VERSION ""

NS_ :

BS_:

BU_: UWB_RL UWB_FRNK UWB_RR UWB_INT DHR DHL UWB_BLE BDC UWB_FL Devtool ROA WPC UWB_TRNK UWB_FR

BO_ 16 WPC_01: 8 WPC
 SG_ C_WPC_NFCDetection : 7|2@0+ (1,0) [0|2] ""  BDC,Devtool
 SG_ C_WPC_NFCReset : 3|1@0+ (1,0) [0|0] ""  BDC

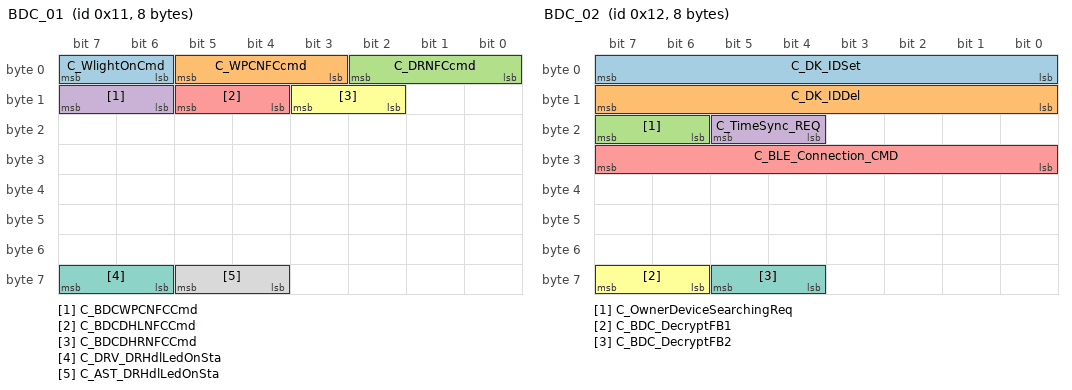
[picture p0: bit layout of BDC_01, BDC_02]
BO_ 17 BDC_01: 8 BDC
 SG_ C_WlightOnCmd : 7|2@0+ (1,0) [0|3] ""  DHL,DHR
 SG_ C_WPCNFCcmd : 5|3@0+ (1,0) [0|7] ""  WPC
 SG_ C_DRNFCcmd : 2|3@0+ (1,0) [0|7] ""  DHL,DHR
 SG_ C_BDCWPCNFCCmd : 15|2@0+ (1,0) [0|0] ""  WPC
 SG_ C_BDCDHLNFCCmd : 13|2@0+ (1,0) [0|0] ""  DHL
 SG_ C_BDCDHRNFCCmd : 11|2@0+ (1,0) [0|0] ""  DHR
 SG_ C_DRV_DRHdlLedOnSta : 63|2@0+ (1,0) [0|0] ""  DHL
 SG_ C_AST_DRHdlLedOnSta : 61|2@0+ (1,0) [0|0] ""  DHR

BO_ 18 BDC_02: 8 BDC
 SG_ C_DK_IDSet : 7|8@0+ (1,0) [0|0] ""  UWB_BLE
 SG_ C_DK_IDDel : 15|8@0+ (1,0) [0|0] ""  UWB_BLE
 SG_ C_OwnerDeviceSearchingReq : 23|2@0+ (1,0) [0|0] ""  UWB_BLE
 SG_ C_TimeSync_REQ : 21|2@0+ (1,0) [0|0] ""  UWB_BLE
 SG_ C_BLE_Connection_CMD : 31|8@0+ (1,0) [0|0] ""  UWB_BLE
 SG_ C_BDC_DecryptFB1 : 63|2@0+ (1,0) [0|0] ""  UWB_BLE
 SG_ C_BDC_DecryptFB2 : 61|2@0+ (1,0) [0|0] ""  UWB_BLE,UWB_FL,UWB_FR,UWB_FRNK,UWB_INT,UWB_RL,UWB_RR,UWB_TRNK

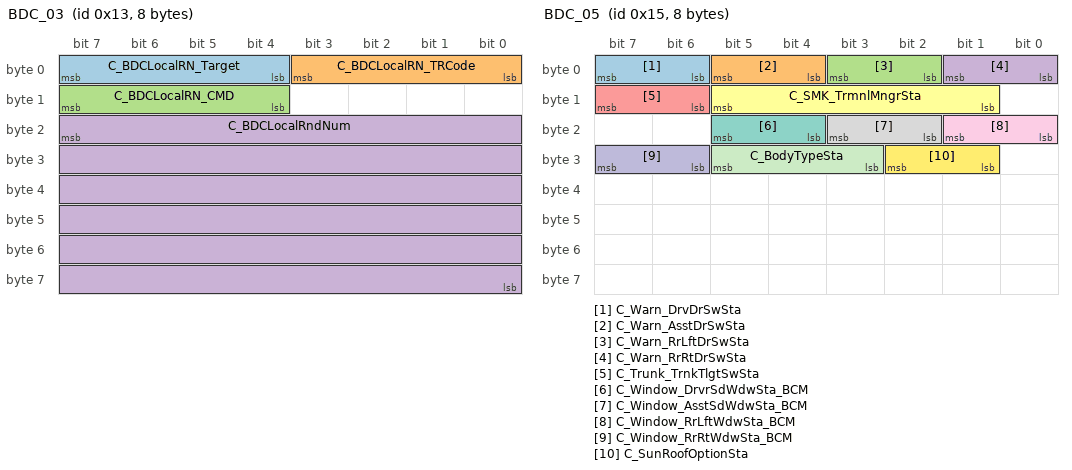
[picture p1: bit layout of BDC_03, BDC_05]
BO_ 19 BDC_03: 8 BDC
 SG_ C_BDCLocalRN_Target : 7|4@0+ (1,0) [0|0] ""  UWB_BLE,UWB_FL,UWB_FR,UWB_FRNK,UWB_INT,UWB_RL,UWB_RR,UWB_TRNK
 SG_ C_BDCLocalRN_TRCode : 3|4@0+ (1,0) [0|0] ""  UWB_BLE,UWB_FL,UWB_FR,UWB_FRNK,UWB_INT,UWB_RL,UWB_RR,UWB_TRNK
 SG_ C_BDCLocalRN_CMD : 15|4@0+ (1,0) [0|0] ""  UWB_BLE,UWB_FL,UWB_FR,UWB_FRNK,UWB_INT,UWB_RL,UWB_RR,UWB_TRNK
 SG_ C_BDCLocalRndNum : 23|48@0+ (1,0) [0|0] ""  UWB_BLE,UWB_FL,UWB_FR,UWB_FRNK,UWB_INT,UWB_RL,UWB_RR,UWB_TRNK

BO_ 20 BDC_04: 8 BDC
 SG_ C_UWB_Ranging_CMD_ID : 7|8@0+ (1,0) [0|0] ""  UWB_BLE,UWB_FL,UWB_FR,UWB_FRNK,UWB_INT,UWB_RL,UWB_RR,UWB_TRNK
 SG_ C_UWB_Ranging_CMD_Value : 15|56@0+ (1,0) [0|0] ""  UWB_BLE,UWB_FL,UWB_FR,UWB_FRNK,UWB_INT,UWB_RL,UWB_RR,UWB_TRNK

BO_ 21 BDC_05: 8 BDC
 SG_ C_Warn_DrvDrSwSta : 7|2@0+ (1,0) [0|0] ""  UWB_BLE
 SG_ C_Warn_AsstDrSwSta : 5|2@0+ (1,0) [0|0] ""  UWB_BLE
 SG_ C_Warn_RrLftDrSwSta : 3|2@0+ (1,0) [0|0] ""  UWB_BLE
 SG_ C_Warn_RrRtDrSwSta : 1|2@0+ (1,0) [0|0] ""  UWB_BLE
 SG_ C_Trunk_TrnkTlgtSwSta : 15|2@0+ (1,0) [0|0] ""  UWB_BLE
 SG_ C_SMK_TrmnlMngrSta : 13|5@0+ (1,0) [0|0] ""  ROA,UWB_BLE
 SG_ C_Window_DrvrSdWdwSta_BCM : 21|2@0+ (1,0) [0|0] ""  UWB_BLE
 SG_ C_Window_AsstSdWdwSta_BCM : 19|2@0+ (1,0) [0|0] ""  UWB_BLE
 SG_ C_Window_RrLftWdwSta_BCM : 17|2@0+ (1,0) [0|0] ""  UWB_BLE
 SG_ C_Window_RrRtWdwSta_BCM : 31|2@0+ (1,0) [0|0] ""  UWB_BLE
 SG_ C_BodyTypeSta : 29|3@0+ (1,0) [0|0] ""  UWB_BLE
 SG_ C_SunRoofOptionSta : 26|2@0+ (1,0) [0|0] ""  ROA,UWB_BLE

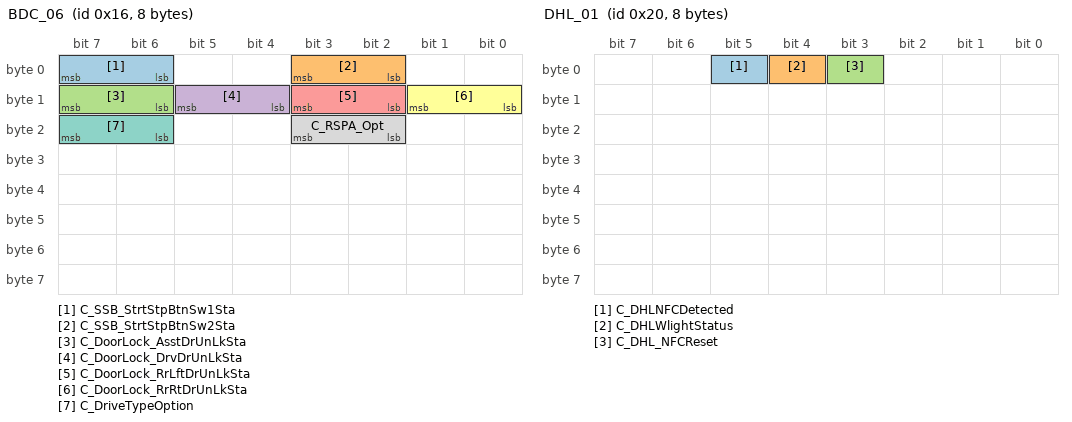
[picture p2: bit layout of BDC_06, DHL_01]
BO_ 22 BDC_06: 8 BDC
 SG_ C_SSB_StrtStpBtnSw1Sta : 7|2@0+ (1,0) [0|0] ""  UWB_BLE
 SG_ C_SSB_StrtStpBtnSw2Sta : 3|2@0+ (1,0) [0|0] ""  UWB_BLE
 SG_ C_DoorLock_AsstDrUnLkSta : 15|2@0+ (1,0) [0|0] ""  UWB_BLE
 SG_ C_DoorLock_DrvDrUnLkSta : 13|2@0+ (1,0) [0|0] ""  UWB_BLE
 SG_ C_DoorLock_RrLftDrUnLkSta : 11|2@0+ (1,0) [0|0] ""  UWB_BLE
 SG_ C_DoorLock_RrRtDrUnLkSta : 9|2@0+ (1,0) [0|0] ""  UWB_BLE
 SG_ C_DriveTypeOption : 23|2@0+ (1,0) [0|0] ""  UWB_BLE
 SG_ C_RSPA_Opt : 19|2@0+ (1,0) [0|0] ""  UWB_BLE

BO_ 31 BDC_20: 8 BDC
 SG_ BDCToBLEEncryptData1 : 7|64@0+ (1,0) [0|0] ""  UWB_BLE

BO_ 32 DHL_01: 8 DHL
 SG_ C_DHLNFCDetected : 5|1@0+ (1,0) [0|1] ""  BDC
 SG_ C_DHLWlightStatus : 4|1@0+ (1,0) [0|1] ""  BDC
 SG_ C_DHL_NFCReset : 3|1@0+ (1,0) [0|0] ""  BDC

BO_ 33 BDC_21: 8 BDC
 SG_ BDCToBLEEncryptData2 : 7|64@0+ (1,0) [0|0] ""  UWB_BLE

BO_ 34 BDC_22: 8 BDC
 SG_ BDCToBLEEncryptData3 : 7|64@0+ (1,0) [0|0] ""  UWB_BLE

BO_ 35 BDC_23: 8 BDC
 SG_ BDCToBLEEncryptData4 : 7|64@0+ (1,0) [0|0] ""  UWB_BLE

BO_ 36 BDC_24: 8 BDC
 SG_ BDCToBLEEncryptData5 : 7|64@0+ (1,0) [0|0] ""  UWB_BLE

BO_ 37 BDC_25: 8 BDC
 SG_ BDCToBLEEncryptData6 : 7|64@0+ (1,0) [0|0] ""  UWB_BLE

BO_ 38 BDC_26: 8 BDC
 SG_ BDCToUWBEncryptData1 : 7|64@0+ (1,0) [0|0] ""  UWB_BLE,UWB_FL,UWB_FR,UWB_FRNK,UWB_INT,UWB_RL,UWB_RR,UWB_TRNK

BO_ 39 BDC_27: 8 BDC
 SG_ BDCToUWBEncryptData2 : 7|64@0+ (1,0) [0|0] ""  UWB_BLE,UWB_FL,UWB_FR,UWB_FRNK,UWB_INT,UWB_RL,UWB_RR,UWB_TRNK

BO_ 40 BDC_28: 8 BDC
 SG_ BDCToUWBEncryptData3 : 7|64@0+ (1,0) [0|0] ""  UWB_BLE,UWB_FL,UWB_FR,UWB_FRNK,UWB_INT,UWB_RL,UWB_RR,UWB_TRNK

BO_ 41 BDC_29: 8 BDC
 SG_ BDCToUWBEncryptData4 : 7|64@0+ (1,0) [0|0] ""  UWB_BLE,UWB_FL,UWB_FR,UWB_FRNK,UWB_INT,UWB_RL,UWB_RR,UWB_TRNK

BO_ 47 BDC_30: 8 BDC
 SG_ BDCToUWBEncryptData5 : 7|64@0+ (1,0) [0|0] ""  UWB_BLE,UWB_FL,UWB_FR,UWB_FRNK,UWB_INT,UWB_RL,UWB_RR,UWB_TRNK

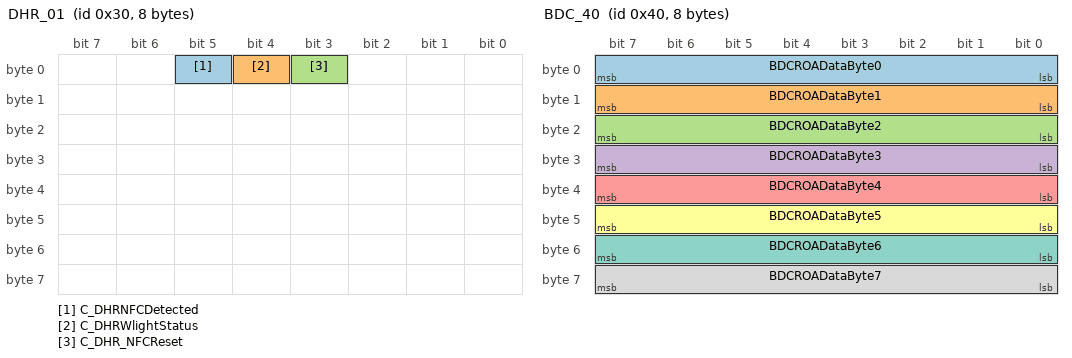
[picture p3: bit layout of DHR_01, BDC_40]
BO_ 48 DHR_01: 8 DHR
 SG_ C_DHRNFCDetected : 5|1@0+ (1,0) [0|1] ""  BDC
 SG_ C_DHRWlightStatus : 4|1@0+ (1,0) [0|1] ""  BDC
 SG_ C_DHR_NFCReset : 3|1@0+ (1,0) [0|0] ""  BDC

BO_ 49 BDC_31: 8 BDC
 SG_ BDCToUWBEncryptData6 : 7|64@0+ (1,0) [0|0] ""  UWB_BLE,UWB_FL,UWB_FR,UWB_FRNK,UWB_INT,UWB_RL,UWB_RR,UWB_TRNK

BO_ 64 BDC_40: 8 BDC
 SG_ BDCROADataByte0 : 7|8@0+ (1,0) [0|0] ""  ROA
 SG_ BDCROADataByte1 : 15|8@0+ (1,0) [0|0] ""  ROA
 SG_ BDCROADataByte2 : 23|8@0+ (1,0) [0|0] ""  ROA
 SG_ BDCROADataByte3 : 31|8@0+ (1,0) [0|0] ""  ROA
 SG_ BDCROADataByte4 : 39|8@0+ (1,0) [0|0] ""  ROA
 SG_ BDCROADataByte5 : 47|8@0+ (1,0) [0|0] ""  ROA
 SG_ BDCROADataByte6 : 55|8@0+ (1,0) [0|0] ""  ROA
 SG_ BDCROADataByte7 : 63|8@0+ (1,0) [0|0] ""  ROA

BO_ 96 BLE_1: 8 UWB_BLE
 SG_ C_BLENewDevicePairingResult : 23|2@0+ (1,0) [0|0] ""  BDC
 SG_ C_BLE_Decrypt_FB : 63|4@0+ (1,0) [0|0] ""  BDC

BO_ 111 BLE_20: 8 UWB_BLE
 SG_ BLEToBDCEncryptData1 : 7|64@0+ (1,0) [0|0] ""  BDC

BO_ 112 BLE_2: 8 UWB_BLE
 SG_ C_Time_Sync1 : 7|64@0+ (1,0) [0|0] ""  BDC,UWB_FL,UWB_FR,UWB_FRNK,UWB_INT,UWB_RL,UWB_RR,UWB_TRNK

BO_ 113 BLE_21: 8 UWB_BLE
 SG_ BLEToBDCEncryptData2 : 7|64@0+ (1,0) [0|0] ""  BDC

BO_ 114 BLE_22: 8 UWB_BLE
 SG_ BLEToBDCEncryptData3 : 7|64@0+ (1,0) [0|0] ""  BDC

BO_ 115 BLE_23: 8 UWB_BLE
 SG_ BLEToBDCEncryptData4 : 7|64@0+ (1,0) [0|0] ""  BDC

BO_ 116 BLE_24: 8 UWB_BLE
 SG_ BLEToBDCEncryptData5 : 7|64@0+ (1,0) [0|0] ""  BDC

BO_ 117 BLE_25: 8 UWB_BLE
 SG_ BLEToBDCEncryptData6 : 7|64@0+ (1,0) [0|0] ""  BDC

BO_ 128 BLE_3: 8 UWB_BLE
 SG_ C_Time_Sync2 : 7|64@0+ (1,0) [0|0] ""  BDC,UWB_FL,UWB_FR,UWB_FRNK,UWB_INT,UWB_RL,UWB_RR,UWB_TRNK

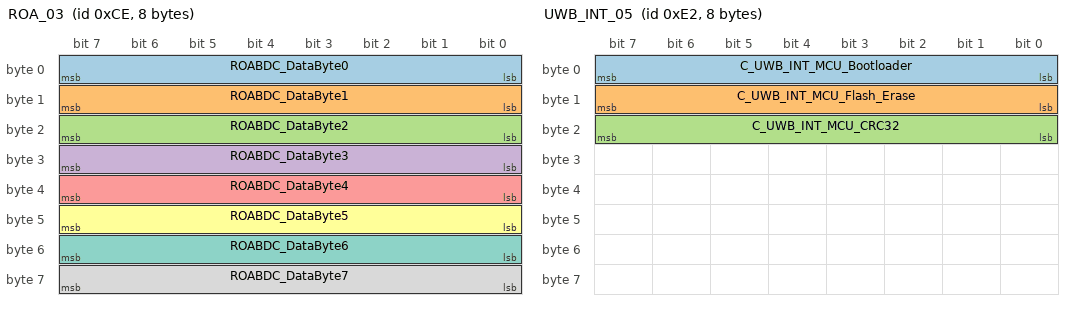
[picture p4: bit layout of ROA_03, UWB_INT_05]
BO_ 206 ROA_03: 8 ROA
 SG_ ROABDC_DataByte0 : 7|8@0+ (1,0) [0|0] ""  BDC
 SG_ ROABDC_DataByte1 : 15|8@0+ (1,0) [0|0] ""  BDC
 SG_ ROABDC_DataByte2 : 23|8@0+ (1,0) [0|0] ""  BDC
 SG_ ROABDC_DataByte3 : 31|8@0+ (1,0) [0|0] ""  BDC
 SG_ ROABDC_DataByte4 : 39|8@0+ (1,0) [0|0] ""  BDC
 SG_ ROABDC_DataByte5 : 47|8@0+ (1,0) [0|0] ""  BDC
 SG_ ROABDC_DataByte6 : 55|8@0+ (1,0) [0|0] ""  BDC
 SG_ ROABDC_DataByte7 : 63|8@0+ (1,0) [0|0] ""  BDC

BO_ 209 UWB_MASTER_01: 8 UWB_BLE
 SG_ C_UWB_MASTER_Decrypt_FB : 63|4@0+ (1,0) [0|0] ""  BDC

BO_ 210 UWB_MASTER_04: 8 UWB_BLE
 SG_ C_UWB_MASTER_To_BDCFOBRSDResul : 7|64@0+ (1,0) [0|0] ""  BDC

BO_ 211 UWB_MASTER_05: 8 UWB_BLE
 SG_ C_UWB_MCU_OTA_Cmd : 7|4@0+ (1,0) [0|0] ""  UWB_FL,UWB_FR,UWB_FRNK,UWB_INT,UWB_RL,UWB_RR,UWB_TRNK

BO_ 212 UWB_MASTER_06: 8 UWB_BLE
 SG_ C_UWB_IC_OTA_Cmd : 15|4@0+ (1,0) [0|0] ""  UWB_FL,UWB_FR,UWB_FRNK,UWB_INT,UWB_RL,UWB_RR,UWB_TRNK

BO_ 213 UWB_MASTER_07: 8 UWB_BLE
 SG_ C_UWB_MCU_Download_Data : 7|64@0+ (1,0) [0|0] ""  UWB_FL,UWB_FR,UWB_FRNK,UWB_INT,UWB_RL,UWB_RR,UWB_TRNK

BO_ 214 UWB_MASTER_08: 8 UWB_BLE
 SG_ C_UWB_IC_Download_Data : 7|64@0+ (1,0) [0|0] ""  UWB_FL,UWB_FR,UWB_FRNK,UWB_INT,UWB_RL,UWB_RR,UWB_TRNK

BO_ 224 UWB_INT_01: 8 UWB_INT
 SG_ C_UWB_INT_Decrypt_FB : 63|4@0+ (1,0) [0|0] ""  BDC,UWB_BLE

BO_ 225 UWB_INT_04: 8 UWB_INT
 SG_ C_UWB_INT_To_BDCFOBRSDResult : 7|64@0+ (1,0) [0|0] ""  BDC

BO_ 226 UWB_INT_05: 8 UWB_INT
 SG_ C_UWB_INT_MCU_Bootloader : 7|8@0+ (1,0) [0|0] ""  UWB_BLE
 SG_ C_UWB_INT_MCU_Flash_Erase : 15|8@0+ (1,0) [0|0] ""  UWB_BLE
 SG_ C_UWB_INT_MCU_CRC32 : 23|8@0+ (1,0) [0|0] ""  UWB_BLE

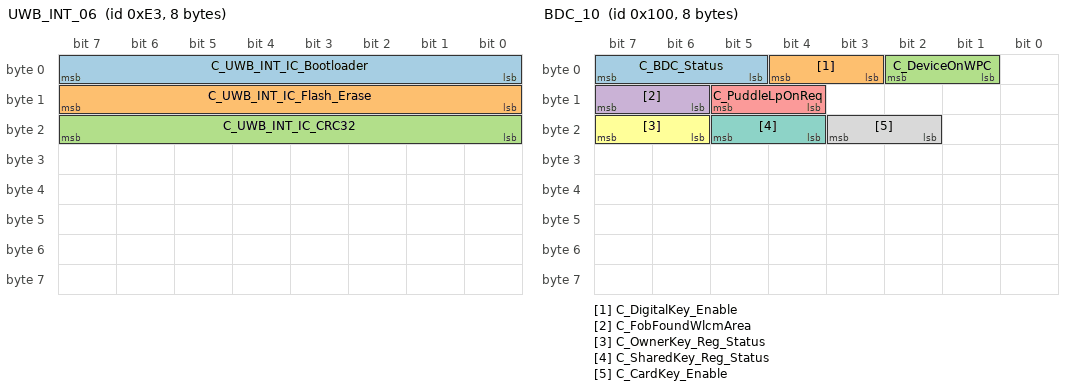
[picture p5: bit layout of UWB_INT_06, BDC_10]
BO_ 227 UWB_INT_06: 8 UWB_INT
 SG_ C_UWB_INT_IC_Bootloader : 7|8@0+ (1,0) [0|0] ""  UWB_BLE
 SG_ C_UWB_INT_IC_Flash_Erase : 15|8@0+ (1,0) [0|0] ""  UWB_BLE
 SG_ C_UWB_INT_IC_CRC32 : 23|8@0+ (1,0) [0|0] ""  UWB_BLE

BO_ 235 UWB_INT_03: 8 UWB_INT
 SG_ C_UWB_INT_To_MasterEncData2 : 7|64@0+ (1,0) [0|0] ""  UWB_BLE

BO_ 256 BDC_10: 8 BDC
 SG_ C_BDC_Status : 7|3@0+ (1,0) [0|7] ""  DHL,DHR,UWB_BLE,UWB_FL,UWB_FR,UWB_FRNK,UWB_INT,UWB_RL,UWB_RR,UWB_TRNK,WPC
 SG_ C_DigitalKey_Enable : 4|2@0+ (1,0) [0|3] ""  DHL,DHR,UWB_BLE,UWB_FL,UWB_FR,UWB_FRNK,UWB_INT,UWB_RL,UWB_RR,UWB_TRNK
 SG_ C_DeviceOnWPC : 2|2@0+ (1,0) [0|0] ""  Devtool,WPC
 SG_ C_FobFoundWlcmArea : 15|2@0+ (1,0) [0|3] ""  DHL,DHR
 SG_ C_PuddleLpOnReq : 13|2@0+ (1,0) [0|0] ""  DHL,DHR
 SG_ C_OwnerKey_Reg_Status : 23|2@0+ (1,0) [0|0] ""  DHL,DHR,UWB_BLE,UWB_FL,UWB_FR,UWB_FRNK,UWB_INT,UWB_RL,UWB_RR,UWB_TRNK
 SG_ C_SharedKey_Reg_Status : 21|2@0+ (1,0) [0|0] ""  DHL,DHR,UWB_BLE,UWB_FL,UWB_FR,UWB_FRNK,UWB_INT,UWB_RL,UWB_RR,UWB_TRNK
 SG_ C_CardKey_Enable : 19|2@0+ (1,0) [0|3] ""  DHL,DHR

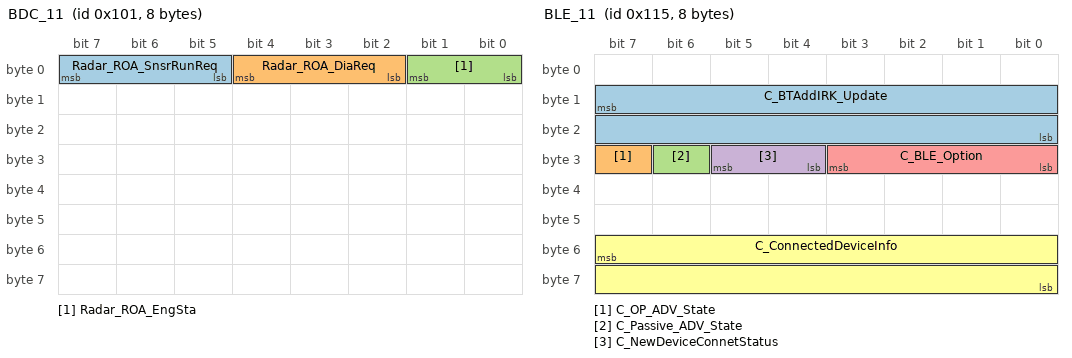
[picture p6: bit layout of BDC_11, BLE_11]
BO_ 257 BDC_11: 8 BDC
 SG_ Radar_ROA_SnsrRunReq : 7|3@0+ (1,0) [0|7] ""  ROA
 SG_ Radar_ROA_DiaReq : 4|3@0+ (1,0) [0|7] ""  ROA
 SG_ Radar_ROA_EngSta : 1|2@0+ (1,0) [0|3] ""  ROA

BO_ 272 WPC_10: 8 WPC
 SG_ C_WPC_Status : 7|3@0+ (1,0) [0|7] ""  BDC,Devtool
 SG_ C_WPCNFC_Option : 15|2@0+ (1,0) [0|3] ""  BDC

BO_ 277 BLE_11: 8 UWB_BLE
 SG_ C_BTAddIRK_Update : 15|16@0+ (1,0) [0|0] ""  BDC
 SG_ C_OP_ADV_State : 31|1@0+ (1,0) [0|0] ""  BDC
 SG_ C_Passive_ADV_State : 30|1@0+ (1,0) [0|0] ""  BDC
 SG_ C_NewDeviceConnetStatus : 29|2@0+ (1,0) [0|0] ""  BDC
 SG_ C_BLE_Option : 27|4@0+ (1,0) [0|0] ""  BDC
 SG_ C_ConnectedDeviceInfo : 55|16@0+ (1,0) [0|0] ""  BDC

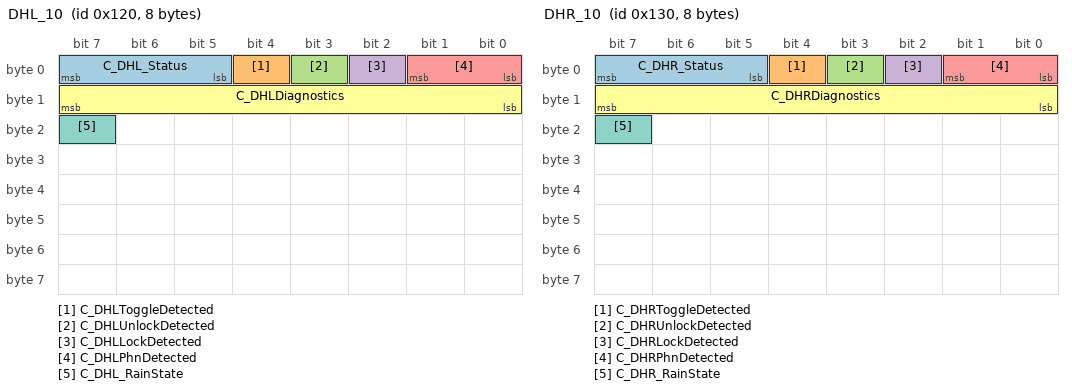
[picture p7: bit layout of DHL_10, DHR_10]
BO_ 288 DHL_10: 8 DHL
 SG_ C_DHL_Status : 7|3@0+ (1,0) [0|7] ""  BDC
 SG_ C_DHLToggleDetected : 4|1@0+ (1,0) [0|0] ""  BDC,UWB_BLE
 SG_ C_DHLUnlockDetected : 3|1@0+ (1,0) [0|1] ""  BDC,UWB_BLE
 SG_ C_DHLLockDetected : 2|1@0+ (1,0) [0|1] ""  BDC,UWB_BLE
 SG_ C_DHLPhnDetected : 1|2@0+ (1,0) [0|0] ""  BDC
 SG_ C_DHLDiagnostics : 15|8@0+ (1,0) [0|0] ""  BDC
 SG_ C_DHL_RainState : 23|1@0+ (1,0) [0|0] ""  BDC

BO_ 304 DHR_10: 8 DHR
 SG_ C_DHR_Status : 7|3@0+ (1,0) [0|7] ""  BDC
 SG_ C_DHRToggleDetected : 4|1@0+ (1,0) [0|1] ""  BDC,UWB_BLE
 SG_ C_DHRUnlockDetected : 3|1@0+ (1,0) [0|1] ""  BDC,UWB_BLE
 SG_ C_DHRLockDetected : 2|1@0+ (1,0) [0|1] ""  BDC,UWB_BLE
 SG_ C_DHRPhnDetected : 1|2@0+ (1,0) [0|0] ""  BDC
 SG_ C_DHRDiagnostics : 15|8@0+ (1,0) [0|0] ""  BDC
 SG_ C_DHR_RainState : 23|1@0+ (1,0) [0|1] ""  BDC

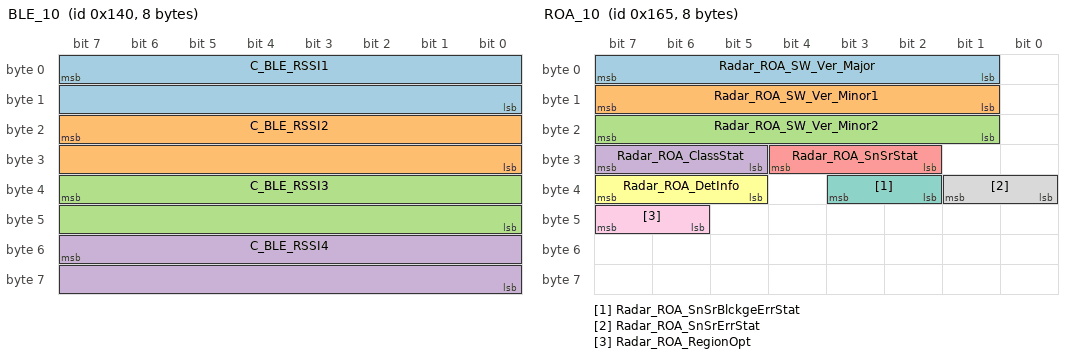
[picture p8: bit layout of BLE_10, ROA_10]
BO_ 320 BLE_10: 8 UWB_BLE
 SG_ C_BLE_RSSI1 : 7|16@0+ (1,0) [0|0] ""  BDC
 SG_ C_BLE_RSSI2 : 23|16@0+ (1,0) [0|0] ""  BDC
 SG_ C_BLE_RSSI3 : 39|16@0+ (1,0) [0|0] ""  BDC
 SG_ C_BLE_RSSI4 : 55|16@0+ (1,0) [0|0] ""  BDC

BO_ 353 UWB_FRNK_01: 8 UWB_FRNK
 SG_ C_UWB_FRNK_Decrypt_FB : 63|4@0+ (1,0) [0|0] ""  BDC,UWB_BLE

BO_ 354 UWB_FRNK_02: 8 UWB_FRNK
 SG_ C_UWB_FRNK_To_MasterEncData1 : 7|64@0+ (1,0) [0|0] ""  UWB_BLE

BO_ 355 UWB_FRNK_03: 8 UWB_FRNK
 SG_ C_UWB_FRNK_To_MasterEncData2 : 7|64@0+ (1,0) [0|0] ""  UWB_BLE

BO_ 356 UWB_FRNK_04: 8 UWB_FRNK
 SG_ C_UWB_FRNK_To_BDCFOBRSDResult : 7|64@0+ (1,0) [0|0] ""  BDC

BO_ 357 ROA_10: 8 ROA
 SG_ Radar_ROA_SW_Ver_Major : 7|7@0+ (1,0) [0|127] ""  BDC
 SG_ Radar_ROA_SW_Ver_Minor1 : 15|7@0+ (1,0) [0|127] ""  BDC
 SG_ Radar_ROA_SW_Ver_Minor2 : 23|7@0+ (1,0) [0|127] ""  BDC
 SG_ Radar_ROA_ClassStat : 31|3@0+ (1,0) [0|7] ""  BDC
 SG_ Radar_ROA_SnSrStat : 28|3@0+ (1,0) [0|7] ""  BDC
 SG_ Radar_ROA_DetInfo : 39|3@0+ (1,0) [0|7] ""  BDC
 SG_ Radar_ROA_SnSrBlckgeErrStat : 35|2@0+ (1,0) [0|3] ""  BDC
 SG_ Radar_ROA_SnSrErrStat : 33|2@0+ (1,0) [0|3] ""  BDC
 SG_ Radar_ROA_RegionOpt : 47|2@0+ (1,0) [0|3] ""  BDC

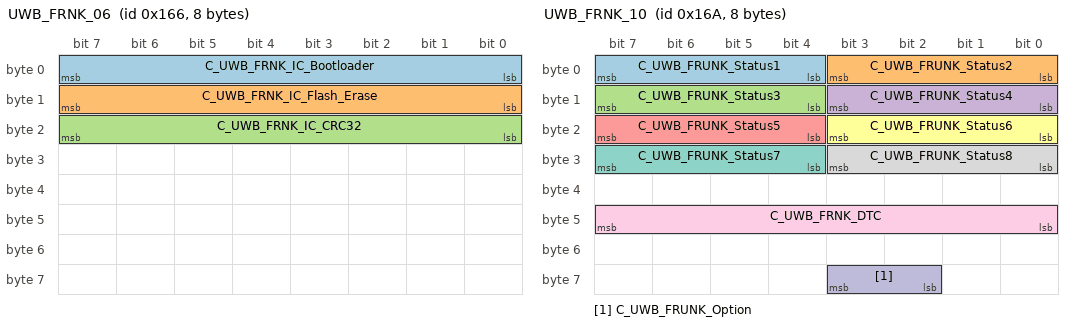
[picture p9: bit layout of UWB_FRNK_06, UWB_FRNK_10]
BO_ 358 UWB_FRNK_06: 8 UWB_FRNK
 SG_ C_UWB_FRNK_IC_Bootloader : 7|8@0+ (1,0) [0|0] ""  UWB_BLE
 SG_ C_UWB_FRNK_IC_Flash_Erase : 15|8@0+ (1,0) [0|0] ""  UWB_BLE
 SG_ C_UWB_FRNK_IC_CRC32 : 23|8@0+ (1,0) [0|0] ""  UWB_BLE

BO_ 362 UWB_FRNK_10: 8 UWB_FRNK
 SG_ C_UWB_FRUNK_Status1 : 7|4@0+ (1,0) [0|7] ""  BDC,UWB_BLE
 SG_ C_UWB_FRUNK_Status2 : 3|4@0+ (1,0) [0|7] ""  BDC,UWB_BLE
 SG_ C_UWB_FRUNK_Status3 : 15|4@0+ (1,0) [0|7] ""  BDC,UWB_BLE
 SG_ C_UWB_FRUNK_Status4 : 11|4@0+ (1,0) [0|7] ""  BDC,UWB_BLE
 SG_ C_UWB_FRUNK_Status5 : 23|4@0+ (1,0) [0|7] ""  BDC,UWB_BLE
 SG_ C_UWB_FRUNK_Status6 : 19|4@0+ (1,0) [0|7] ""  BDC,UWB_BLE
 SG_ C_UWB_FRUNK_Status7 : 31|4@0+ (1,0) [0|7] ""  BDC,UWB_BLE
 SG_ C_UWB_FRUNK_Status8 : 27|4@0+ (1,0) [0|7] ""  BDC,UWB_BLE
 SG_ C_UWB_FRNK_DTC : 47|8@0+ (1,0) [0|0] ""  UWB_BLE
 SG_ C_UWB_FRUNK_Option : 59|2@0+ (1,0) [0|3] ""  BDC,UWB_BLE

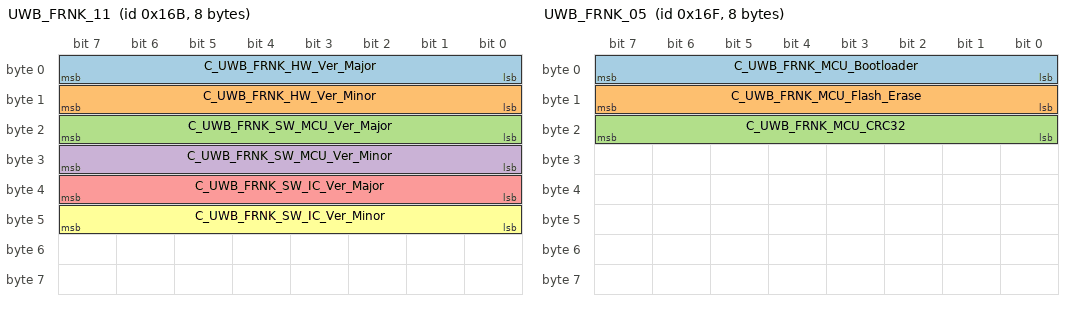
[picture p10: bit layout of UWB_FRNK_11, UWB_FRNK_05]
BO_ 363 UWB_FRNK_11: 8 UWB_FRNK
 SG_ C_UWB_FRNK_HW_Ver_Major : 7|8@0+ (1,0) [0|7] ""  UWB_BLE
 SG_ C_UWB_FRNK_HW_Ver_Minor : 15|8@0+ (1,0) [0|7] ""  UWB_BLE
 SG_ C_UWB_FRNK_SW_MCU_Ver_Major : 23|8@0+ (1,0) [0|7] ""  UWB_BLE
 SG_ C_UWB_FRNK_SW_MCU_Ver_Minor : 31|8@0+ (1,0) [0|7] ""  UWB_BLE
 SG_ C_UWB_FRNK_SW_IC_Ver_Major : 39|8@0+ (1,0) [0|7] ""  UWB_BLE
 SG_ C_UWB_FRNK_SW_IC_Ver_Minor : 47|8@0+ (1,0) [0|7] ""  UWB_BLE

BO_ 367 UWB_FRNK_05: 8 UWB_FRNK
 SG_ C_UWB_FRNK_MCU_Bootloader : 7|8@0+ (1,0) [0|0] ""  UWB_BLE
 SG_ C_UWB_FRNK_MCU_Flash_Erase : 15|8@0+ (1,0) [0|0] ""  UWB_BLE
 SG_ C_UWB_FRNK_MCU_CRC32 : 23|8@0+ (1,0) [0|0] ""  UWB_BLE

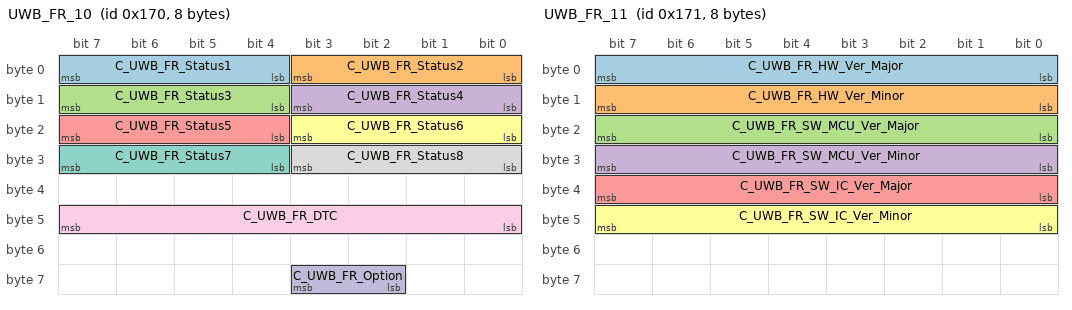
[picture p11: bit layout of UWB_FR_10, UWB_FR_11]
BO_ 368 UWB_FR_10: 8 UWB_FR
 SG_ C_UWB_FR_Status1 : 7|4@0+ (1,0) [0|7] ""  BDC,UWB_BLE
 SG_ C_UWB_FR_Status2 : 3|4@0+ (1,0) [0|7] ""  BDC,UWB_BLE
 SG_ C_UWB_FR_Status3 : 15|4@0+ (1,0) [0|7] ""  BDC,UWB_BLE
 SG_ C_UWB_FR_Status4 : 11|4@0+ (1,0) [0|7] ""  BDC,UWB_BLE
 SG_ C_UWB_FR_Status5 : 23|4@0+ (1,0) [0|7] ""  BDC,UWB_BLE
 SG_ C_UWB_FR_Status6 : 19|4@0+ (1,0) [0|7] ""  BDC,UWB_BLE
 SG_ C_UWB_FR_Status7 : 31|4@0+ (1,0) [0|7] ""  BDC,UWB_BLE
 SG_ C_UWB_FR_Status8 : 27|4@0+ (1,0) [0|7] ""  BDC,UWB_BLE
 SG_ C_UWB_FR_DTC : 47|8@0+ (1,0) [0|0] ""  UWB_BLE
 SG_ C_UWB_FR_Option : 59|2@0+ (1,0) [0|0] ""  BDC,UWB_BLE

BO_ 369 UWB_FR_11: 8 UWB_FR
 SG_ C_UWB_FR_HW_Ver_Major : 7|8@0+ (1,0) [0|7] ""  UWB_BLE
 SG_ C_UWB_FR_HW_Ver_Minor : 15|8@0+ (1,0) [0|7] ""  UWB_BLE
 SG_ C_UWB_FR_SW_MCU_Ver_Major : 23|8@0+ (1,0) [0|7] ""  UWB_BLE
 SG_ C_UWB_FR_SW_MCU_Ver_Minor : 31|8@0+ (1,0) [0|7] ""  UWB_BLE
 SG_ C_UWB_FR_SW_IC_Ver_Major : 39|8@0+ (1,0) [0|7] ""  UWB_BLE
 SG_ C_UWB_FR_SW_IC_Ver_Minor : 47|8@0+ (1,0) [0|7] ""  UWB_BLE

BO_ 370 UWB_FL_02: 8 UWB_FL
 SG_ C_UWB_FL_To_MaseterEncData1 : 7|64@0+ (1,0) [0|0] ""  UWB_BLE

BO_ 371 UWB_FL_03: 8 UWB_FL
 SG_ C_UWB_FL_To_MasterEncData2 : 7|64@0+ (1,0) [0|0] ""  UWB_BLE

BO_ 372 UWB_FL_04: 8 UWB_FL
 SG_ C_UWB_FL_To_BDCFOBRSDResult : 7|64@0+ (1,0) [0|0] ""  BDC

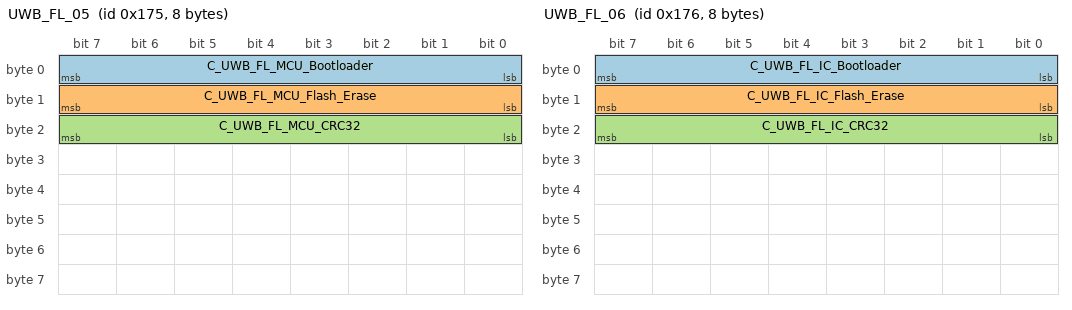
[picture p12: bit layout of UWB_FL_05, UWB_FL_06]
BO_ 373 UWB_FL_05: 8 UWB_FL
 SG_ C_UWB_FL_MCU_Bootloader : 7|8@0+ (1,0) [0|0] ""  UWB_BLE
 SG_ C_UWB_FL_MCU_Flash_Erase : 15|8@0+ (1,0) [0|0] ""  UWB_BLE
 SG_ C_UWB_FL_MCU_CRC32 : 23|8@0+ (1,0) [0|0] ""  UWB_BLE

BO_ 374 UWB_FL_06: 8 UWB_FL
 SG_ C_UWB_FL_IC_Bootloader : 7|8@0+ (1,0) [0|0] ""  UWB_BLE
 SG_ C_UWB_FL_IC_Flash_Erase : 15|8@0+ (1,0) [0|0] ""  UWB_BLE
 SG_ C_UWB_FL_IC_CRC32 : 23|8@0+ (1,0) [0|0] ""  UWB_BLE

BO_ 375 UWB_FL_01: 8 UWB_FL
 SG_ C_UWB_FL_Decrypt_FB : 63|4@0+ (1,0) [0|0] ""  BDC,UWB_BLE

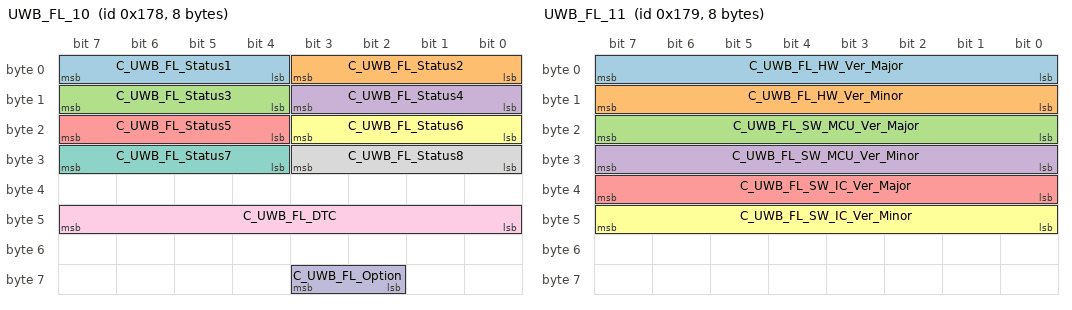
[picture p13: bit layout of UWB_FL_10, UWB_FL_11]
BO_ 376 UWB_FL_10: 8 UWB_FL
 SG_ C_UWB_FL_Status1 : 7|4@0+ (1,0) [0|7] ""  BDC,UWB_BLE
 SG_ C_UWB_FL_Status2 : 3|4@0+ (1,0) [0|7] ""  BDC,UWB_BLE
 SG_ C_UWB_FL_Status3 : 15|4@0+ (1,0) [0|7] ""  BDC,UWB_BLE
 SG_ C_UWB_FL_Status4 : 11|4@0+ (1,0) [0|7] ""  BDC,UWB_BLE
 SG_ C_UWB_FL_Status5 : 23|4@0+ (1,0) [0|7] ""  BDC,UWB_BLE
 SG_ C_UWB_FL_Status6 : 19|4@0+ (1,0) [0|7] ""  BDC,UWB_BLE
 SG_ C_UWB_FL_Status7 : 31|4@0+ (1,0) [0|7] ""  BDC,UWB_BLE
 SG_ C_UWB_FL_Status8 : 27|4@0+ (1,0) [0|7] ""  BDC,UWB_BLE
 SG_ C_UWB_FL_DTC : 47|8@0+ (1,0) [0|0] ""  UWB_BLE
 SG_ C_UWB_FL_Option : 59|2@0+ (1,0) [0|0] ""  BDC,UWB_BLE

BO_ 377 UWB_FL_11: 8 UWB_FL
 SG_ C_UWB_FL_HW_Ver_Major : 7|8@0+ (1,0) [0|7] ""  UWB_BLE
 SG_ C_UWB_FL_HW_Ver_Minor : 15|8@0+ (1,0) [0|7] ""  UWB_BLE
 SG_ C_UWB_FL_SW_MCU_Ver_Major : 23|8@0+ (1,0) [0|7] ""  UWB_BLE
 SG_ C_UWB_FL_SW_MCU_Ver_Minor : 31|8@0+ (1,0) [0|7] ""  UWB_BLE
 SG_ C_UWB_FL_SW_IC_Ver_Major : 39|8@0+ (1,0) [0|7] ""  UWB_BLE
 SG_ C_UWB_FL_SW_IC_Ver_Minor : 47|8@0+ (1,0) [0|7] ""  UWB_BLE

BO_ 378 UWB_MASTER_20: 8 UWB_BLE
 SG_ C_UWB_BLE_MasterEncData1 : 7|64@0+ (1,0) [0|0] ""  Devtool

BO_ 379 UWB_MASTER_21: 8 UWB_BLE
 SG_ C_UWB_BLE_MasterEncData2 : 7|64@0+ (1,0) [0|0] ""  Devtool

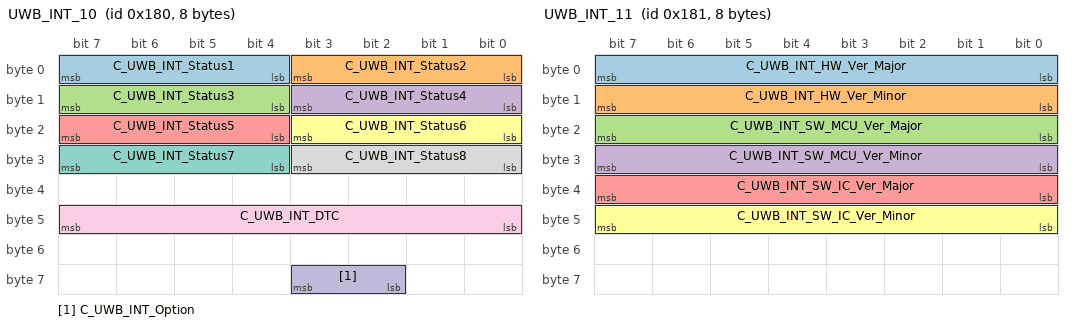
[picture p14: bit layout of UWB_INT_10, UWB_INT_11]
BO_ 384 UWB_INT_10: 8 UWB_INT
 SG_ C_UWB_INT_Status1 : 7|4@0+ (1,0) [0|7] ""  BDC,UWB_BLE
 SG_ C_UWB_INT_Status2 : 3|4@0+ (1,0) [0|7] ""  BDC,UWB_BLE
 SG_ C_UWB_INT_Status3 : 15|4@0+ (1,0) [0|7] ""  BDC,UWB_BLE
 SG_ C_UWB_INT_Status4 : 11|4@0+ (1,0) [0|7] ""  BDC,UWB_BLE
 SG_ C_UWB_INT_Status5 : 23|4@0+ (1,0) [0|7] ""  BDC,UWB_BLE
 SG_ C_UWB_INT_Status6 : 19|4@0+ (1,0) [0|7] ""  BDC,UWB_BLE
 SG_ C_UWB_INT_Status7 : 31|4@0+ (1,0) [0|7] ""  BDC,UWB_BLE
 SG_ C_UWB_INT_Status8 : 27|4@0+ (1,0) [0|7] ""  BDC,UWB_BLE
 SG_ C_UWB_INT_DTC : 47|8@0+ (1,0) [0|0] ""  UWB_BLE
 SG_ C_UWB_INT_Option : 59|2@0+ (1,0) [0|0] ""  BDC,UWB_BLE

BO_ 385 UWB_INT_11: 8 UWB_INT
 SG_ C_UWB_INT_HW_Ver_Major : 7|8@0+ (1,0) [0|7] ""  UWB_BLE
 SG_ C_UWB_INT_HW_Ver_Minor : 15|8@0+ (1,0) [0|7] ""  UWB_BLE
 SG_ C_UWB_INT_SW_MCU_Ver_Major : 23|8@0+ (1,0) [0|7] ""  UWB_BLE
 SG_ C_UWB_INT_SW_MCU_Ver_Minor : 31|8@0+ (1,0) [0|7] ""  UWB_BLE
 SG_ C_UWB_INT_SW_IC_Ver_Major : 39|8@0+ (1,0) [0|7] ""  UWB_BLE
 SG_ C_UWB_INT_SW_IC_Ver_Minor : 47|8@0+ (1,0) [0|7] ""  UWB_BLE

BO_ 386 UWB_FR_02: 8 UWB_FR
 SG_ C_UWB_FR_To_MasterEncData1 : 7|64@0+ (1,0) [0|0] ""  UWB_BLE

BO_ 387 UWB_FR_01: 8 UWB_FR
 SG_ C_UWB_FR_Decrypt_FB : 63|4@0+ (1,0) [0|0] ""  BDC,UWB_BLE

BO_ 388 UWB_FR_04: 8 UWB_FR
 SG_ C_UWB_FR_To_BDCFOBRSDResult : 7|64@0+ (1,0) [0|0] ""  BDC

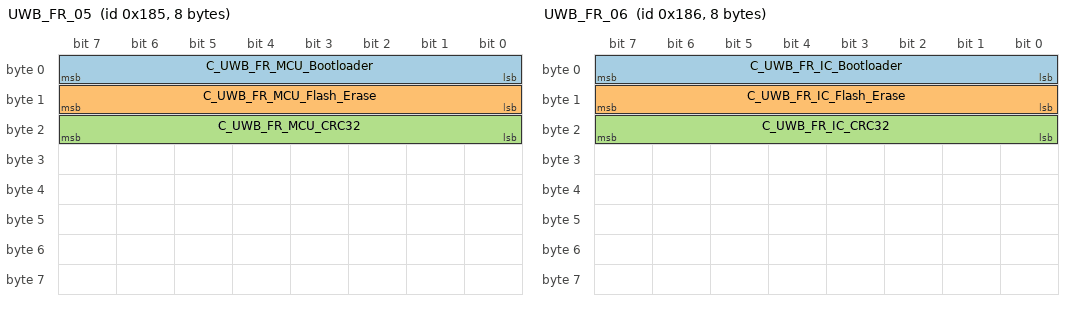
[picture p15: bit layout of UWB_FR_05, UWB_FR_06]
BO_ 389 UWB_FR_05: 8 UWB_FR
 SG_ C_UWB_FR_MCU_Bootloader : 7|8@0+ (1,0) [0|0] ""  UWB_BLE
 SG_ C_UWB_FR_MCU_Flash_Erase : 15|8@0+ (1,0) [0|0] ""  UWB_BLE
 SG_ C_UWB_FR_MCU_CRC32 : 23|8@0+ (1,0) [0|0] ""  UWB_BLE

BO_ 390 UWB_FR_06: 8 UWB_FR
 SG_ C_UWB_FR_IC_Bootloader : 7|8@0+ (1,0) [0|0] ""  UWB_BLE
 SG_ C_UWB_FR_IC_Flash_Erase : 15|8@0+ (1,0) [0|0] ""  UWB_BLE
 SG_ C_UWB_FR_IC_CRC32 : 23|8@0+ (1,0) [0|0] ""  UWB_BLE

BO_ 391 UWB_FR_03: 8 UWB_FR
 SG_ C_UWB_FR_To_MasterEncData2 : 7|64@0+ (1,0) [0|0] ""  UWB_BLE

CM_ BO_ 16 "[EC] On Event and On Change";
CM_ SG_ 16 C_WPC_NFCDetection "Indicate NFC Device is detected or not";
CM_ SG_ 16 C_WPC_NFCReset "NFC Deselect Result";
CM_ BO_ 17 "[EC] On Event and On Change";
CM_ SG_ 17 C_WlightOnCmd "Welcom Light On command from BDC";
CM_ SG_ 17 C_WPCNFCcmd "NFC Searchin Start/Stop command to WPC";
CM_ SG_ 17 C_DRNFCcmd "NFC Searchin Start/Stop command to DHL,DHR";
CM_ SG_ 17 C_BDCWPCNFCCmd "NFC Searchin Start/Stop command to WPC";
CM_ SG_ 17 C_BDCDHLNFCCmd "NFC Searchin Start/Stop command to DHL";
CM_ SG_ 17 C_BDCDHRNFCCmd "NFC Searchin Start/Stop command to DHR";
CM_ SG_ 17 C_DRV_DRHdlLedOnSta "Driver Door Handle Led On Status";
CM_ SG_ 17 C_AST_DRHdlLedOnSta "Assist Door Handle Led On Status";
CM_ BO_ 18 "[EC] On Event and On Change";
CM_ SG_ 18 C_DK_IDSet "BLE Module ID Setting";
CM_ SG_ 18 C_DK_IDDel "BLE Module ID Delete";
CM_ SG_ 18 C_OwnerDeviceSearchingReq "BLE Module Owner Pairing Start Cmd";
CM_ SG_ 18 C_TimeSync_REQ "Timer Sync Reqeust";
CM_ SG_ 18 C_BLE_Connection_CMD "BLE Module Conncetion Cmd";
CM_ SG_ 18 C_BDC_DecryptFB1 "BLE Enc Data Decryption Feed Back";
CM_ SG_ 18 C_BDC_DecryptFB2 "UWB Enc Data Decryption Feed Back";
CM_ BO_ 19 "[EC] On Event and On Change";
CM_ SG_ 19 C_BDCLocalRN_Target "Local Random Number Target Define";
CM_ SG_ 19 C_BDCLocalRN_TRCode "Local Random Number TRCode";
CM_ SG_ 19 C_BDCLocalRN_CMD "Local Random Number CMD";
CM_ SG_ 19 C_BDCLocalRndNum "Random Number for Encyption to BDC Local CAN Modules";
CM_ BO_ 20 "[EC] On Event and On Change";
CM_ SG_ 20 C_UWB_Ranging_CMD_ID "UWB Ranging CMD DKID";
CM_ SG_ 20 C_UWB_Ranging_CMD_Value "UWB Ranging CMD Value";
CM_ BO_ 21 "[PE] Periodic and On Event";
CM_ SG_ 21 C_Warn_DrvDrSwSta "DoorLock_DriverDoorSwitchStatus";
CM_ SG_ 21 C_Warn_AsstDrSwSta "Warn_AssistDoorSwitchStatus";
CM_ SG_ 21 C_Warn_RrLftDrSwSta "Warn_RearLeftDoorSwitchStatus";
CM_ SG_ 21 C_Warn_RrRtDrSwSta "Warn_RearRightDoorSwitchStatus";
CM_ SG_ 21 C_Trunk_TrnkTlgtSwSta "Trunk_TrunkTailgateSwitchStatus";
CM_ SG_ 21 C_SMK_TrmnlMngrSta "Terminal Manager Status";
CM_ SG_ 21 C_Window_DrvrSdWdwSta_BCM "Window_DriverSideWindowStatus";
CM_ SG_ 21 C_Window_AsstSdWdwSta_BCM "Window_AssistantSideWindowStatus";
CM_ SG_ 21 C_Window_RrLftWdwSta_BCM "Window_RearLeftWindowStatus";
CM_ SG_ 21 C_Window_RrRtWdwSta_BCM "Window_RearRightPowerWindowStatus";
CM_ SG_ 21 C_BodyTypeSta "Body & Bumper type Status";
CM_ SG_ 21 C_SunRoofOptionSta "Sunroof Option status";
CM_ BO_ 22 "[PE] Periodic and On Event";
CM_ SG_ 22 C_SSB_StrtStpBtnSw1Sta "SSB_StartStopButtonSwitch1Status ##2G##SMK - SMKmsg19 - C_SSBSW1";
CM_ SG_ 22 C_SSB_StrtStpBtnSw2Sta "SSB_StartStopButtonSwitch2Status ##2G##SMK - SMKmsg19 - C_SSBSW2";
CM_ SG_ 22 C_DoorLock_AsstDrUnLkSta "DoorLock_AssistDoorUnLockStatus ##2G## -  - C_AstUnlockState,DoorLock_AsstDrUnLkSta";
CM_ SG_ 22 C_DoorLock_DrvDrUnLkSta "DoorLock_DriverDoorUnLockStatus ##2G## -  - C_DrvUnlockState,CF_Gway_DrvUnlockState";
CM_ SG_ 22 C_DoorLock_RrLftDrUnLkSta "DoorLock_RearLeftDoorUnLockStatus ##2G## -  - C_RLUnlockState,DoorLock_RrLftDrUnLkSta";
CM_ SG_ 22 C_DoorLock_RrRtDrUnLkSta "DoorLock_RearRightDoorUnLockStatus ##2G## -  - C_RRUnlockState,DoorLock_RrRtDrUnLkSta";
CM_ SG_ 22 C_DriveTypeOption "##2G## -  - C_DriveTypeOption,CF_Gway_DriveTypeOption";
CM_ SG_ 22 C_RSPA_Opt "RSPA_Option";
CM_ BO_ 31 "[EC] On Event and On Change";
CM_ SG_ 31 BDCToBLEEncryptData1 "Encryption Data From BDC to BLE";
CM_ BO_ 32 "[EC] On Event and On Change";
CM_ SG_ 32 C_DHLNFCDetected "LH Door NFC Sensor Input";
CM_ SG_ 32 C_DHLWlightStatus "LH Door Welcome Light Status";
CM_ SG_ 32 C_DHL_NFCReset "LH Door NFC DeSelect Result";
CM_ BO_ 33 "[EC] On Event and On Change";
CM_ SG_ 33 BDCToBLEEncryptData2 "Encryption Data From BDC to BLE";
CM_ BO_ 34 "[EC] On Event and On Change";
CM_ SG_ 34 BDCToBLEEncryptData3 "Encryption Data From BDC to BLE";
CM_ BO_ 35 "[EC] On Event and On Change";
CM_ SG_ 35 BDCToBLEEncryptData4 "Encryption Data From BDC to BLE";
CM_ BO_ 36 "[EC] On Event and On Change";
CM_ SG_ 36 BDCToBLEEncryptData5 "Encryption Data From BDC to BLE";
CM_ BO_ 37 "[EC] On Event and On Change";
CM_ SG_ 37 BDCToBLEEncryptData6 "Encryption Data From BDC to BLE";
CM_ BO_ 38 "[EC] On Event and On Change";
CM_ SG_ 38 BDCToUWBEncryptData1 "Encryption Data From BDC to UWB ALL";
CM_ BO_ 39 "[EC] On Event and On Change";
CM_ SG_ 39 BDCToUWBEncryptData2 "Encryption Data From BDC to UWB ALL";
CM_ BO_ 40 "[EC] On Event and On Change";
CM_ SG_ 40 BDCToUWBEncryptData3 "Encryption Data From BDC to UWB ALL";
CM_ BO_ 41 "[EC] On Event and On Change";
CM_ SG_ 41 BDCToUWBEncryptData4 "Encryption Data From BDC to UWB ALL";
CM_ BO_ 47 "[EC] On Event and On Change";
CM_ SG_ 47 BDCToUWBEncryptData5 "Encryption Data From BDC to UWB ALL";
CM_ BO_ 48 "[EC] On Event and On Change";
CM_ SG_ 48 C_DHRNFCDetected "RH Door NFC Sensor Input";
CM_ SG_ 48 C_DHRWlightStatus "RH Door Welcome Light Status";
CM_ SG_ 48 C_DHR_NFCReset "NFC Deselect Result";
CM_ BO_ 49 "[EC] On Event and On Change";
CM_ SG_ 49 BDCToUWBEncryptData6 "Encryption Data From BDC to UWB ALL";
CM_ BO_ 64 "[EW] On Event and On Write";
CM_ SG_ 64 BDCROADataByte0 "Parameter Data";
CM_ SG_ 64 BDCROADataByte1 "Parameter Data";
CM_ SG_ 64 BDCROADataByte2 "Parameter Data";
CM_ SG_ 64 BDCROADataByte3 "Parameter Data";
CM_ SG_ 64 BDCROADataByte4 "Parameter Data";
CM_ SG_ 64 BDCROADataByte5 "Parameter Data";
CM_ SG_ 64 BDCROADataByte6 "Parameter Data";
CM_ SG_ 64 BDCROADataByte7 "Parameter Data";
CM_ BO_ 96 "[EC] On Event and On Change";
CM_ SG_ 96 C_BLENewDevicePairingResult "BLE New Device Pairing Result";
CM_ SG_ 96 C_BLE_Decrypt_FB "BLE Decryption Feed back";
CM_ BO_ 111 "[EC] On Event and On Change";
CM_ SG_ 111 BLEToBDCEncryptData1 "Encryption Data From BLE to BDC";
CM_ BO_ 112 "[EC] On Event and On Change";
CM_ SG_ 112 C_Time_Sync1 "Timer Sync Data";
CM_ BO_ 113 "[EC] On Event and On Change";
CM_ SG_ 113 BLEToBDCEncryptData2 "Encryption Data From BLE to BDC";
CM_ BO_ 114 "[EC] On Event and On Change";
CM_ SG_ 114 BLEToBDCEncryptData3 "Encryption Data From BLE to BDC";
CM_ BO_ 115 "[EC] On Event and On Change";
CM_ SG_ 115 BLEToBDCEncryptData4 "Encryption Data From BLE to BDC";
CM_ BO_ 116 "[EC] On Event and On Change";
CM_ SG_ 116 BLEToBDCEncryptData5 "Encryption Data From BLE to BDC";
CM_ BO_ 117 "[EC] On Event and On Change";
CM_ SG_ 117 BLEToBDCEncryptData6 "Encryption Data From BLE to BDC";
CM_ BO_ 128 "[EC] On Event and On Change";
CM_ SG_ 128 C_Time_Sync2 "Timer Sync Data";
CM_ BO_ 206 "[EW] On Event and On Write";
CM_ SG_ 206 ROABDC_DataByte0 "Response of Parameter Update";
CM_ SG_ 206 ROABDC_DataByte1 "Response of Parameter Update";
CM_ SG_ 206 ROABDC_DataByte2 "Response of Parameter Update";
CM_ SG_ 206 ROABDC_DataByte3 "Response of Parameter Update";
CM_ SG_ 206 ROABDC_DataByte4 "Response of Parameter Update";
CM_ SG_ 206 ROABDC_DataByte5 "Response of Parameter Update";
CM_ SG_ 206 ROABDC_DataByte6 "Response of Parameter Update";
CM_ SG_ 206 ROABDC_DataByte7 "Response of Parameter Update";
CM_ BO_ 209 "[EC] On Event and On Change";
CM_ SG_ 209 C_UWB_MASTER_Decrypt_FB "UWB Master Decryption Feed Back";
CM_ BO_ 210 "[EC] On Event and On Change";
CM_ SG_ 210 C_UWB_MASTER_To_BDCFOBRSDResul "Distance result of UWB ranging";
CM_ BO_ 211 "[EC] On Event and On Change";
CM_ SG_ 211 C_UWB_MCU_OTA_Cmd "BDC Command for UWB_MCU OTA";
CM_ BO_ 212 "[EC] On Event and On Change";
CM_ SG_ 212 C_UWB_IC_OTA_Cmd "BDC Command for UWB ID OTA";
CM_ BO_ 213 "[EC] On Event and On Change";
CM_ SG_ 213 C_UWB_MCU_Download_Data "UWB MCU Download Data";
CM_ BO_ 214 "[EC] On Event and On Change";
CM_ SG_ 214 C_UWB_IC_Download_Data "UWB IC Download Data";
CM_ BO_ 224 "[EC] On Event and On Change";
CM_ SG_ 224 C_UWB_INT_Decrypt_FB "UWB INT Decryption Feed Back";
CM_ BO_ 225 "[EC] On Event and On Change";
CM_ SG_ 225 C_UWB_INT_To_BDCFOBRSDResult "Distance result of UWB ranging";
CM_ BO_ 226 "[EC] On Event and On Change";
CM_ SG_ 226 C_UWB_INT_MCU_Bootloader "UWB MCU_Bootloader";
CM_ SG_ 226 C_UWB_INT_MCU_Flash_Erase "UWB_MCU_Flash_Erase";
CM_ SG_ 226 C_UWB_INT_MCU_CRC32 "UWB_MCU_CRC32";
CM_ BO_ 227 "[EC] On Event and On Change";
CM_ SG_ 227 C_UWB_INT_IC_Bootloader "UWB_IC_Bootloader";
CM_ SG_ 227 C_UWB_INT_IC_Flash_Erase "UWB_IC_Flash_Erase";
CM_ SG_ 227 C_UWB_INT_IC_CRC32 "UWB_IC_CRC32";
CM_ BO_ 235 "[EW] On Event and On Write";
CM_ SG_ 235 C_UWB_INT_To_MasterEncData2 "Encryption Data From UWB_INT";
CM_ BO_ 256 "[PE] Periodic and On Event";
CM_ SG_ 256 C_BDC_Status "BDC Processing Status";
CM_ SG_ 256 C_DigitalKey_Enable "Digital Key function Enable/Disable by user";
CM_ SG_ 256 C_DeviceOnWPC "Inform device on WPC";
CM_ SG_ 256 C_FobFoundWlcmArea "This signal indicates that there is Fob around the welcome area.
- to inform the door handle (Lock/Unlock touch sensor)";
CM_ SG_ 256 C_PuddleLpOnReq "Puddlelap On request";
CM_ SG_ 256 C_OwnerKey_Reg_Status "Owner Digital Key Register Status";
CM_ SG_ 256 C_SharedKey_Reg_Status "Shared Digital Key Register Status";
CM_ SG_ 256 C_CardKey_Enable "Card Key function Enable/Disable by user";
CM_ BO_ 257 "[PE] Periodic and On Event";
CM_ SG_ 257 Radar_ROA_SnsrRunReq "Sensor detection request";
CM_ SG_ 257 Radar_ROA_DiaReq "Diagnosis/parameter request";
CM_ SG_ 257 Radar_ROA_EngSta "Engine Status";
CM_ BO_ 272 "[PE] Periodic and On Event";
CM_ SG_ 272 C_WPC_Status "WPC Processing Status";
CM_ SG_ 272 C_WPCNFC_Option "WPC NFC Option Applied Signal";
CM_ BO_ 277 "[PE] Periodic and On Event";
CM_ SG_ 277 C_BTAddIRK_Update "BTAddress IRK Update Signal";
CM_ SG_ 277 C_OP_ADV_State "BLE Owner Pairing Advertising State";
CM_ SG_ 277 C_Passive_ADV_State "BLE Passive EN/ST Advertising State";
CM_ SG_ 277 C_NewDeviceConnetStatus "Not Paired Decice Connection Status";
CM_ SG_ 277 C_BLE_Option "BLE Option Applied Signal";
CM_ SG_ 277 C_ConnectedDeviceInfo "BLE Connected Deivces/ID";
CM_ BO_ 288 "[PE] Periodic and On Event";
CM_ SG_ 288 C_DHL_Status "LH Door Processing Status";
CM_ SG_ 288 C_DHLToggleDetected "LH Door Toggle Sensor Input";
CM_ SG_ 288 C_DHLUnlockDetected "LH Door Unlock Sensor Input";
CM_ SG_ 288 C_DHLLockDetected "LH Door Lock Sensor Input";
CM_ SG_ 288 C_DHLPhnDetected "DHL Phone Detected Signal";
CM_ SG_ 288 C_DHLDiagnostics "LH Door NFC_Touch_Diag";
CM_ SG_ 288 C_DHL_RainState "LH Rain Detect Status";
CM_ BO_ 304 "[PE] Periodic and On Event";
CM_ SG_ 304 C_DHR_Status "RH Door Processing Status";
CM_ SG_ 304 C_DHRToggleDetected "RH Door Toggle Sensor Input";
CM_ SG_ 304 C_DHRUnlockDetected "RH Door Unlock Sensor Input";
CM_ SG_ 304 C_DHRLockDetected "RH Door Lock Sensor Input";
CM_ SG_ 304 C_DHRPhnDetected "DHR Phone Detected Signal";
CM_ SG_ 304 C_DHRDiagnostics "RH Door NFC_Touch_Diag";
CM_ SG_ 304 C_DHR_RainState "RH Rain Detect Status";
CM_ BO_ 320 "[PE] Periodic and On Event";
CM_ SG_ 320 C_BLE_RSSI1 "BLE Connection 1 RSSI";
CM_ SG_ 320 C_BLE_RSSI2 "BLE Connection 2 RSSI";
CM_ SG_ 320 C_BLE_RSSI3 "BLE Connection 3 RSSI";
CM_ SG_ 320 C_BLE_RSSI4 "BLE Connection 4 RSSI";
CM_ BO_ 353 "[EC] On Event and On Change";
CM_ SG_ 353 C_UWB_FRNK_Decrypt_FB "UWB FRNK Decryption Feed Back";
CM_ BO_ 354 "[EW] On Event and On Write";
CM_ SG_ 354 C_UWB_FRNK_To_MasterEncData1 "Encryption Data From UWB_FRNK";
CM_ BO_ 355 "[EW] On Event and On Write";
CM_ SG_ 355 C_UWB_FRNK_To_MasterEncData2 "Encryption Data From UWB_FRNK";
CM_ BO_ 356 "[EC] On Event and On Change";
CM_ SG_ 356 C_UWB_FRNK_To_BDCFOBRSDResult "Distance result of UWB ranging";
CM_ BO_ 357 "[PE] Periodic and On Event";
CM_ SG_ 357 Radar_ROA_SW_Ver_Major "Radar ROA SW Version Major";
CM_ SG_ 357 Radar_ROA_SW_Ver_Minor1 "Radar ROA SW Version Minor1";
CM_ SG_ 357 Radar_ROA_SW_Ver_Minor2 "Radar ROA SW Version Minor2";
CM_ SG_ 357 Radar_ROA_ClassStat "ROA Sensor Status for diagnosis";
CM_ SG_ 357 Radar_ROA_SnSrStat "ROA Sensor Status";
CM_ SG_ 357 Radar_ROA_DetInfo "ROA Detection info";
CM_ SG_ 357 Radar_ROA_SnSrBlckgeErrStat "ROA Sensor Blockage Error";
CM_ SG_ 357 Radar_ROA_SnSrErrStat "ROA Internal Error";
CM_ SG_ 357 Radar_ROA_RegionOpt "ROA Euro NCAP Option signal";
CM_ BO_ 358 "[EC] On Event and On Change";
CM_ SG_ 358 C_UWB_FRNK_IC_Bootloader "UWB_IC_Bootloader";
CM_ SG_ 358 C_UWB_FRNK_IC_Flash_Erase "UWB_IC_Flash_Erase";
CM_ SG_ 358 C_UWB_FRNK_IC_CRC32 "UWB_IC_CRC32";
CM_ BO_ 362 "[PE] Periodic and On Event";
CM_ SG_ 362 C_UWB_FRUNK_Status1 "UWB_FRUNK Processing Status 1";
CM_ SG_ 362 C_UWB_FRUNK_Status2 "UWB_FRUNK Processing Status 2";
CM_ SG_ 362 C_UWB_FRUNK_Status3 "UWB_FRUNK Processing Status 3";
CM_ SG_ 362 C_UWB_FRUNK_Status4 "UWB_FRUNK Processing Status 4";
CM_ SG_ 362 C_UWB_FRUNK_Status5 "UWB_FRUNK Processing Status 5";
CM_ SG_ 362 C_UWB_FRUNK_Status6 "UWB_FRUNK Processing Status 6";
CM_ SG_ 362 C_UWB_FRUNK_Status7 "UWB_FRUNK Processing Status 7";
CM_ SG_ 362 C_UWB_FRUNK_Status8 "UWB_FRUNK Processing Status 8";
CM_ SG_ 362 C_UWB_FRNK_DTC "UWB Frunk DTC Data";
CM_ SG_ 362 C_UWB_FRUNK_Option "UWB FRUNK Applied Signal";
CM_ BO_ 363 "[P] Periodic";
CM_ SG_ 363 C_UWB_FRNK_HW_Ver_Major "UWB FRNK HW Version Major";
CM_ SG_ 363 C_UWB_FRNK_HW_Ver_Minor "UWB FRNK HW Version Minor";
CM_ SG_ 363 C_UWB_FRNK_SW_MCU_Ver_Major "UWB FRNK SW MCU Version Major";
CM_ SG_ 363 C_UWB_FRNK_SW_MCU_Ver_Minor "UWB FRNK SW MCU Version Minor";
CM_ SG_ 363 C_UWB_FRNK_SW_IC_Ver_Major "UWB FRNK SW IC Version Major";
CM_ SG_ 363 C_UWB_FRNK_SW_IC_Ver_Minor "UWB FRNK SW IC Version Minor";
CM_ BO_ 367 "[EC] On Event and On Change";
CM_ SG_ 367 C_UWB_FRNK_MCU_Bootloader "UWB MCU_Bootloader";
CM_ SG_ 367 C_UWB_FRNK_MCU_Flash_Erase "UWB_MCU_Flash_Erase";
CM_ SG_ 367 C_UWB_FRNK_MCU_CRC32 "UWB_MCU_CRC32";
CM_ BO_ 368 "[PE] Periodic and On Event";
CM_ SG_ 368 C_UWB_FR_Status1 "UWB_FR Processing Status 1";
CM_ SG_ 368 C_UWB_FR_Status2 "UWB_FR Processing Status 2";
CM_ SG_ 368 C_UWB_FR_Status3 "UWB_FR Processing Status 3";
CM_ SG_ 368 C_UWB_FR_Status4 "UWB_FR Processing Status 4";
CM_ SG_ 368 C_UWB_FR_Status5 "UWB_FR Processing Status 5";
CM_ SG_ 368 C_UWB_FR_Status6 "UWB_FR Processing Status 6";
CM_ SG_ 368 C_UWB_FR_Status7 "UWB_FR Processing Status 7";
CM_ SG_ 368 C_UWB_FR_Status8 "UWB_FR Processing Status 8";
CM_ SG_ 368 C_UWB_FR_DTC "UWB FR DTC Data";
CM_ SG_ 368 C_UWB_FR_Option "UWB FR Applied Signal";
CM_ BO_ 369 "[P] Periodic";
CM_ SG_ 369 C_UWB_FR_HW_Ver_Major "UWB FR HW Version Major";
CM_ SG_ 369 C_UWB_FR_HW_Ver_Minor "UWB FR HW Version Minor";
CM_ SG_ 369 C_UWB_FR_SW_MCU_Ver_Major "UWB FR SW MCU Version Major";
CM_ SG_ 369 C_UWB_FR_SW_MCU_Ver_Minor "UWB FR SW MCU Version Minor";
CM_ SG_ 369 C_UWB_FR_SW_IC_Ver_Major "UWB FR SW IC Version Major";
CM_ SG_ 369 C_UWB_FR_SW_IC_Ver_Minor "UWB FR SW IC Version Minor";
CM_ BO_ 370 "[EW] On Event and On Write";
CM_ SG_ 370 C_UWB_FL_To_MaseterEncData1 "Encryption Data From UWB_FL";
CM_ BO_ 371 "[EW] On Event and On Write";
CM_ SG_ 371 C_UWB_FL_To_MasterEncData2 "Encryption Data From UWB_FL";
CM_ BO_ 372 "[EC] On Event and On Change";
CM_ SG_ 372 C_UWB_FL_To_BDCFOBRSDResult "Distance result of UWB ranging";
CM_ BO_ 373 "[EC] On Event and On Change";
CM_ SG_ 373 C_UWB_FL_MCU_Bootloader "UWB FL_MCU_Bootloader";
CM_ SG_ 373 C_UWB_FL_MCU_Flash_Erase "UWB_FL_MCU_Flash_Erase";
CM_ SG_ 373 C_UWB_FL_MCU_CRC32 "UWB_FL_MCU_CRC32";
CM_ BO_ 374 "[EC] On Event and On Change";
CM_ SG_ 374 C_UWB_FL_IC_Bootloader "UWB_FL_MCU_Bootloader";
CM_ SG_ 374 C_UWB_FL_IC_Flash_Erase "UWB_FL_MCU_Flash_Erase";
CM_ SG_ 374 C_UWB_FL_IC_CRC32 "UWB_FL_MCU_CRC32";
CM_ BO_ 375 "[EC] On Event and On Change";
CM_ SG_ 375 C_UWB_FL_Decrypt_FB "UWB FL Decryption Feed Back";
CM_ BO_ 376 "[PE] Periodic and On Event";
CM_ SG_ 376 C_UWB_FL_Status1 "UWB_FL Processing Status 1";
CM_ SG_ 376 C_UWB_FL_Status2 "UWB_FL Processing Status 2";
CM_ SG_ 376 C_UWB_FL_Status3 "UWB_FL Processing Status 3";
CM_ SG_ 376 C_UWB_FL_Status4 "UWB_FL Processing Status 4";
CM_ SG_ 376 C_UWB_FL_Status5 "UWB_FL Processing Status 5";
CM_ SG_ 376 C_UWB_FL_Status6 "UWB_FL Processing Status 6";
CM_ SG_ 376 C_UWB_FL_Status7 "UWB_FL Processing Status 7";
CM_ SG_ 376 C_UWB_FL_Status8 "UWB_FL Processing Status 8";
CM_ SG_ 376 C_UWB_FL_DTC "UWB FL DTC Data";
CM_ SG_ 376 C_UWB_FL_Option "UWB FL Applied Signal";
CM_ BO_ 377 "[P] Periodic";
CM_ SG_ 377 C_UWB_FL_HW_Ver_Major "UWB FL HW Version Major";
CM_ SG_ 377 C_UWB_FL_HW_Ver_Minor "UWB FL HW Version Minor";
CM_ SG_ 377 C_UWB_FL_SW_MCU_Ver_Major "UWB FL SW MCU Version Major";
CM_ SG_ 377 C_UWB_FL_SW_MCU_Ver_Minor "UWB FL SW MCU Version Minor";
CM_ SG_ 377 C_UWB_FL_SW_IC_Ver_Major "UWB FL SW IC Version Major";
CM_ SG_ 377 C_UWB_FL_SW_IC_Ver_Minor "UWB FL SW IC Version Minor";
CM_ BO_ 378 "[EW] On Event and On Write";
CM_ SG_ 378 C_UWB_BLE_MasterEncData1 "Encryption Data From UWB_BLE Master";
CM_ BO_ 379 "[EW] On Event and On Write";
CM_ SG_ 379 C_UWB_BLE_MasterEncData2 "Encryption Data From UWB_BLE Master";
CM_ BO_ 384 "[PE] Periodic and On Event";
CM_ SG_ 384 C_UWB_INT_Status1 "UWB_INT Processing Status 1";
CM_ SG_ 384 C_UWB_INT_Status2 "UWB_INT Processing Status 2";
CM_ SG_ 384 C_UWB_INT_Status3 "UWB_INT Processing Status 3";
CM_ SG_ 384 C_UWB_INT_Status4 "UWB_INT Processing Status 4";
CM_ SG_ 384 C_UWB_INT_Status5 "UWB_INT Processing Status 5";
CM_ SG_ 384 C_UWB_INT_Status6 "UWB_INT Processing Status 6";
CM_ SG_ 384 C_UWB_INT_Status7 "UWB_INT Processing Status 7";
CM_ SG_ 384 C_UWB_INT_Status8 "UWB_INT Processing Status 8";
CM_ SG_ 384 C_UWB_INT_DTC "UWB INT DTC Data";
CM_ SG_ 384 C_UWB_INT_Option "UWB INT Applied Signal";
CM_ BO_ 385 "[P] Periodic";
CM_ SG_ 385 C_UWB_INT_HW_Ver_Major "UWB INT HW Version Major";
CM_ SG_ 385 C_UWB_INT_HW_Ver_Minor "UWB INT HW Version Minor";
CM_ SG_ 385 C_UWB_INT_SW_MCU_Ver_Major "UWB INT SW MCU Version Major";
CM_ SG_ 385 C_UWB_INT_SW_MCU_Ver_Minor "UWB INT SW MCU Version Minor";
CM_ SG_ 385 C_UWB_INT_SW_IC_Ver_Major "UWB INT SW IC Version Major";
CM_ SG_ 385 C_UWB_INT_SW_IC_Ver_Minor "UWB INT SW IC Version Minor";
CM_ BO_ 386 "[EW] On Event and On Write";
CM_ SG_ 386 C_UWB_FR_To_MasterEncData1 "Encryption Data From UWB_FR";
CM_ BO_ 387 "[EC] On Event and On Change";
CM_ SG_ 387 C_UWB_FR_Decrypt_FB "UWB FR Decryption Feed Back";
CM_ BO_ 388 "[EC] On Event and On Change";
CM_ SG_ 388 C_UWB_FR_To_BDCFOBRSDResult "Distance result of UWB ranging";
CM_ BO_ 389 "[EC] On Event and On Change";
CM_ SG_ 389 C_UWB_FR_MCU_Bootloader "UWB MCU_Bootloader";
CM_ SG_ 389 C_UWB_FR_MCU_Flash_Erase "UWB_MCU_Flash_Erase";
CM_ SG_ 389 C_UWB_FR_MCU_CRC32 "UWB_MCU_CRC32";
CM_ BO_ 390 "[EC] On Event and On Change";
CM_ SG_ 390 C_UWB_FR_IC_Bootloader "UWB_IC_Bootloader";
CM_ SG_ 390 C_UWB_FR_IC_Flash_Erase "UWB_IC_Flash_Erase";
CM_ SG_ 390 C_UWB_FR_IC_CRC32 "UWB_IC_CRC32";
CM_ BO_ 391 "[EW] On Event and On Write";
CM_ SG_ 391 C_UWB_FR_To_MasterEncData2 "Encryption Data From UWB_FR";
BA_DEF_ SG_  "NWM-WakeupAllowed" ENUM  "<n.a.>";
BA_DEF_ BO_  "NWM-Botschaft" ENUM  "No","Yes";
BA_DEF_ BU_  "NWM-Knoten" ENUM  "No","Yes";
BA_DEF_ SG_  "GenSigEnvVarType" ENUM  "int","float","undef";
BA_DEF_ SG_  "GwSigLatencyTime" INT 0 65535;
BA_DEF_ SG_  "GwSigMissingSourceType" ENUM  "Undef","OldValue","DefaultValue","InitialValue";
BA_DEF_ SG_  "SignalCategory" HEX 10 15;
BA_DEF_ SG_  "GenSigSendType" ENUM  "Cyclic","OnWrite","OnWriteWithRepetition","OnChange","OnChangeWithRepetition","IfActive","IfActiveWithRepetition","NoSigSendType";
BA_DEF_ BO_  "GenMsgDelayTime" INT 20 20;
BA_DEF_ BO_  "NmMessage" ENUM  "No","Yes";
BA_DEF_ BO_  "GenMsgILSupport" ENUM  "No","Yes";
BA_DEF_ BO_  "GenMsgNrOfRepetition" INT 0 3;
BA_DEF_ BO_  "GenMsgCycleTimeFast" INT 0 500;
BA_DEF_ BO_  "GenMsgStartDelayTime" INT 0 100;
BA_DEF_ BO_  "GenMsgSendType" ENUM  "Cyclic","not_used","not_used","not_used","not_used","not_used","not_used","not_used","NoMsgSendType";
BA_DEF_ BO_  "GenMsgCycleTime" INT 0 2000;
BA_DEF_ BU_  "GenNodSleepTime" INT 1375 1650;
BA_DEF_ BU_  "NodeLayerModules" STRING ;
BA_DEF_ BU_  "NmNode" ENUM  "No","Yes";
BA_DEF_ BU_  "NmCAN" INT 1 2;
BA_DEF_ BU_  "ILUsed" ENUM  "No","Yes";
BA_DEF_ BU_  "NmStationAddress" HEX 0 255;
BA_DEF_  "GenNWMApBusSleep" STRING ;
BA_DEF_  "GenNWMApCanNormal" STRING ;
BA_DEF_  "GenNWMApCanOff" STRING ;
BA_DEF_  "GenNWMApCanOn" STRING ;
BA_DEF_  "GenNWMApCanSleep" STRING ;
BA_DEF_  "GenNWMApCanWakeUp" STRING ;
BA_DEF_  "GenNWMGotoMode_Awake" STRING ;
BA_DEF_  "GenNWMGotoMode_BusSleep" STRING ;
BA_DEF_  "GenNWMSleepTime" INT 1375 1650;
BA_DEF_  "GenNWMTalkNM" STRING ;
BA_DEF_  "GenEnvVarEndingDsp" STRING ;
BA_DEF_  "GenEnvVarEndingSnd" STRING ;
BA_DEF_  "GenEnvVarPrefix" STRING ;
BA_DEF_  "VersionNumberInternal" INT 0 9999;
BA_DEF_  "VersionNumber" INT 0 999999;
BA_DEF_  "VersionWeek" INT 1 53;
BA_DEF_  "VersionYear" INT 0 9999;
BA_DEF_  "VersionMonth" INT 1 12;
BA_DEF_  "VersionDay" INT 1 31;
BA_DEF_  "BusType" STRING ;
BA_DEF_  "DBName" STRING ;
BA_DEF_  "NmType" STRING ;
BA_DEF_  "NmBaseAddress" HEX 0 2047;
BA_DEF_  "NmMessageCount" INT 0 128;
BA_DEF_  "Manufacturer" STRING ;
BA_DEF_  "Baudrate" INT 100000 500000;
BA_DEF_  "SamplePointMin" INT 55 85;
BA_DEF_  "SamplePointMax" INT 50 85;
BA_DEF_  "SyncJumpWidthMin" INT 1 4;
BA_DEF_  "SyncJumpWidthMax" INT 1 8;
BA_DEF_REL_ BU_SG_REL_  "GenSigTimeoutTime" INT 175 3500;
BA_DEF_DEF_  "NWM-WakeupAllowed" "<n.a.>";
BA_DEF_DEF_  "NWM-Botschaft" "No";
BA_DEF_DEF_  "NWM-Knoten" "Yes";
BA_DEF_DEF_  "GenSigEnvVarType" "undef";
BA_DEF_DEF_  "GwSigLatencyTime" 40;
BA_DEF_DEF_  "GwSigMissingSourceType" "Undef";
BA_DEF_DEF_  "SignalCategory" 12;
BA_DEF_DEF_  "GenSigSendType" "NoSigSendType";
BA_DEF_DEF_  "GenMsgDelayTime" 20;
BA_DEF_DEF_  "NmMessage" "No";
BA_DEF_DEF_  "GenMsgILSupport" "Yes";
BA_DEF_DEF_  "GenMsgNrOfRepetition" 3;
BA_DEF_DEF_  "GenMsgCycleTimeFast" 60;
BA_DEF_DEF_  "GenMsgStartDelayTime" 0;
BA_DEF_DEF_  "GenMsgSendType" "NoMsgSendType";
BA_DEF_DEF_  "GenMsgCycleTime" 200;
BA_DEF_DEF_  "GenNodSleepTime" 1500;
BA_DEF_DEF_  "NodeLayerModules" "oseknm01.dll";
BA_DEF_DEF_  "NmNode" "Yes";
BA_DEF_DEF_  "NmCAN" 1;
BA_DEF_DEF_  "ILUsed" "Yes";
BA_DEF_DEF_  "NmStationAddress" 0;
BA_DEF_DEF_  "GenNWMApBusSleep" "ApplNmCanBusSleep()";
BA_DEF_DEF_  "GenNWMApCanNormal" "ApplNmCanNormal()";
BA_DEF_DEF_  "GenNWMApCanOff" "ApplCanOffline()";
BA_DEF_DEF_  "GenNWMApCanOn" "ApplCanOnline()";
BA_DEF_DEF_  "GenNWMApCanSleep" "ApplNmCanSleep()";
BA_DEF_DEF_  "GenNWMApCanWakeUp" "ApplCanWakeUp()";
BA_DEF_DEF_  "GenNWMGotoMode_Awake" "GotoMode_Awake()";
BA_DEF_DEF_  "GenNWMGotoMode_BusSleep" "GotoMode_BusSleep()";
BA_DEF_DEF_  "GenNWMSleepTime" 1500;
BA_DEF_DEF_  "GenNWMTalkNM" "TalkNM()";
BA_DEF_DEF_  "GenEnvVarEndingDsp" "Dsp_";
BA_DEF_DEF_  "GenEnvVarEndingSnd" "_";
BA_DEF_DEF_  "GenEnvVarPrefix" "Env";
BA_DEF_DEF_  "VersionNumberInternal" 0;
BA_DEF_DEF_  "VersionNumber" 0;
BA_DEF_DEF_  "VersionWeek" 1;
BA_DEF_DEF_  "VersionYear" 0;
BA_DEF_DEF_  "VersionMonth" 1;
BA_DEF_DEF_  "VersionDay" 1;
BA_DEF_DEF_  "BusType" "CAN";
BA_DEF_DEF_  "DBName" "";
BA_DEF_DEF_  "NmType" "Vector";
BA_DEF_DEF_  "NmBaseAddress" 1024;
BA_DEF_DEF_  "NmMessageCount" 128;
BA_DEF_DEF_  "Manufacturer" "HMC";
BA_DEF_DEF_  "Baudrate" 500000;
BA_DEF_DEF_  "SamplePointMin" 75;
BA_DEF_DEF_  "SamplePointMax" 82;
BA_DEF_DEF_  "SyncJumpWidthMin" 2;
BA_DEF_DEF_  "SyncJumpWidthMax" 3;
BA_DEF_DEF_REL_ "GenSigTimeoutTime" 700;
BA_ "VersionNumber" 108;
BA_ "VersionYear" 1;
BA_ "DBName" "CAN";
BA_ "NmStationAddress" BU_ UWB_RL 105;
BA_ "NmStationAddress" BU_ UWB_FRNK 110;
BA_ "NmStationAddress" BU_ UWB_RR 104;
BA_ "NmStationAddress" BU_ UWB_INT 117;
BA_ "NmStationAddress" BU_ DHR 97;
BA_ "NmStationAddress" BU_ DHL 96;
BA_ "NmStationAddress" BU_ UWB_BLE 116;
BA_ "NmStationAddress" BU_ UWB_FL 103;
BA_ "NmStationAddress" BU_ Devtool 99;
BA_ "NmStationAddress" BU_ ROA 73;
BA_ "NmStationAddress" BU_ WPC 30;
BA_ "NmStationAddress" BU_ UWB_TRNK 109;
BA_ "NmStationAddress" BU_ UWB_FR 102;
BA_ "GenMsgCycleTimeFast" BO_ 16 40;
BA_ "GenMsgCycleTime" BO_ 16 0;
BA_ "GenMsgCycleTimeFast" BO_ 17 40;
BA_ "GenMsgCycleTime" BO_ 17 0;
BA_ "GenMsgCycleTimeFast" BO_ 18 40;
BA_ "GenMsgCycleTime" BO_ 18 0;
BA_ "GenMsgCycleTimeFast" BO_ 19 40;
BA_ "GenMsgCycleTime" BO_ 19 0;
BA_ "GenMsgCycleTimeFast" BO_ 20 40;
BA_ "GenMsgCycleTime" BO_ 20 0;
BA_ "GenMsgCycleTimeFast" BO_ 21 40;
BA_ "GenMsgSendType" BO_ 21 0;
BA_ "GenMsgStartDelayTime" BO_ 22 20;
BA_ "GenMsgCycleTimeFast" BO_ 22 40;
BA_ "GenMsgSendType" BO_ 22 0;
BA_ "GenMsgCycleTimeFast" BO_ 31 40;
BA_ "GenMsgCycleTime" BO_ 31 0;
BA_ "GenMsgCycleTimeFast" BO_ 32 40;
BA_ "GenMsgCycleTime" BO_ 32 0;
BA_ "GenMsgCycleTimeFast" BO_ 33 40;
BA_ "GenMsgCycleTime" BO_ 33 0;
BA_ "GenMsgCycleTimeFast" BO_ 34 40;
BA_ "GenMsgCycleTime" BO_ 34 0;
BA_ "GenMsgCycleTimeFast" BO_ 35 40;
BA_ "GenMsgCycleTime" BO_ 35 0;
BA_ "GenMsgCycleTimeFast" BO_ 36 40;
BA_ "GenMsgCycleTime" BO_ 36 0;
BA_ "GenMsgCycleTimeFast" BO_ 37 40;
BA_ "GenMsgCycleTime" BO_ 37 0;
BA_ "GenMsgCycleTimeFast" BO_ 38 40;
BA_ "GenMsgCycleTime" BO_ 38 0;
BA_ "GenMsgCycleTimeFast" BO_ 39 40;
BA_ "GenMsgCycleTime" BO_ 39 0;
BA_ "GenMsgCycleTimeFast" BO_ 40 40;
BA_ "GenMsgCycleTime" BO_ 40 0;
BA_ "GenMsgCycleTimeFast" BO_ 41 40;
BA_ "GenMsgCycleTime" BO_ 41 0;
BA_ "GenMsgCycleTimeFast" BO_ 47 40;
BA_ "GenMsgCycleTime" BO_ 47 0;
BA_ "GenMsgCycleTimeFast" BO_ 48 40;
BA_ "GenMsgCycleTime" BO_ 48 0;
BA_ "GenMsgCycleTimeFast" BO_ 49 40;
BA_ "GenMsgCycleTime" BO_ 49 0;
BA_ "GenMsgCycleTimeFast" BO_ 64 40;
BA_ "GenMsgCycleTime" BO_ 64 0;
BA_ "GenMsgCycleTimeFast" BO_ 96 40;
BA_ "GenMsgCycleTime" BO_ 96 0;
BA_ "GenMsgCycleTimeFast" BO_ 111 40;
BA_ "GenMsgCycleTime" BO_ 111 0;
BA_ "GenMsgCycleTimeFast" BO_ 112 40;
BA_ "GenMsgCycleTime" BO_ 112 0;
BA_ "GenMsgCycleTimeFast" BO_ 113 40;
BA_ "GenMsgCycleTime" BO_ 113 0;
BA_ "GenMsgCycleTimeFast" BO_ 114 40;
BA_ "GenMsgCycleTime" BO_ 114 0;
BA_ "GenMsgCycleTimeFast" BO_ 115 40;
BA_ "GenMsgCycleTime" BO_ 115 0;
BA_ "GenMsgCycleTimeFast" BO_ 116 40;
BA_ "GenMsgCycleTime" BO_ 116 0;
BA_ "GenMsgCycleTimeFast" BO_ 117 40;
BA_ "GenMsgCycleTime" BO_ 117 0;
BA_ "GenMsgCycleTimeFast" BO_ 128 40;
BA_ "GenMsgCycleTime" BO_ 128 0;
BA_ "GenMsgCycleTimeFast" BO_ 206 40;
BA_ "GenMsgCycleTime" BO_ 206 0;
BA_ "GenMsgCycleTimeFast" BO_ 209 40;
BA_ "GenMsgCycleTime" BO_ 209 0;
BA_ "GenMsgCycleTimeFast" BO_ 210 40;
BA_ "GenMsgCycleTime" BO_ 210 0;
BA_ "GenMsgCycleTimeFast" BO_ 211 40;
BA_ "GenMsgCycleTime" BO_ 211 0;
BA_ "GenMsgCycleTimeFast" BO_ 212 40;
BA_ "GenMsgCycleTime" BO_ 212 0;
BA_ "GenMsgCycleTimeFast" BO_ 213 40;
BA_ "GenMsgCycleTime" BO_ 213 0;
BA_ "GenMsgCycleTimeFast" BO_ 214 40;
BA_ "GenMsgCycleTime" BO_ 214 0;
BA_ "GenMsgCycleTimeFast" BO_ 224 40;
BA_ "GenMsgCycleTime" BO_ 224 0;
BA_ "GenMsgCycleTimeFast" BO_ 225 40;
BA_ "GenMsgCycleTime" BO_ 225 0;
BA_ "GenMsgCycleTimeFast" BO_ 226 40;
BA_ "GenMsgCycleTime" BO_ 226 0;
BA_ "GenMsgCycleTimeFast" BO_ 227 40;
BA_ "GenMsgCycleTime" BO_ 227 0;
BA_ "GenMsgCycleTimeFast" BO_ 235 40;
BA_ "GenMsgCycleTime" BO_ 235 0;
BA_ "GenMsgStartDelayTime" BO_ 256 40;
BA_ "GenMsgCycleTimeFast" BO_ 256 40;
BA_ "GenMsgSendType" BO_ 256 0;
BA_ "GenMsgStartDelayTime" BO_ 257 60;
BA_ "GenMsgCycleTimeFast" BO_ 257 40;
BA_ "GenMsgSendType" BO_ 257 0;
BA_ "GenMsgCycleTimeFast" BO_ 272 40;
BA_ "GenMsgSendType" BO_ 272 0;
BA_ "GenMsgCycleTimeFast" BO_ 277 40;
BA_ "GenMsgSendType" BO_ 277 0;
BA_ "GenMsgCycleTimeFast" BO_ 288 40;
BA_ "GenMsgSendType" BO_ 288 0;
BA_ "GenMsgCycleTimeFast" BO_ 304 40;
BA_ "GenMsgSendType" BO_ 304 0;
BA_ "GenMsgStartDelayTime" BO_ 320 20;
BA_ "GenMsgCycleTimeFast" BO_ 320 40;
BA_ "GenMsgSendType" BO_ 320 0;
BA_ "GenMsgCycleTimeFast" BO_ 353 40;
BA_ "GenMsgCycleTime" BO_ 353 0;
BA_ "GenMsgCycleTimeFast" BO_ 354 40;
BA_ "GenMsgCycleTime" BO_ 354 0;
BA_ "GenMsgCycleTimeFast" BO_ 355 40;
BA_ "GenMsgCycleTime" BO_ 355 0;
BA_ "GenMsgCycleTimeFast" BO_ 356 40;
BA_ "GenMsgCycleTime" BO_ 356 0;
BA_ "GenMsgCycleTimeFast" BO_ 357 40;
BA_ "GenMsgSendType" BO_ 357 0;
BA_ "GenMsgCycleTimeFast" BO_ 358 40;
BA_ "GenMsgCycleTime" BO_ 358 0;
BA_ "GenMsgCycleTimeFast" BO_ 362 40;
BA_ "GenMsgSendType" BO_ 362 0;
BA_ "GenMsgStartDelayTime" BO_ 363 20;
BA_ "GenMsgNrOfRepetition" BO_ 363 0;
BA_ "GenMsgCycleTimeFast" BO_ 363 0;
BA_ "GenMsgSendType" BO_ 363 0;
BA_ "GenMsgCycleTimeFast" BO_ 367 40;
BA_ "GenMsgCycleTime" BO_ 367 0;
BA_ "GenMsgCycleTimeFast" BO_ 368 40;
BA_ "GenMsgSendType" BO_ 368 0;
BA_ "GenMsgStartDelayTime" BO_ 369 20;
BA_ "GenMsgNrOfRepetition" BO_ 369 0;
BA_ "GenMsgCycleTimeFast" BO_ 369 0;
BA_ "GenMsgSendType" BO_ 369 0;
BA_ "GenMsgCycleTimeFast" BO_ 370 40;
BA_ "GenMsgCycleTime" BO_ 370 0;
BA_ "GenMsgCycleTimeFast" BO_ 371 40;
BA_ "GenMsgCycleTime" BO_ 371 0;
BA_ "GenMsgCycleTimeFast" BO_ 372 40;
BA_ "GenMsgCycleTime" BO_ 372 0;
BA_ "GenMsgCycleTimeFast" BO_ 373 40;
BA_ "GenMsgCycleTime" BO_ 373 0;
BA_ "GenMsgCycleTimeFast" BO_ 374 40;
BA_ "GenMsgCycleTime" BO_ 374 0;
BA_ "GenMsgCycleTimeFast" BO_ 375 40;
BA_ "GenMsgCycleTime" BO_ 375 0;
BA_ "GenMsgCycleTimeFast" BO_ 376 40;
BA_ "GenMsgSendType" BO_ 376 0;
BA_ "GenMsgStartDelayTime" BO_ 377 20;
BA_ "GenMsgNrOfRepetition" BO_ 377 0;
BA_ "GenMsgCycleTimeFast" BO_ 377 0;
BA_ "GenMsgSendType" BO_ 377 0;
BA_ "GenMsgCycleTimeFast" BO_ 378 40;
BA_ "GenMsgCycleTime" BO_ 378 0;
BA_ "GenMsgCycleTimeFast" BO_ 379 40;
BA_ "GenMsgCycleTime" BO_ 379 0;
BA_ "GenMsgCycleTimeFast" BO_ 384 40;
BA_ "GenMsgSendType" BO_ 384 0;
BA_ "GenMsgStartDelayTime" BO_ 385 20;
BA_ "GenMsgNrOfRepetition" BO_ 385 0;
BA_ "GenMsgCycleTimeFast" BO_ 385 0;
BA_ "GenMsgSendType" BO_ 385 0;
BA_ "GenMsgCycleTimeFast" BO_ 386 40;
BA_ "GenMsgCycleTime" BO_ 386 0;
BA_ "GenMsgCycleTimeFast" BO_ 387 40;
BA_ "GenMsgCycleTime" BO_ 387 0;
BA_ "GenMsgCycleTimeFast" BO_ 388 40;
BA_ "GenMsgCycleTime" BO_ 388 0;
BA_ "GenMsgCycleTimeFast" BO_ 389 40;
BA_ "GenMsgCycleTime" BO_ 389 0;
BA_ "GenMsgCycleTimeFast" BO_ 390 40;
BA_ "GenMsgCycleTime" BO_ 390 0;
BA_ "GenMsgCycleTimeFast" BO_ 391 40;
BA_ "GenMsgCycleTime" BO_ 391 0;
BA_ "GenSigSendType" SG_ 16 C_WPC_NFCDetection 4;
BA_ "GenSigSendType" SG_ 16 C_WPC_NFCReset 4;
BA_ "GenSigSendType" SG_ 17 C_WlightOnCmd 4;
BA_ "GenSigSendType" SG_ 17 C_WPCNFCcmd 4;
BA_ "GenSigSendType" SG_ 17 C_DRNFCcmd 4;
BA_ "GenSigSendType" SG_ 17 C_BDCWPCNFCCmd 4;
BA_ "GenSigSendType" SG_ 17 C_BDCDHLNFCCmd 4;
BA_ "GenSigSendType" SG_ 17 C_BDCDHRNFCCmd 4;
BA_ "GenSigSendType" SG_ 17 C_DRV_DRHdlLedOnSta 4;
BA_ "GenSigSendType" SG_ 17 C_AST_DRHdlLedOnSta 4;
BA_ "GenSigSendType" SG_ 18 C_DK_IDSet 4;
BA_ "GenSigSendType" SG_ 18 C_DK_IDDel 4;
BA_ "GenSigSendType" SG_ 18 C_OwnerDeviceSearchingReq 4;
BA_ "GenSigSendType" SG_ 18 C_TimeSync_REQ 4;
BA_ "GenSigSendType" SG_ 18 C_BLE_Connection_CMD 4;
BA_ "GenSigSendType" SG_ 18 C_BDC_DecryptFB1 4;
BA_ "GenSigSendType" SG_ 18 C_BDC_DecryptFB2 4;
BA_ "GenSigSendType" SG_ 19 C_BDCLocalRN_Target 4;
BA_ "GenSigSendType" SG_ 19 C_BDCLocalRN_TRCode 4;
BA_ "GenSigSendType" SG_ 19 C_BDCLocalRN_CMD 4;
BA_ "GenSigSendType" SG_ 19 C_BDCLocalRndNum 4;
BA_ "GenSigSendType" SG_ 20 C_UWB_Ranging_CMD_ID 4;
BA_ "GenSigSendType" SG_ 20 C_UWB_Ranging_CMD_Value 4;
BA_ "GenSigSendType" SG_ 21 C_Warn_DrvDrSwSta 4;
BA_ "GenSigSendType" SG_ 21 C_Warn_AsstDrSwSta 4;
BA_ "GenSigSendType" SG_ 21 C_Warn_RrLftDrSwSta 4;
BA_ "GenSigSendType" SG_ 21 C_Warn_RrRtDrSwSta 4;
BA_ "GenSigSendType" SG_ 21 C_Trunk_TrnkTlgtSwSta 4;
BA_ "GenSigSendType" SG_ 21 C_SMK_TrmnlMngrSta 4;
BA_ "GenSigSendType" SG_ 21 C_Window_DrvrSdWdwSta_BCM 4;
BA_ "GenSigSendType" SG_ 21 C_Window_AsstSdWdwSta_BCM 4;
BA_ "GenSigSendType" SG_ 21 C_Window_RrLftWdwSta_BCM 4;
BA_ "GenSigSendType" SG_ 21 C_Window_RrRtWdwSta_BCM 4;
BA_ "GenSigSendType" SG_ 21 C_BodyTypeSta 4;
BA_ "GenSigSendType" SG_ 21 C_SunRoofOptionSta 4;
BA_ "GenSigSendType" SG_ 22 C_SSB_StrtStpBtnSw1Sta 4;
BA_ "GenSigSendType" SG_ 22 C_SSB_StrtStpBtnSw2Sta 4;
BA_ "GenSigSendType" SG_ 22 C_DoorLock_AsstDrUnLkSta 4;
BA_ "GenSigSendType" SG_ 22 C_DoorLock_DrvDrUnLkSta 4;
BA_ "GenSigSendType" SG_ 22 C_DoorLock_RrLftDrUnLkSta 4;
BA_ "GenSigSendType" SG_ 22 C_DoorLock_RrRtDrUnLkSta 4;
BA_ "GenSigSendType" SG_ 22 C_DriveTypeOption 4;
BA_ "GenSigSendType" SG_ 22 C_RSPA_Opt 4;
BA_ "GenSigSendType" SG_ 31 BDCToBLEEncryptData1 4;
BA_ "SignalCategory" SG_ 32 C_DHLNFCDetected 10;
BA_ "GenSigSendType" SG_ 32 C_DHLNFCDetected 4;
BA_ "SignalCategory" SG_ 32 C_DHLWlightStatus 10;
BA_ "GenSigSendType" SG_ 32 C_DHLWlightStatus 4;
BA_ "GenSigSendType" SG_ 32 C_DHL_NFCReset 4;
BA_ "GenSigSendType" SG_ 33 BDCToBLEEncryptData2 4;
BA_ "GenSigSendType" SG_ 34 BDCToBLEEncryptData3 4;
BA_ "GenSigSendType" SG_ 35 BDCToBLEEncryptData4 4;
BA_ "GenSigSendType" SG_ 36 BDCToBLEEncryptData5 4;
BA_ "GenSigSendType" SG_ 37 BDCToBLEEncryptData6 4;
BA_ "GenSigSendType" SG_ 38 BDCToUWBEncryptData1 4;
BA_ "GenSigSendType" SG_ 39 BDCToUWBEncryptData2 4;
BA_ "GenSigSendType" SG_ 40 BDCToUWBEncryptData3 4;
BA_ "GenSigSendType" SG_ 41 BDCToUWBEncryptData4 4;
BA_ "GenSigSendType" SG_ 47 BDCToUWBEncryptData5 4;
BA_ "SignalCategory" SG_ 48 C_DHRNFCDetected 10;
BA_ "GenSigSendType" SG_ 48 C_DHRNFCDetected 4;
BA_ "SignalCategory" SG_ 48 C_DHRWlightStatus 10;
BA_ "GenSigSendType" SG_ 48 C_DHRWlightStatus 4;
BA_ "GenSigSendType" SG_ 48 C_DHR_NFCReset 4;
BA_ "GenSigSendType" SG_ 49 BDCToUWBEncryptData6 4;
BA_ "GenSigSendType" SG_ 64 BDCROADataByte7 2;
BA_ "GenSigSendType" SG_ 96 C_BLENewDevicePairingResult 4;
BA_ "GenSigSendType" SG_ 96 C_BLE_Decrypt_FB 4;
BA_ "GenSigSendType" SG_ 111 BLEToBDCEncryptData1 4;
BA_ "SignalCategory" SG_ 112 C_Time_Sync1 10;
BA_ "GenSigSendType" SG_ 112 C_Time_Sync1 4;
BA_ "GenSigSendType" SG_ 113 BLEToBDCEncryptData2 4;
BA_ "GenSigSendType" SG_ 114 BLEToBDCEncryptData3 4;
BA_ "GenSigSendType" SG_ 115 BLEToBDCEncryptData4 4;
BA_ "GenSigSendType" SG_ 116 BLEToBDCEncryptData5 4;
BA_ "GenSigSendType" SG_ 117 BLEToBDCEncryptData6 4;
BA_ "SignalCategory" SG_ 128 C_Time_Sync2 10;
BA_ "GenSigSendType" SG_ 128 C_Time_Sync2 4;
BA_ "GenSigSendType" SG_ 206 ROABDC_DataByte7 2;
BA_ "GenSigSendType" SG_ 209 C_UWB_MASTER_Decrypt_FB 4;
BA_ "GenSigSendType" SG_ 210 C_UWB_MASTER_To_BDCFOBRSDResul 4;
BA_ "GenSigSendType" SG_ 211 C_UWB_MCU_OTA_Cmd 4;
BA_ "GenSigSendType" SG_ 212 C_UWB_IC_OTA_Cmd 4;
BA_ "GenSigSendType" SG_ 213 C_UWB_MCU_Download_Data 4;
BA_ "GenSigSendType" SG_ 214 C_UWB_IC_Download_Data 4;
BA_ "GenSigSendType" SG_ 224 C_UWB_INT_Decrypt_FB 4;
BA_ "GenSigSendType" SG_ 225 C_UWB_INT_To_BDCFOBRSDResult 4;
BA_ "GenSigSendType" SG_ 226 C_UWB_INT_MCU_Bootloader 4;
BA_ "GenSigSendType" SG_ 226 C_UWB_INT_MCU_Flash_Erase 4;
BA_ "GenSigSendType" SG_ 226 C_UWB_INT_MCU_CRC32 4;
BA_ "GenSigSendType" SG_ 227 C_UWB_INT_IC_Bootloader 4;
BA_ "GenSigSendType" SG_ 227 C_UWB_INT_IC_Flash_Erase 4;
BA_ "GenSigSendType" SG_ 227 C_UWB_INT_IC_CRC32 4;
BA_ "GenSigSendType" SG_ 256 C_BDC_Status 4;
BA_ "GenSigSendType" SG_ 256 C_DigitalKey_Enable 4;
BA_ "GenSigSendType" SG_ 256 C_DeviceOnWPC 4;
BA_ "GenSigSendType" SG_ 256 C_FobFoundWlcmArea 4;
BA_ "GenSigSendType" SG_ 256 C_PuddleLpOnReq 4;
BA_ "GenSigSendType" SG_ 256 C_OwnerKey_Reg_Status 4;
BA_ "GenSigSendType" SG_ 256 C_SharedKey_Reg_Status 4;
BA_ "GenSigSendType" SG_ 256 C_CardKey_Enable 4;
BA_ "GenSigSendType" SG_ 257 Radar_ROA_SnsrRunReq 4;
BA_ "GenSigSendType" SG_ 257 Radar_ROA_DiaReq 4;
BA_ "GenSigSendType" SG_ 257 Radar_ROA_EngSta 4;
BA_ "GenSigSendType" SG_ 272 C_WPC_Status 4;
BA_ "GenSigSendType" SG_ 272 C_WPCNFC_Option 4;
BA_ "GenSigSendType" SG_ 277 C_BTAddIRK_Update 4;
BA_ "GenSigSendType" SG_ 277 C_OP_ADV_State 4;
BA_ "GenSigSendType" SG_ 277 C_Passive_ADV_State 4;
BA_ "GenSigSendType" SG_ 277 C_NewDeviceConnetStatus 4;
BA_ "GenSigSendType" SG_ 277 C_BLE_Option 4;
BA_ "GenSigSendType" SG_ 277 C_ConnectedDeviceInfo 4;
BA_ "GenSigSendType" SG_ 288 C_DHL_Status 4;
BA_ "SignalCategory" SG_ 288 C_DHLToggleDetected 10;
BA_ "GenSigSendType" SG_ 288 C_DHLToggleDetected 4;
BA_ "SignalCategory" SG_ 288 C_DHLUnlockDetected 10;
BA_ "GenSigSendType" SG_ 288 C_DHLUnlockDetected 4;
BA_ "SignalCategory" SG_ 288 C_DHLLockDetected 10;
BA_ "GenSigSendType" SG_ 288 C_DHLLockDetected 4;
BA_ "GenSigSendType" SG_ 288 C_DHLPhnDetected 4;
BA_ "GenSigSendType" SG_ 288 C_DHLDiagnostics 4;
BA_ "SignalCategory" SG_ 288 C_DHL_RainState 10;
BA_ "GenSigSendType" SG_ 288 C_DHL_RainState 4;
BA_ "GenSigSendType" SG_ 304 C_DHR_Status 4;
BA_ "SignalCategory" SG_ 304 C_DHRToggleDetected 10;
BA_ "GenSigSendType" SG_ 304 C_DHRToggleDetected 4;
BA_ "SignalCategory" SG_ 304 C_DHRUnlockDetected 10;
BA_ "GenSigSendType" SG_ 304 C_DHRUnlockDetected 4;
BA_ "SignalCategory" SG_ 304 C_DHRLockDetected 10;
BA_ "GenSigSendType" SG_ 304 C_DHRLockDetected 4;
BA_ "GenSigSendType" SG_ 304 C_DHRPhnDetected 4;
BA_ "GenSigSendType" SG_ 304 C_DHRDiagnostics 4;
BA_ "SignalCategory" SG_ 304 C_DHR_RainState 10;
BA_ "GenSigSendType" SG_ 304 C_DHR_RainState 4;
BA_ "GenSigSendType" SG_ 320 C_BLE_RSSI1 4;
BA_ "GenSigSendType" SG_ 320 C_BLE_RSSI2 4;
BA_ "GenSigSendType" SG_ 320 C_BLE_RSSI3 4;
BA_ "GenSigSendType" SG_ 320 C_BLE_RSSI4 4;
BA_ "GenSigSendType" SG_ 353 C_UWB_FRNK_Decrypt_FB 4;
BA_ "GenSigSendType" SG_ 356 C_UWB_FRNK_To_BDCFOBRSDResult 4;
BA_ "GenSigSendType" SG_ 357 Radar_ROA_SW_Ver_Major 4;
BA_ "GenSigSendType" SG_ 357 Radar_ROA_SW_Ver_Minor1 4;
BA_ "GenSigSendType" SG_ 357 Radar_ROA_SW_Ver_Minor2 4;
BA_ "GenSigSendType" SG_ 357 Radar_ROA_ClassStat 4;
BA_ "GenSigSendType" SG_ 357 Radar_ROA_SnSrStat 4;
BA_ "GenSigSendType" SG_ 357 Radar_ROA_DetInfo 4;
BA_ "GenSigSendType" SG_ 357 Radar_ROA_SnSrBlckgeErrStat 4;
BA_ "GenSigSendType" SG_ 357 Radar_ROA_SnSrErrStat 4;
BA_ "GenSigSendType" SG_ 357 Radar_ROA_RegionOpt 4;
BA_ "GenSigSendType" SG_ 358 C_UWB_FRNK_IC_Bootloader 4;
BA_ "GenSigSendType" SG_ 358 C_UWB_FRNK_IC_Flash_Erase 4;
BA_ "GenSigSendType" SG_ 358 C_UWB_FRNK_IC_CRC32 4;
BA_ "GenSigSendType" SG_ 362 C_UWB_FRUNK_Status1 4;
BA_ "GenSigSendType" SG_ 362 C_UWB_FRUNK_Status2 4;
BA_ "GenSigSendType" SG_ 362 C_UWB_FRUNK_Status3 4;
BA_ "GenSigSendType" SG_ 362 C_UWB_FRUNK_Status4 4;
BA_ "GenSigSendType" SG_ 362 C_UWB_FRUNK_Status5 4;
BA_ "GenSigSendType" SG_ 362 C_UWB_FRUNK_Status6 4;
BA_ "GenSigSendType" SG_ 362 C_UWB_FRUNK_Status7 4;
BA_ "GenSigSendType" SG_ 362 C_UWB_FRUNK_Status8 4;
BA_ "GenSigSendType" SG_ 362 C_UWB_FRNK_DTC 4;
BA_ "GenSigSendType" SG_ 362 C_UWB_FRUNK_Option 4;
BA_ "GenSigSendType" SG_ 367 C_UWB_FRNK_MCU_Bootloader 4;
BA_ "GenSigSendType" SG_ 367 C_UWB_FRNK_MCU_Flash_Erase 4;
BA_ "GenSigSendType" SG_ 367 C_UWB_FRNK_MCU_CRC32 4;
BA_ "GenSigSendType" SG_ 368 C_UWB_FR_Status1 4;
BA_ "GenSigSendType" SG_ 368 C_UWB_FR_Status2 4;
BA_ "GenSigSendType" SG_ 368 C_UWB_FR_Status3 4;
BA_ "GenSigSendType" SG_ 368 C_UWB_FR_Status4 4;
BA_ "GenSigSendType" SG_ 368 C_UWB_FR_Status5 4;
BA_ "GenSigSendType" SG_ 368 C_UWB_FR_Status6 4;
BA_ "GenSigSendType" SG_ 368 C_UWB_FR_Status7 4;
BA_ "GenSigSendType" SG_ 368 C_UWB_FR_Status8 4;
BA_ "GenSigSendType" SG_ 368 C_UWB_FR_DTC 4;
BA_ "GenSigSendType" SG_ 368 C_UWB_FR_Option 4;
BA_ "GenSigSendType" SG_ 372 C_UWB_FL_To_BDCFOBRSDResult 4;
BA_ "GenSigSendType" SG_ 373 C_UWB_FL_MCU_Bootloader 4;
BA_ "GenSigSendType" SG_ 373 C_UWB_FL_MCU_Flash_Erase 4;
BA_ "GenSigSendType" SG_ 373 C_UWB_FL_MCU_CRC32 4;
BA_ "GenSigSendType" SG_ 374 C_UWB_FL_IC_Bootloader 4;
BA_ "GenSigSendType" SG_ 374 C_UWB_FL_IC_Flash_Erase 4;
BA_ "GenSigSendType" SG_ 374 C_UWB_FL_IC_CRC32 4;
BA_ "GenSigSendType" SG_ 375 C_UWB_FL_Decrypt_FB 4;
BA_ "GenSigSendType" SG_ 376 C_UWB_FL_Status1 4;
BA_ "GenSigSendType" SG_ 376 C_UWB_FL_Status2 4;
BA_ "GenSigSendType" SG_ 376 C_UWB_FL_Status3 4;
BA_ "GenSigSendType" SG_ 376 C_UWB_FL_Status4 4;
BA_ "GenSigSendType" SG_ 376 C_UWB_FL_Status5 4;
BA_ "GenSigSendType" SG_ 376 C_UWB_FL_Status6 4;
BA_ "GenSigSendType" SG_ 376 C_UWB_FL_Status7 4;
BA_ "GenSigSendType" SG_ 376 C_UWB_FL_Status8 4;
BA_ "GenSigSendType" SG_ 376 C_UWB_FL_DTC 4;
BA_ "GenSigSendType" SG_ 376 C_UWB_FL_Option 4;
BA_ "GenSigSendType" SG_ 384 C_UWB_INT_Status1 4;
BA_ "GenSigSendType" SG_ 384 C_UWB_INT_Status2 4;
BA_ "GenSigSendType" SG_ 384 C_UWB_INT_Status3 4;
BA_ "GenSigSendType" SG_ 384 C_UWB_INT_Status4 4;
BA_ "GenSigSendType" SG_ 384 C_UWB_INT_Status5 4;
BA_ "GenSigSendType" SG_ 384 C_UWB_INT_Status6 4;
BA_ "GenSigSendType" SG_ 384 C_UWB_INT_Status7 4;
BA_ "GenSigSendType" SG_ 384 C_UWB_INT_Status8 4;
BA_ "GenSigSendType" SG_ 384 C_UWB_INT_DTC 4;
BA_ "GenSigSendType" SG_ 384 C_UWB_INT_Option 4;
BA_ "GenSigSendType" SG_ 387 C_UWB_FR_Decrypt_FB 4;
BA_ "GenSigSendType" SG_ 388 C_UWB_FR_To_BDCFOBRSDResult 4;
BA_ "GenSigSendType" SG_ 389 C_UWB_FR_MCU_Bootloader 4;
BA_ "GenSigSendType" SG_ 389 C_UWB_FR_MCU_Flash_Erase 4;
BA_ "GenSigSendType" SG_ 389 C_UWB_FR_MCU_CRC32 4;
BA_ "GenSigSendType" SG_ 390 C_UWB_FR_IC_Bootloader 4;
BA_ "GenSigSendType" SG_ 390 C_UWB_FR_IC_Flash_Erase 4;
BA_ "GenSigSendType" SG_ 390 C_UWB_FR_IC_CRC32 4;
BA_REL_ "GenSigTimeoutTime" BU_SG_REL_ BDC SG_ 16 C_WPC_NFCDetection 0;
BA_REL_ "GenSigTimeoutTime" BU_SG_REL_ Devtool SG_ 16 C_WPC_NFCDetection 0;
BA_REL_ "GenSigTimeoutTime" BU_SG_REL_ BDC SG_ 16 C_WPC_NFCReset 0;
BA_REL_ "GenSigTimeoutTime" BU_SG_REL_ DHL SG_ 17 C_WlightOnCmd 0;
BA_REL_ "GenSigTimeoutTime" BU_SG_REL_ DHR SG_ 17 C_WlightOnCmd 0;
BA_REL_ "GenSigTimeoutTime" BU_SG_REL_ WPC SG_ 17 C_WPCNFCcmd 0;
BA_REL_ "GenSigTimeoutTime" BU_SG_REL_ DHL SG_ 17 C_DRNFCcmd 0;
BA_REL_ "GenSigTimeoutTime" BU_SG_REL_ DHR SG_ 17 C_DRNFCcmd 0;
BA_REL_ "GenSigTimeoutTime" BU_SG_REL_ WPC SG_ 17 C_BDCWPCNFCCmd 0;
BA_REL_ "GenSigTimeoutTime" BU_SG_REL_ DHL SG_ 17 C_BDCDHLNFCCmd 0;
BA_REL_ "GenSigTimeoutTime" BU_SG_REL_ DHR SG_ 17 C_BDCDHRNFCCmd 0;
BA_REL_ "GenSigTimeoutTime" BU_SG_REL_ DHL SG_ 17 C_DRV_DRHdlLedOnSta 0;
BA_REL_ "GenSigTimeoutTime" BU_SG_REL_ DHR SG_ 17 C_AST_DRHdlLedOnSta 0;
BA_REL_ "GenSigTimeoutTime" BU_SG_REL_ UWB_BLE SG_ 18 C_DK_IDSet 0;
BA_REL_ "GenSigTimeoutTime" BU_SG_REL_ UWB_BLE SG_ 18 C_DK_IDDel 0;
BA_REL_ "GenSigTimeoutTime" BU_SG_REL_ UWB_BLE SG_ 18 C_OwnerDeviceSearchingReq 0;
BA_REL_ "GenSigTimeoutTime" BU_SG_REL_ UWB_BLE SG_ 18 C_TimeSync_REQ 0;
BA_REL_ "GenSigTimeoutTime" BU_SG_REL_ UWB_BLE SG_ 18 C_BLE_Connection_CMD 0;
BA_REL_ "GenSigTimeoutTime" BU_SG_REL_ UWB_BLE SG_ 18 C_BDC_DecryptFB1 0;
BA_REL_ "GenSigTimeoutTime" BU_SG_REL_ UWB_BLE SG_ 18 C_BDC_DecryptFB2 0;
BA_REL_ "GenSigTimeoutTime" BU_SG_REL_ UWB_FL SG_ 18 C_BDC_DecryptFB2 0;
BA_REL_ "GenSigTimeoutTime" BU_SG_REL_ UWB_FR SG_ 18 C_BDC_DecryptFB2 0;
BA_REL_ "GenSigTimeoutTime" BU_SG_REL_ UWB_FRNK SG_ 18 C_BDC_DecryptFB2 0;
BA_REL_ "GenSigTimeoutTime" BU_SG_REL_ UWB_INT SG_ 18 C_BDC_DecryptFB2 0;
BA_REL_ "GenSigTimeoutTime" BU_SG_REL_ UWB_RL SG_ 18 C_BDC_DecryptFB2 0;
BA_REL_ "GenSigTimeoutTime" BU_SG_REL_ UWB_RR SG_ 18 C_BDC_DecryptFB2 0;
BA_REL_ "GenSigTimeoutTime" BU_SG_REL_ UWB_TRNK SG_ 18 C_BDC_DecryptFB2 0;
BA_REL_ "GenSigTimeoutTime" BU_SG_REL_ UWB_BLE SG_ 19 C_BDCLocalRN_Target 0;
BA_REL_ "GenSigTimeoutTime" BU_SG_REL_ UWB_FL SG_ 19 C_BDCLocalRN_Target 0;
BA_REL_ "GenSigTimeoutTime" BU_SG_REL_ UWB_FR SG_ 19 C_BDCLocalRN_Target 0;
BA_REL_ "GenSigTimeoutTime" BU_SG_REL_ UWB_FRNK SG_ 19 C_BDCLocalRN_Target 0;
BA_REL_ "GenSigTimeoutTime" BU_SG_REL_ UWB_INT SG_ 19 C_BDCLocalRN_Target 0;
BA_REL_ "GenSigTimeoutTime" BU_SG_REL_ UWB_RL SG_ 19 C_BDCLocalRN_Target 0;
BA_REL_ "GenSigTimeoutTime" BU_SG_REL_ UWB_RR SG_ 19 C_BDCLocalRN_Target 0;
BA_REL_ "GenSigTimeoutTime" BU_SG_REL_ UWB_TRNK SG_ 19 C_BDCLocalRN_Target 0;
BA_REL_ "GenSigTimeoutTime" BU_SG_REL_ UWB_BLE SG_ 19 C_BDCLocalRN_TRCode 0;
BA_REL_ "GenSigTimeoutTime" BU_SG_REL_ UWB_FL SG_ 19 C_BDCLocalRN_TRCode 0;
BA_REL_ "GenSigTimeoutTime" BU_SG_REL_ UWB_FR SG_ 19 C_BDCLocalRN_TRCode 0;
BA_REL_ "GenSigTimeoutTime" BU_SG_REL_ UWB_FRNK SG_ 19 C_BDCLocalRN_TRCode 0;
BA_REL_ "GenSigTimeoutTime" BU_SG_REL_ UWB_INT SG_ 19 C_BDCLocalRN_TRCode 0;
BA_REL_ "GenSigTimeoutTime" BU_SG_REL_ UWB_RL SG_ 19 C_BDCLocalRN_TRCode 0;
BA_REL_ "GenSigTimeoutTime" BU_SG_REL_ UWB_RR SG_ 19 C_BDCLocalRN_TRCode 0;
BA_REL_ "GenSigTimeoutTime" BU_SG_REL_ UWB_TRNK SG_ 19 C_BDCLocalRN_TRCode 0;
BA_REL_ "GenSigTimeoutTime" BU_SG_REL_ UWB_BLE SG_ 19 C_BDCLocalRN_CMD 0;
BA_REL_ "GenSigTimeoutTime" BU_SG_REL_ UWB_FL SG_ 19 C_BDCLocalRN_CMD 0;
BA_REL_ "GenSigTimeoutTime" BU_SG_REL_ UWB_FR SG_ 19 C_BDCLocalRN_CMD 0;
BA_REL_ "GenSigTimeoutTime" BU_SG_REL_ UWB_FRNK SG_ 19 C_BDCLocalRN_CMD 0;
BA_REL_ "GenSigTimeoutTime" BU_SG_REL_ UWB_INT SG_ 19 C_BDCLocalRN_CMD 0;
BA_REL_ "GenSigTimeoutTime" BU_SG_REL_ UWB_RL SG_ 19 C_BDCLocalRN_CMD 0;
BA_REL_ "GenSigTimeoutTime" BU_SG_REL_ UWB_RR SG_ 19 C_BDCLocalRN_CMD 0;
BA_REL_ "GenSigTimeoutTime" BU_SG_REL_ UWB_TRNK SG_ 19 C_BDCLocalRN_CMD 0;
BA_REL_ "GenSigTimeoutTime" BU_SG_REL_ UWB_BLE SG_ 19 C_BDCLocalRndNum 0;
BA_REL_ "GenSigTimeoutTime" BU_SG_REL_ UWB_FL SG_ 19 C_BDCLocalRndNum 0;
BA_REL_ "GenSigTimeoutTime" BU_SG_REL_ UWB_FR SG_ 19 C_BDCLocalRndNum 0;
BA_REL_ "GenSigTimeoutTime" BU_SG_REL_ UWB_FRNK SG_ 19 C_BDCLocalRndNum 0;
BA_REL_ "GenSigTimeoutTime" BU_SG_REL_ UWB_INT SG_ 19 C_BDCLocalRndNum 0;
BA_REL_ "GenSigTimeoutTime" BU_SG_REL_ UWB_RL SG_ 19 C_BDCLocalRndNum 0;
BA_REL_ "GenSigTimeoutTime" BU_SG_REL_ UWB_RR SG_ 19 C_BDCLocalRndNum 0;
BA_REL_ "GenSigTimeoutTime" BU_SG_REL_ UWB_TRNK SG_ 19 C_BDCLocalRndNum 0;
BA_REL_ "GenSigTimeoutTime" BU_SG_REL_ UWB_BLE SG_ 20 C_UWB_Ranging_CMD_ID 0;
BA_REL_ "GenSigTimeoutTime" BU_SG_REL_ UWB_FL SG_ 20 C_UWB_Ranging_CMD_ID 0;
BA_REL_ "GenSigTimeoutTime" BU_SG_REL_ UWB_FR SG_ 20 C_UWB_Ranging_CMD_ID 0;
BA_REL_ "GenSigTimeoutTime" BU_SG_REL_ UWB_FRNK SG_ 20 C_UWB_Ranging_CMD_ID 0;
BA_REL_ "GenSigTimeoutTime" BU_SG_REL_ UWB_INT SG_ 20 C_UWB_Ranging_CMD_ID 0;
BA_REL_ "GenSigTimeoutTime" BU_SG_REL_ UWB_RL SG_ 20 C_UWB_Ranging_CMD_ID 0;
BA_REL_ "GenSigTimeoutTime" BU_SG_REL_ UWB_RR SG_ 20 C_UWB_Ranging_CMD_ID 0;
BA_REL_ "GenSigTimeoutTime" BU_SG_REL_ UWB_TRNK SG_ 20 C_UWB_Ranging_CMD_ID 0;
BA_REL_ "GenSigTimeoutTime" BU_SG_REL_ UWB_BLE SG_ 20 C_UWB_Ranging_CMD_Value 0;
BA_REL_ "GenSigTimeoutTime" BU_SG_REL_ UWB_FL SG_ 20 C_UWB_Ranging_CMD_Value 0;
BA_REL_ "GenSigTimeoutTime" BU_SG_REL_ UWB_FR SG_ 20 C_UWB_Ranging_CMD_Value 0;
BA_REL_ "GenSigTimeoutTime" BU_SG_REL_ UWB_FRNK SG_ 20 C_UWB_Ranging_CMD_Value 0;
BA_REL_ "GenSigTimeoutTime" BU_SG_REL_ UWB_INT SG_ 20 C_UWB_Ranging_CMD_Value 0;
BA_REL_ "GenSigTimeoutTime" BU_SG_REL_ UWB_RL SG_ 20 C_UWB_Ranging_CMD_Value 0;
BA_REL_ "GenSigTimeoutTime" BU_SG_REL_ UWB_RR SG_ 20 C_UWB_Ranging_CMD_Value 0;
BA_REL_ "GenSigTimeoutTime" BU_SG_REL_ UWB_TRNK SG_ 20 C_UWB_Ranging_CMD_Value 0;
BA_REL_ "GenSigTimeoutTime" BU_SG_REL_ UWB_BLE SG_ 21 C_Warn_DrvDrSwSta 0;
BA_REL_ "GenSigTimeoutTime" BU_SG_REL_ UWB_BLE SG_ 21 C_Warn_AsstDrSwSta 0;
BA_REL_ "GenSigTimeoutTime" BU_SG_REL_ UWB_BLE SG_ 21 C_Warn_RrLftDrSwSta 0;
BA_REL_ "GenSigTimeoutTime" BU_SG_REL_ UWB_BLE SG_ 21 C_Warn_RrRtDrSwSta 0;
BA_REL_ "GenSigTimeoutTime" BU_SG_REL_ UWB_BLE SG_ 21 C_Trunk_TrnkTlgtSwSta 0;
BA_REL_ "GenSigTimeoutTime" BU_SG_REL_ ROA SG_ 21 C_SMK_TrmnlMngrSta 0;
BA_REL_ "GenSigTimeoutTime" BU_SG_REL_ UWB_BLE SG_ 21 C_SMK_TrmnlMngrSta 0;
BA_REL_ "GenSigTimeoutTime" BU_SG_REL_ UWB_BLE SG_ 21 C_Window_DrvrSdWdwSta_BCM 0;
BA_REL_ "GenSigTimeoutTime" BU_SG_REL_ UWB_BLE SG_ 21 C_Window_AsstSdWdwSta_BCM 0;
BA_REL_ "GenSigTimeoutTime" BU_SG_REL_ UWB_BLE SG_ 21 C_Window_RrLftWdwSta_BCM 0;
BA_REL_ "GenSigTimeoutTime" BU_SG_REL_ UWB_BLE SG_ 21 C_Window_RrRtWdwSta_BCM 0;
BA_REL_ "GenSigTimeoutTime" BU_SG_REL_ UWB_BLE SG_ 21 C_BodyTypeSta 0;
BA_REL_ "GenSigTimeoutTime" BU_SG_REL_ ROA SG_ 21 C_SunRoofOptionSta 0;
BA_REL_ "GenSigTimeoutTime" BU_SG_REL_ UWB_BLE SG_ 21 C_SunRoofOptionSta 0;
BA_REL_ "GenSigTimeoutTime" BU_SG_REL_ UWB_BLE SG_ 22 C_SSB_StrtStpBtnSw1Sta 0;
BA_REL_ "GenSigTimeoutTime" BU_SG_REL_ UWB_BLE SG_ 22 C_SSB_StrtStpBtnSw2Sta 0;
BA_REL_ "GenSigTimeoutTime" BU_SG_REL_ UWB_BLE SG_ 22 C_DoorLock_AsstDrUnLkSta 0;
BA_REL_ "GenSigTimeoutTime" BU_SG_REL_ UWB_BLE SG_ 22 C_DoorLock_DrvDrUnLkSta 0;
BA_REL_ "GenSigTimeoutTime" BU_SG_REL_ UWB_BLE SG_ 22 C_DoorLock_RrLftDrUnLkSta 0;
BA_REL_ "GenSigTimeoutTime" BU_SG_REL_ UWB_BLE SG_ 22 C_DoorLock_RrRtDrUnLkSta 0;
BA_REL_ "GenSigTimeoutTime" BU_SG_REL_ UWB_BLE SG_ 22 C_DriveTypeOption 0;
BA_REL_ "GenSigTimeoutTime" BU_SG_REL_ UWB_BLE SG_ 22 C_RSPA_Opt 0;
BA_REL_ "GenSigTimeoutTime" BU_SG_REL_ UWB_BLE SG_ 31 BDCToBLEEncryptData1 0;
BA_REL_ "GenSigTimeoutTime" BU_SG_REL_ BDC SG_ 32 C_DHLNFCDetected 0;
BA_REL_ "GenSigTimeoutTime" BU_SG_REL_ BDC SG_ 32 C_DHLWlightStatus 0;
BA_REL_ "GenSigTimeoutTime" BU_SG_REL_ BDC SG_ 32 C_DHL_NFCReset 0;
BA_REL_ "GenSigTimeoutTime" BU_SG_REL_ UWB_BLE SG_ 33 BDCToBLEEncryptData2 0;
BA_REL_ "GenSigTimeoutTime" BU_SG_REL_ UWB_BLE SG_ 34 BDCToBLEEncryptData3 0;
BA_REL_ "GenSigTimeoutTime" BU_SG_REL_ UWB_BLE SG_ 35 BDCToBLEEncryptData4 0;
BA_REL_ "GenSigTimeoutTime" BU_SG_REL_ UWB_BLE SG_ 36 BDCToBLEEncryptData5 0;
BA_REL_ "GenSigTimeoutTime" BU_SG_REL_ UWB_BLE SG_ 37 BDCToBLEEncryptData6 0;
BA_REL_ "GenSigTimeoutTime" BU_SG_REL_ UWB_BLE SG_ 38 BDCToUWBEncryptData1 0;
BA_REL_ "GenSigTimeoutTime" BU_SG_REL_ UWB_FL SG_ 38 BDCToUWBEncryptData1 0;
BA_REL_ "GenSigTimeoutTime" BU_SG_REL_ UWB_FR SG_ 38 BDCToUWBEncryptData1 0;
BA_REL_ "GenSigTimeoutTime" BU_SG_REL_ UWB_FRNK SG_ 38 BDCToUWBEncryptData1 0;
BA_REL_ "GenSigTimeoutTime" BU_SG_REL_ UWB_INT SG_ 38 BDCToUWBEncryptData1 0;
BA_REL_ "GenSigTimeoutTime" BU_SG_REL_ UWB_RL SG_ 38 BDCToUWBEncryptData1 0;
BA_REL_ "GenSigTimeoutTime" BU_SG_REL_ UWB_RR SG_ 38 BDCToUWBEncryptData1 0;
BA_REL_ "GenSigTimeoutTime" BU_SG_REL_ UWB_TRNK SG_ 38 BDCToUWBEncryptData1 0;
BA_REL_ "GenSigTimeoutTime" BU_SG_REL_ UWB_BLE SG_ 39 BDCToUWBEncryptData2 0;
BA_REL_ "GenSigTimeoutTime" BU_SG_REL_ UWB_FL SG_ 39 BDCToUWBEncryptData2 0;
BA_REL_ "GenSigTimeoutTime" BU_SG_REL_ UWB_FR SG_ 39 BDCToUWBEncryptData2 0;
BA_REL_ "GenSigTimeoutTime" BU_SG_REL_ UWB_FRNK SG_ 39 BDCToUWBEncryptData2 0;
BA_REL_ "GenSigTimeoutTime" BU_SG_REL_ UWB_INT SG_ 39 BDCToUWBEncryptData2 0;
BA_REL_ "GenSigTimeoutTime" BU_SG_REL_ UWB_RL SG_ 39 BDCToUWBEncryptData2 0;
BA_REL_ "GenSigTimeoutTime" BU_SG_REL_ UWB_RR SG_ 39 BDCToUWBEncryptData2 0;
BA_REL_ "GenSigTimeoutTime" BU_SG_REL_ UWB_TRNK SG_ 39 BDCToUWBEncryptData2 0;
BA_REL_ "GenSigTimeoutTime" BU_SG_REL_ UWB_BLE SG_ 40 BDCToUWBEncryptData3 0;
BA_REL_ "GenSigTimeoutTime" BU_SG_REL_ UWB_FL SG_ 40 BDCToUWBEncryptData3 0;
BA_REL_ "GenSigTimeoutTime" BU_SG_REL_ UWB_FR SG_ 40 BDCToUWBEncryptData3 0;
BA_REL_ "GenSigTimeoutTime" BU_SG_REL_ UWB_FRNK SG_ 40 BDCToUWBEncryptData3 0;
BA_REL_ "GenSigTimeoutTime" BU_SG_REL_ UWB_INT SG_ 40 BDCToUWBEncryptData3 0;
BA_REL_ "GenSigTimeoutTime" BU_SG_REL_ UWB_RL SG_ 40 BDCToUWBEncryptData3 0;
BA_REL_ "GenSigTimeoutTime" BU_SG_REL_ UWB_RR SG_ 40 BDCToUWBEncryptData3 0;
BA_REL_ "GenSigTimeoutTime" BU_SG_REL_ UWB_TRNK SG_ 40 BDCToUWBEncryptData3 0;
BA_REL_ "GenSigTimeoutTime" BU_SG_REL_ UWB_BLE SG_ 41 BDCToUWBEncryptData4 0;
BA_REL_ "GenSigTimeoutTime" BU_SG_REL_ UWB_FL SG_ 41 BDCToUWBEncryptData4 0;
BA_REL_ "GenSigTimeoutTime" BU_SG_REL_ UWB_FR SG_ 41 BDCToUWBEncryptData4 0;
BA_REL_ "GenSigTimeoutTime" BU_SG_REL_ UWB_FRNK SG_ 41 BDCToUWBEncryptData4 0;
BA_REL_ "GenSigTimeoutTime" BU_SG_REL_ UWB_INT SG_ 41 BDCToUWBEncryptData4 0;
BA_REL_ "GenSigTimeoutTime" BU_SG_REL_ UWB_RL SG_ 41 BDCToUWBEncryptData4 0;
BA_REL_ "GenSigTimeoutTime" BU_SG_REL_ UWB_RR SG_ 41 BDCToUWBEncryptData4 0;
BA_REL_ "GenSigTimeoutTime" BU_SG_REL_ UWB_TRNK SG_ 41 BDCToUWBEncryptData4 0;
BA_REL_ "GenSigTimeoutTime" BU_SG_REL_ UWB_BLE SG_ 47 BDCToUWBEncryptData5 0;
BA_REL_ "GenSigTimeoutTime" BU_SG_REL_ UWB_FL SG_ 47 BDCToUWBEncryptData5 0;
BA_REL_ "GenSigTimeoutTime" BU_SG_REL_ UWB_FR SG_ 47 BDCToUWBEncryptData5 0;
BA_REL_ "GenSigTimeoutTime" BU_SG_REL_ UWB_FRNK SG_ 47 BDCToUWBEncryptData5 0;
BA_REL_ "GenSigTimeoutTime" BU_SG_REL_ UWB_INT SG_ 47 BDCToUWBEncryptData5 0;
BA_REL_ "GenSigTimeoutTime" BU_SG_REL_ UWB_RL SG_ 47 BDCToUWBEncryptData5 0;
BA_REL_ "GenSigTimeoutTime" BU_SG_REL_ UWB_RR SG_ 47 BDCToUWBEncryptData5 0;
BA_REL_ "GenSigTimeoutTime" BU_SG_REL_ UWB_TRNK SG_ 47 BDCToUWBEncryptData5 0;
BA_REL_ "GenSigTimeoutTime" BU_SG_REL_ BDC SG_ 48 C_DHRNFCDetected 0;
BA_REL_ "GenSigTimeoutTime" BU_SG_REL_ BDC SG_ 48 C_DHRWlightStatus 0;
BA_REL_ "GenSigTimeoutTime" BU_SG_REL_ BDC SG_ 48 C_DHR_NFCReset 0;
BA_REL_ "GenSigTimeoutTime" BU_SG_REL_ UWB_BLE SG_ 49 BDCToUWBEncryptData6 0;
BA_REL_ "GenSigTimeoutTime" BU_SG_REL_ UWB_FL SG_ 49 BDCToUWBEncryptData6 0;
BA_REL_ "GenSigTimeoutTime" BU_SG_REL_ UWB_FR SG_ 49 BDCToUWBEncryptData6 0;
BA_REL_ "GenSigTimeoutTime" BU_SG_REL_ UWB_FRNK SG_ 49 BDCToUWBEncryptData6 0;
BA_REL_ "GenSigTimeoutTime" BU_SG_REL_ UWB_INT SG_ 49 BDCToUWBEncryptData6 0;
BA_REL_ "GenSigTimeoutTime" BU_SG_REL_ UWB_RL SG_ 49 BDCToUWBEncryptData6 0;
BA_REL_ "GenSigTimeoutTime" BU_SG_REL_ UWB_RR SG_ 49 BDCToUWBEncryptData6 0;
BA_REL_ "GenSigTimeoutTime" BU_SG_REL_ UWB_TRNK SG_ 49 BDCToUWBEncryptData6 0;
BA_REL_ "GenSigTimeoutTime" BU_SG_REL_ ROA SG_ 64 BDCROADataByte0 0;
BA_REL_ "GenSigTimeoutTime" BU_SG_REL_ ROA SG_ 64 BDCROADataByte1 0;
BA_REL_ "GenSigTimeoutTime" BU_SG_REL_ ROA SG_ 64 BDCROADataByte2 0;
BA_REL_ "GenSigTimeoutTime" BU_SG_REL_ ROA SG_ 64 BDCROADataByte3 0;
BA_REL_ "GenSigTimeoutTime" BU_SG_REL_ ROA SG_ 64 BDCROADataByte4 0;
BA_REL_ "GenSigTimeoutTime" BU_SG_REL_ ROA SG_ 64 BDCROADataByte5 0;
BA_REL_ "GenSigTimeoutTime" BU_SG_REL_ ROA SG_ 64 BDCROADataByte6 0;
BA_REL_ "GenSigTimeoutTime" BU_SG_REL_ ROA SG_ 64 BDCROADataByte7 0;
BA_REL_ "GenSigTimeoutTime" BU_SG_REL_ BDC SG_ 96 C_BLENewDevicePairingResult 0;
BA_REL_ "GenSigTimeoutTime" BU_SG_REL_ BDC SG_ 96 C_BLE_Decrypt_FB 0;
BA_REL_ "GenSigTimeoutTime" BU_SG_REL_ BDC SG_ 111 BLEToBDCEncryptData1 0;
BA_REL_ "GenSigTimeoutTime" BU_SG_REL_ BDC SG_ 112 C_Time_Sync1 0;
BA_REL_ "GenSigTimeoutTime" BU_SG_REL_ UWB_FL SG_ 112 C_Time_Sync1 0;
BA_REL_ "GenSigTimeoutTime" BU_SG_REL_ UWB_FR SG_ 112 C_Time_Sync1 0;
BA_REL_ "GenSigTimeoutTime" BU_SG_REL_ UWB_FRNK SG_ 112 C_Time_Sync1 0;
BA_REL_ "GenSigTimeoutTime" BU_SG_REL_ UWB_INT SG_ 112 C_Time_Sync1 0;
BA_REL_ "GenSigTimeoutTime" BU_SG_REL_ UWB_RL SG_ 112 C_Time_Sync1 0;
BA_REL_ "GenSigTimeoutTime" BU_SG_REL_ UWB_RR SG_ 112 C_Time_Sync1 0;
BA_REL_ "GenSigTimeoutTime" BU_SG_REL_ UWB_TRNK SG_ 112 C_Time_Sync1 0;
BA_REL_ "GenSigTimeoutTime" BU_SG_REL_ BDC SG_ 113 BLEToBDCEncryptData2 0;
BA_REL_ "GenSigTimeoutTime" BU_SG_REL_ BDC SG_ 114 BLEToBDCEncryptData3 0;
BA_REL_ "GenSigTimeoutTime" BU_SG_REL_ BDC SG_ 115 BLEToBDCEncryptData4 0;
BA_REL_ "GenSigTimeoutTime" BU_SG_REL_ BDC SG_ 116 BLEToBDCEncryptData5 0;
BA_REL_ "GenSigTimeoutTime" BU_SG_REL_ BDC SG_ 117 BLEToBDCEncryptData6 0;
BA_REL_ "GenSigTimeoutTime" BU_SG_REL_ BDC SG_ 128 C_Time_Sync2 0;
BA_REL_ "GenSigTimeoutTime" BU_SG_REL_ UWB_FL SG_ 128 C_Time_Sync2 0;
BA_REL_ "GenSigTimeoutTime" BU_SG_REL_ UWB_FR SG_ 128 C_Time_Sync2 0;
BA_REL_ "GenSigTimeoutTime" BU_SG_REL_ UWB_FRNK SG_ 128 C_Time_Sync2 0;
BA_REL_ "GenSigTimeoutTime" BU_SG_REL_ UWB_INT SG_ 128 C_Time_Sync2 0;
BA_REL_ "GenSigTimeoutTime" BU_SG_REL_ UWB_RL SG_ 128 C_Time_Sync2 0;
BA_REL_ "GenSigTimeoutTime" BU_SG_REL_ UWB_RR SG_ 128 C_Time_Sync2 0;
BA_REL_ "GenSigTimeoutTime" BU_SG_REL_ UWB_TRNK SG_ 128 C_Time_Sync2 0;
BA_REL_ "GenSigTimeoutTime" BU_SG_REL_ BDC SG_ 206 ROABDC_DataByte0 0;
BA_REL_ "GenSigTimeoutTime" BU_SG_REL_ BDC SG_ 206 ROABDC_DataByte1 0;
BA_REL_ "GenSigTimeoutTime" BU_SG_REL_ BDC SG_ 206 ROABDC_DataByte2 0;
BA_REL_ "GenSigTimeoutTime" BU_SG_REL_ BDC SG_ 206 ROABDC_DataByte3 0;
BA_REL_ "GenSigTimeoutTime" BU_SG_REL_ BDC SG_ 206 ROABDC_DataByte4 0;
BA_REL_ "GenSigTimeoutTime" BU_SG_REL_ BDC SG_ 206 ROABDC_DataByte5 0;
BA_REL_ "GenSigTimeoutTime" BU_SG_REL_ BDC SG_ 206 ROABDC_DataByte6 0;
BA_REL_ "GenSigTimeoutTime" BU_SG_REL_ BDC SG_ 206 ROABDC_DataByte7 0;
BA_REL_ "GenSigTimeoutTime" BU_SG_REL_ BDC SG_ 209 C_UWB_MASTER_Decrypt_FB 0;
BA_REL_ "GenSigTimeoutTime" BU_SG_REL_ BDC SG_ 210 C_UWB_MASTER_To_BDCFOBRSDResul 0;
BA_REL_ "GenSigTimeoutTime" BU_SG_REL_ UWB_FL SG_ 211 C_UWB_MCU_OTA_Cmd 0;
BA_REL_ "GenSigTimeoutTime" BU_SG_REL_ UWB_FR SG_ 211 C_UWB_MCU_OTA_Cmd 0;
BA_REL_ "GenSigTimeoutTime" BU_SG_REL_ UWB_FRNK SG_ 211 C_UWB_MCU_OTA_Cmd 0;
BA_REL_ "GenSigTimeoutTime" BU_SG_REL_ UWB_INT SG_ 211 C_UWB_MCU_OTA_Cmd 0;
BA_REL_ "GenSigTimeoutTime" BU_SG_REL_ UWB_RL SG_ 211 C_UWB_MCU_OTA_Cmd 0;
BA_REL_ "GenSigTimeoutTime" BU_SG_REL_ UWB_RR SG_ 211 C_UWB_MCU_OTA_Cmd 0;
BA_REL_ "GenSigTimeoutTime" BU_SG_REL_ UWB_TRNK SG_ 211 C_UWB_MCU_OTA_Cmd 0;
BA_REL_ "GenSigTimeoutTime" BU_SG_REL_ UWB_FL SG_ 212 C_UWB_IC_OTA_Cmd 0;
BA_REL_ "GenSigTimeoutTime" BU_SG_REL_ UWB_FR SG_ 212 C_UWB_IC_OTA_Cmd 0;
BA_REL_ "GenSigTimeoutTime" BU_SG_REL_ UWB_FRNK SG_ 212 C_UWB_IC_OTA_Cmd 0;
BA_REL_ "GenSigTimeoutTime" BU_SG_REL_ UWB_INT SG_ 212 C_UWB_IC_OTA_Cmd 0;
BA_REL_ "GenSigTimeoutTime" BU_SG_REL_ UWB_RL SG_ 212 C_UWB_IC_OTA_Cmd 0;
BA_REL_ "GenSigTimeoutTime" BU_SG_REL_ UWB_RR SG_ 212 C_UWB_IC_OTA_Cmd 0;
BA_REL_ "GenSigTimeoutTime" BU_SG_REL_ UWB_TRNK SG_ 212 C_UWB_IC_OTA_Cmd 0;
BA_REL_ "GenSigTimeoutTime" BU_SG_REL_ UWB_FL SG_ 213 C_UWB_MCU_Download_Data 0;
BA_REL_ "GenSigTimeoutTime" BU_SG_REL_ UWB_FR SG_ 213 C_UWB_MCU_Download_Data 0;
BA_REL_ "GenSigTimeoutTime" BU_SG_REL_ UWB_FRNK SG_ 213 C_UWB_MCU_Download_Data 0;
BA_REL_ "GenSigTimeoutTime" BU_SG_REL_ UWB_INT SG_ 213 C_UWB_MCU_Download_Data 0;
BA_REL_ "GenSigTimeoutTime" BU_SG_REL_ UWB_RL SG_ 213 C_UWB_MCU_Download_Data 0;
BA_REL_ "GenSigTimeoutTime" BU_SG_REL_ UWB_RR SG_ 213 C_UWB_MCU_Download_Data 0;
BA_REL_ "GenSigTimeoutTime" BU_SG_REL_ UWB_TRNK SG_ 213 C_UWB_MCU_Download_Data 0;
BA_REL_ "GenSigTimeoutTime" BU_SG_REL_ UWB_FL SG_ 214 C_UWB_IC_Download_Data 0;
BA_REL_ "GenSigTimeoutTime" BU_SG_REL_ UWB_FR SG_ 214 C_UWB_IC_Download_Data 0;
BA_REL_ "GenSigTimeoutTime" BU_SG_REL_ UWB_FRNK SG_ 214 C_UWB_IC_Download_Data 0;
BA_REL_ "GenSigTimeoutTime" BU_SG_REL_ UWB_INT SG_ 214 C_UWB_IC_Download_Data 0;
BA_REL_ "GenSigTimeoutTime" BU_SG_REL_ UWB_RL SG_ 214 C_UWB_IC_Download_Data 0;
BA_REL_ "GenSigTimeoutTime" BU_SG_REL_ UWB_RR SG_ 214 C_UWB_IC_Download_Data 0;
BA_REL_ "GenSigTimeoutTime" BU_SG_REL_ UWB_TRNK SG_ 214 C_UWB_IC_Download_Data 0;
BA_REL_ "GenSigTimeoutTime" BU_SG_REL_ BDC SG_ 224 C_UWB_INT_Decrypt_FB 0;
BA_REL_ "GenSigTimeoutTime" BU_SG_REL_ UWB_BLE SG_ 224 C_UWB_INT_Decrypt_FB 0;
BA_REL_ "GenSigTimeoutTime" BU_SG_REL_ BDC SG_ 225 C_UWB_INT_To_BDCFOBRSDResult 0;
BA_REL_ "GenSigTimeoutTime" BU_SG_REL_ UWB_BLE SG_ 226 C_UWB_INT_MCU_Bootloader 0;
BA_REL_ "GenSigTimeoutTime" BU_SG_REL_ UWB_BLE SG_ 226 C_UWB_INT_MCU_Flash_Erase 0;
BA_REL_ "GenSigTimeoutTime" BU_SG_REL_ UWB_BLE SG_ 226 C_UWB_INT_MCU_CRC32 0;
BA_REL_ "GenSigTimeoutTime" BU_SG_REL_ UWB_BLE SG_ 227 C_UWB_INT_IC_Bootloader 0;
BA_REL_ "GenSigTimeoutTime" BU_SG_REL_ UWB_BLE SG_ 227 C_UWB_INT_IC_Flash_Erase 0;
BA_REL_ "GenSigTimeoutTime" BU_SG_REL_ UWB_BLE SG_ 227 C_UWB_INT_IC_CRC32 0;
BA_REL_ "GenSigTimeoutTime" BU_SG_REL_ UWB_BLE SG_ 235 C_UWB_INT_To_MasterEncData2 0;
BA_REL_ "GenSigTimeoutTime" BU_SG_REL_ DHL SG_ 256 C_BDC_Status 0;
BA_REL_ "GenSigTimeoutTime" BU_SG_REL_ DHR SG_ 256 C_BDC_Status 0;
BA_REL_ "GenSigTimeoutTime" BU_SG_REL_ UWB_BLE SG_ 256 C_BDC_Status 0;
BA_REL_ "GenSigTimeoutTime" BU_SG_REL_ UWB_FL SG_ 256 C_BDC_Status 0;
BA_REL_ "GenSigTimeoutTime" BU_SG_REL_ UWB_FR SG_ 256 C_BDC_Status 0;
BA_REL_ "GenSigTimeoutTime" BU_SG_REL_ UWB_FRNK SG_ 256 C_BDC_Status 0;
BA_REL_ "GenSigTimeoutTime" BU_SG_REL_ UWB_INT SG_ 256 C_BDC_Status 0;
BA_REL_ "GenSigTimeoutTime" BU_SG_REL_ UWB_RL SG_ 256 C_BDC_Status 0;
BA_REL_ "GenSigTimeoutTime" BU_SG_REL_ UWB_RR SG_ 256 C_BDC_Status 0;
BA_REL_ "GenSigTimeoutTime" BU_SG_REL_ UWB_TRNK SG_ 256 C_BDC_Status 0;
BA_REL_ "GenSigTimeoutTime" BU_SG_REL_ WPC SG_ 256 C_BDC_Status 0;
BA_REL_ "GenSigTimeoutTime" BU_SG_REL_ DHL SG_ 256 C_DigitalKey_Enable 0;
BA_REL_ "GenSigTimeoutTime" BU_SG_REL_ DHR SG_ 256 C_DigitalKey_Enable 0;
BA_REL_ "GenSigTimeoutTime" BU_SG_REL_ UWB_BLE SG_ 256 C_DigitalKey_Enable 0;
BA_REL_ "GenSigTimeoutTime" BU_SG_REL_ UWB_FL SG_ 256 C_DigitalKey_Enable 0;
BA_REL_ "GenSigTimeoutTime" BU_SG_REL_ UWB_FR SG_ 256 C_DigitalKey_Enable 0;
BA_REL_ "GenSigTimeoutTime" BU_SG_REL_ UWB_FRNK SG_ 256 C_DigitalKey_Enable 0;
BA_REL_ "GenSigTimeoutTime" BU_SG_REL_ UWB_INT SG_ 256 C_DigitalKey_Enable 0;
BA_REL_ "GenSigTimeoutTime" BU_SG_REL_ UWB_RL SG_ 256 C_DigitalKey_Enable 0;
BA_REL_ "GenSigTimeoutTime" BU_SG_REL_ UWB_RR SG_ 256 C_DigitalKey_Enable 0;
BA_REL_ "GenSigTimeoutTime" BU_SG_REL_ UWB_TRNK SG_ 256 C_DigitalKey_Enable 0;
BA_REL_ "GenSigTimeoutTime" BU_SG_REL_ Devtool SG_ 256 C_DeviceOnWPC 0;
BA_REL_ "GenSigTimeoutTime" BU_SG_REL_ WPC SG_ 256 C_DeviceOnWPC 0;
BA_REL_ "GenSigTimeoutTime" BU_SG_REL_ DHL SG_ 256 C_FobFoundWlcmArea 0;
BA_REL_ "GenSigTimeoutTime" BU_SG_REL_ DHR SG_ 256 C_FobFoundWlcmArea 0;
BA_REL_ "GenSigTimeoutTime" BU_SG_REL_ DHL SG_ 256 C_PuddleLpOnReq 0;
BA_REL_ "GenSigTimeoutTime" BU_SG_REL_ DHR SG_ 256 C_PuddleLpOnReq 0;
BA_REL_ "GenSigTimeoutTime" BU_SG_REL_ DHL SG_ 256 C_OwnerKey_Reg_Status 0;
BA_REL_ "GenSigTimeoutTime" BU_SG_REL_ DHR SG_ 256 C_OwnerKey_Reg_Status 0;
BA_REL_ "GenSigTimeoutTime" BU_SG_REL_ UWB_BLE SG_ 256 C_OwnerKey_Reg_Status 0;
BA_REL_ "GenSigTimeoutTime" BU_SG_REL_ UWB_FL SG_ 256 C_OwnerKey_Reg_Status 0;
BA_REL_ "GenSigTimeoutTime" BU_SG_REL_ UWB_FR SG_ 256 C_OwnerKey_Reg_Status 0;
BA_REL_ "GenSigTimeoutTime" BU_SG_REL_ UWB_FRNK SG_ 256 C_OwnerKey_Reg_Status 0;
BA_REL_ "GenSigTimeoutTime" BU_SG_REL_ UWB_INT SG_ 256 C_OwnerKey_Reg_Status 0;
BA_REL_ "GenSigTimeoutTime" BU_SG_REL_ UWB_RL SG_ 256 C_OwnerKey_Reg_Status 0;
BA_REL_ "GenSigTimeoutTime" BU_SG_REL_ UWB_RR SG_ 256 C_OwnerKey_Reg_Status 0;
BA_REL_ "GenSigTimeoutTime" BU_SG_REL_ UWB_TRNK SG_ 256 C_OwnerKey_Reg_Status 0;
BA_REL_ "GenSigTimeoutTime" BU_SG_REL_ DHL SG_ 256 C_SharedKey_Reg_Status 0;
BA_REL_ "GenSigTimeoutTime" BU_SG_REL_ DHR SG_ 256 C_SharedKey_Reg_Status 0;
BA_REL_ "GenSigTimeoutTime" BU_SG_REL_ UWB_BLE SG_ 256 C_SharedKey_Reg_Status 0;
BA_REL_ "GenSigTimeoutTime" BU_SG_REL_ UWB_FL SG_ 256 C_SharedKey_Reg_Status 0;
BA_REL_ "GenSigTimeoutTime" BU_SG_REL_ UWB_FR SG_ 256 C_SharedKey_Reg_Status 0;
BA_REL_ "GenSigTimeoutTime" BU_SG_REL_ UWB_FRNK SG_ 256 C_SharedKey_Reg_Status 0;
BA_REL_ "GenSigTimeoutTime" BU_SG_REL_ UWB_INT SG_ 256 C_SharedKey_Reg_Status 0;
BA_REL_ "GenSigTimeoutTime" BU_SG_REL_ UWB_RL SG_ 256 C_SharedKey_Reg_Status 0;
BA_REL_ "GenSigTimeoutTime" BU_SG_REL_ UWB_RR SG_ 256 C_SharedKey_Reg_Status 0;
BA_REL_ "GenSigTimeoutTime" BU_SG_REL_ UWB_TRNK SG_ 256 C_SharedKey_Reg_Status 0;
BA_REL_ "GenSigTimeoutTime" BU_SG_REL_ DHL SG_ 256 C_CardKey_Enable 0;
BA_REL_ "GenSigTimeoutTime" BU_SG_REL_ DHR SG_ 256 C_CardKey_Enable 0;
BA_REL_ "GenSigTimeoutTime" BU_SG_REL_ ROA SG_ 257 Radar_ROA_SnsrRunReq 0;
BA_REL_ "GenSigTimeoutTime" BU_SG_REL_ ROA SG_ 257 Radar_ROA_DiaReq 0;
BA_REL_ "GenSigTimeoutTime" BU_SG_REL_ ROA SG_ 257 Radar_ROA_EngSta 0;
BA_REL_ "GenSigTimeoutTime" BU_SG_REL_ BDC SG_ 272 C_WPC_Status 0;
BA_REL_ "GenSigTimeoutTime" BU_SG_REL_ Devtool SG_ 272 C_WPC_Status 0;
BA_REL_ "GenSigTimeoutTime" BU_SG_REL_ BDC SG_ 272 C_WPCNFC_Option 0;
BA_REL_ "GenSigTimeoutTime" BU_SG_REL_ BDC SG_ 277 C_BTAddIRK_Update 0;
BA_REL_ "GenSigTimeoutTime" BU_SG_REL_ BDC SG_ 277 C_OP_ADV_State 0;
BA_REL_ "GenSigTimeoutTime" BU_SG_REL_ BDC SG_ 277 C_Passive_ADV_State 0;
BA_REL_ "GenSigTimeoutTime" BU_SG_REL_ BDC SG_ 277 C_NewDeviceConnetStatus 0;
BA_REL_ "GenSigTimeoutTime" BU_SG_REL_ BDC SG_ 277 C_BLE_Option 0;
BA_REL_ "GenSigTimeoutTime" BU_SG_REL_ BDC SG_ 277 C_ConnectedDeviceInfo 0;
BA_REL_ "GenSigTimeoutTime" BU_SG_REL_ BDC SG_ 288 C_DHL_Status 0;
BA_REL_ "GenSigTimeoutTime" BU_SG_REL_ BDC SG_ 288 C_DHLToggleDetected 0;
BA_REL_ "GenSigTimeoutTime" BU_SG_REL_ UWB_BLE SG_ 288 C_DHLToggleDetected 0;
BA_REL_ "GenSigTimeoutTime" BU_SG_REL_ BDC SG_ 288 C_DHLUnlockDetected 0;
BA_REL_ "GenSigTimeoutTime" BU_SG_REL_ UWB_BLE SG_ 288 C_DHLUnlockDetected 0;
BA_REL_ "GenSigTimeoutTime" BU_SG_REL_ BDC SG_ 288 C_DHLLockDetected 0;
BA_REL_ "GenSigTimeoutTime" BU_SG_REL_ UWB_BLE SG_ 288 C_DHLLockDetected 0;
BA_REL_ "GenSigTimeoutTime" BU_SG_REL_ BDC SG_ 288 C_DHLPhnDetected 0;
BA_REL_ "GenSigTimeoutTime" BU_SG_REL_ BDC SG_ 288 C_DHLDiagnostics 0;
BA_REL_ "GenSigTimeoutTime" BU_SG_REL_ BDC SG_ 288 C_DHL_RainState 0;
BA_REL_ "GenSigTimeoutTime" BU_SG_REL_ BDC SG_ 304 C_DHR_Status 0;
BA_REL_ "GenSigTimeoutTime" BU_SG_REL_ BDC SG_ 304 C_DHRToggleDetected 0;
BA_REL_ "GenSigTimeoutTime" BU_SG_REL_ UWB_BLE SG_ 304 C_DHRToggleDetected 0;
BA_REL_ "GenSigTimeoutTime" BU_SG_REL_ BDC SG_ 304 C_DHRUnlockDetected 0;
BA_REL_ "GenSigTimeoutTime" BU_SG_REL_ UWB_BLE SG_ 304 C_DHRUnlockDetected 0;
BA_REL_ "GenSigTimeoutTime" BU_SG_REL_ BDC SG_ 304 C_DHRLockDetected 0;
BA_REL_ "GenSigTimeoutTime" BU_SG_REL_ UWB_BLE SG_ 304 C_DHRLockDetected 0;
BA_REL_ "GenSigTimeoutTime" BU_SG_REL_ BDC SG_ 304 C_DHRPhnDetected 0;
BA_REL_ "GenSigTimeoutTime" BU_SG_REL_ BDC SG_ 304 C_DHRDiagnostics 0;
BA_REL_ "GenSigTimeoutTime" BU_SG_REL_ BDC SG_ 304 C_DHR_RainState 0;
BA_REL_ "GenSigTimeoutTime" BU_SG_REL_ BDC SG_ 320 C_BLE_RSSI1 0;
BA_REL_ "GenSigTimeoutTime" BU_SG_REL_ BDC SG_ 320 C_BLE_RSSI2 0;
BA_REL_ "GenSigTimeoutTime" BU_SG_REL_ BDC SG_ 320 C_BLE_RSSI3 0;
BA_REL_ "GenSigTimeoutTime" BU_SG_REL_ BDC SG_ 320 C_BLE_RSSI4 0;
BA_REL_ "GenSigTimeoutTime" BU_SG_REL_ BDC SG_ 353 C_UWB_FRNK_Decrypt_FB 0;
BA_REL_ "GenSigTimeoutTime" BU_SG_REL_ UWB_BLE SG_ 353 C_UWB_FRNK_Decrypt_FB 0;
BA_REL_ "GenSigTimeoutTime" BU_SG_REL_ UWB_BLE SG_ 354 C_UWB_FRNK_To_MasterEncData1 0;
BA_REL_ "GenSigTimeoutTime" BU_SG_REL_ UWB_BLE SG_ 355 C_UWB_FRNK_To_MasterEncData2 0;
BA_REL_ "GenSigTimeoutTime" BU_SG_REL_ BDC SG_ 356 C_UWB_FRNK_To_BDCFOBRSDResult 0;
BA_REL_ "GenSigTimeoutTime" BU_SG_REL_ BDC SG_ 357 Radar_ROA_SW_Ver_Major 5000;
BA_REL_ "GenSigTimeoutTime" BU_SG_REL_ BDC SG_ 357 Radar_ROA_SW_Ver_Minor1 5000;
BA_REL_ "GenSigTimeoutTime" BU_SG_REL_ BDC SG_ 357 Radar_ROA_SW_Ver_Minor2 5000;
BA_REL_ "GenSigTimeoutTime" BU_SG_REL_ BDC SG_ 357 Radar_ROA_ClassStat 5000;
BA_REL_ "GenSigTimeoutTime" BU_SG_REL_ BDC SG_ 357 Radar_ROA_SnSrStat 5000;
BA_REL_ "GenSigTimeoutTime" BU_SG_REL_ BDC SG_ 357 Radar_ROA_DetInfo 5000;
BA_REL_ "GenSigTimeoutTime" BU_SG_REL_ BDC SG_ 357 Radar_ROA_SnSrBlckgeErrStat 5000;
BA_REL_ "GenSigTimeoutTime" BU_SG_REL_ BDC SG_ 357 Radar_ROA_SnSrErrStat 5000;
BA_REL_ "GenSigTimeoutTime" BU_SG_REL_ BDC SG_ 357 Radar_ROA_RegionOpt 5000;
BA_REL_ "GenSigTimeoutTime" BU_SG_REL_ UWB_BLE SG_ 358 C_UWB_FRNK_IC_Bootloader 0;
BA_REL_ "GenSigTimeoutTime" BU_SG_REL_ UWB_BLE SG_ 358 C_UWB_FRNK_IC_Flash_Erase 0;
BA_REL_ "GenSigTimeoutTime" BU_SG_REL_ UWB_BLE SG_ 358 C_UWB_FRNK_IC_CRC32 0;
BA_REL_ "GenSigTimeoutTime" BU_SG_REL_ BDC SG_ 362 C_UWB_FRUNK_Status1 0;
BA_REL_ "GenSigTimeoutTime" BU_SG_REL_ UWB_BLE SG_ 362 C_UWB_FRUNK_Status1 0;
BA_REL_ "GenSigTimeoutTime" BU_SG_REL_ BDC SG_ 362 C_UWB_FRUNK_Status2 0;
BA_REL_ "GenSigTimeoutTime" BU_SG_REL_ UWB_BLE SG_ 362 C_UWB_FRUNK_Status2 0;
BA_REL_ "GenSigTimeoutTime" BU_SG_REL_ BDC SG_ 362 C_UWB_FRUNK_Status3 0;
BA_REL_ "GenSigTimeoutTime" BU_SG_REL_ UWB_BLE SG_ 362 C_UWB_FRUNK_Status3 0;
BA_REL_ "GenSigTimeoutTime" BU_SG_REL_ BDC SG_ 362 C_UWB_FRUNK_Status4 0;
BA_REL_ "GenSigTimeoutTime" BU_SG_REL_ UWB_BLE SG_ 362 C_UWB_FRUNK_Status4 0;
BA_REL_ "GenSigTimeoutTime" BU_SG_REL_ BDC SG_ 362 C_UWB_FRUNK_Status5 0;
BA_REL_ "GenSigTimeoutTime" BU_SG_REL_ UWB_BLE SG_ 362 C_UWB_FRUNK_Status5 0;
BA_REL_ "GenSigTimeoutTime" BU_SG_REL_ BDC SG_ 362 C_UWB_FRUNK_Status6 0;
BA_REL_ "GenSigTimeoutTime" BU_SG_REL_ UWB_BLE SG_ 362 C_UWB_FRUNK_Status6 0;
BA_REL_ "GenSigTimeoutTime" BU_SG_REL_ BDC SG_ 362 C_UWB_FRUNK_Status7 0;
BA_REL_ "GenSigTimeoutTime" BU_SG_REL_ UWB_BLE SG_ 362 C_UWB_FRUNK_Status7 0;
BA_REL_ "GenSigTimeoutTime" BU_SG_REL_ BDC SG_ 362 C_UWB_FRUNK_Status8 0;
BA_REL_ "GenSigTimeoutTime" BU_SG_REL_ UWB_BLE SG_ 362 C_UWB_FRUNK_Status8 0;
BA_REL_ "GenSigTimeoutTime" BU_SG_REL_ UWB_BLE SG_ 362 C_UWB_FRNK_DTC 0;
BA_REL_ "GenSigTimeoutTime" BU_SG_REL_ BDC SG_ 362 C_UWB_FRUNK_Option 0;
BA_REL_ "GenSigTimeoutTime" BU_SG_REL_ UWB_BLE SG_ 362 C_UWB_FRUNK_Option 0;
BA_REL_ "GenSigTimeoutTime" BU_SG_REL_ UWB_BLE SG_ 363 C_UWB_FRNK_HW_Ver_Major 0;
BA_REL_ "GenSigTimeoutTime" BU_SG_REL_ UWB_BLE SG_ 363 C_UWB_FRNK_HW_Ver_Minor 0;
BA_REL_ "GenSigTimeoutTime" BU_SG_REL_ UWB_BLE SG_ 363 C_UWB_FRNK_SW_MCU_Ver_Major 0;
BA_REL_ "GenSigTimeoutTime" BU_SG_REL_ UWB_BLE SG_ 363 C_UWB_FRNK_SW_MCU_Ver_Minor 0;
BA_REL_ "GenSigTimeoutTime" BU_SG_REL_ UWB_BLE SG_ 363 C_UWB_FRNK_SW_IC_Ver_Major 0;
BA_REL_ "GenSigTimeoutTime" BU_SG_REL_ UWB_BLE SG_ 363 C_UWB_FRNK_SW_IC_Ver_Minor 0;
BA_REL_ "GenSigTimeoutTime" BU_SG_REL_ UWB_BLE SG_ 367 C_UWB_FRNK_MCU_Bootloader 0;
BA_REL_ "GenSigTimeoutTime" BU_SG_REL_ UWB_BLE SG_ 367 C_UWB_FRNK_MCU_Flash_Erase 0;
BA_REL_ "GenSigTimeoutTime" BU_SG_REL_ UWB_BLE SG_ 367 C_UWB_FRNK_MCU_CRC32 0;
BA_REL_ "GenSigTimeoutTime" BU_SG_REL_ BDC SG_ 368 C_UWB_FR_Status1 0;
BA_REL_ "GenSigTimeoutTime" BU_SG_REL_ UWB_BLE SG_ 368 C_UWB_FR_Status1 0;
BA_REL_ "GenSigTimeoutTime" BU_SG_REL_ BDC SG_ 368 C_UWB_FR_Status2 0;
BA_REL_ "GenSigTimeoutTime" BU_SG_REL_ UWB_BLE SG_ 368 C_UWB_FR_Status2 0;
BA_REL_ "GenSigTimeoutTime" BU_SG_REL_ BDC SG_ 368 C_UWB_FR_Status3 0;
BA_REL_ "GenSigTimeoutTime" BU_SG_REL_ UWB_BLE SG_ 368 C_UWB_FR_Status3 0;
BA_REL_ "GenSigTimeoutTime" BU_SG_REL_ BDC SG_ 368 C_UWB_FR_Status4 0;
BA_REL_ "GenSigTimeoutTime" BU_SG_REL_ UWB_BLE SG_ 368 C_UWB_FR_Status4 0;
BA_REL_ "GenSigTimeoutTime" BU_SG_REL_ BDC SG_ 368 C_UWB_FR_Status5 0;
BA_REL_ "GenSigTimeoutTime" BU_SG_REL_ UWB_BLE SG_ 368 C_UWB_FR_Status5 0;
BA_REL_ "GenSigTimeoutTime" BU_SG_REL_ BDC SG_ 368 C_UWB_FR_Status6 0;
BA_REL_ "GenSigTimeoutTime" BU_SG_REL_ UWB_BLE SG_ 368 C_UWB_FR_Status6 0;
BA_REL_ "GenSigTimeoutTime" BU_SG_REL_ BDC SG_ 368 C_UWB_FR_Status7 0;
BA_REL_ "GenSigTimeoutTime" BU_SG_REL_ UWB_BLE SG_ 368 C_UWB_FR_Status7 0;
BA_REL_ "GenSigTimeoutTime" BU_SG_REL_ BDC SG_ 368 C_UWB_FR_Status8 0;
BA_REL_ "GenSigTimeoutTime" BU_SG_REL_ UWB_BLE SG_ 368 C_UWB_FR_Status8 0;
BA_REL_ "GenSigTimeoutTime" BU_SG_REL_ UWB_BLE SG_ 368 C_UWB_FR_DTC 0;
BA_REL_ "GenSigTimeoutTime" BU_SG_REL_ BDC SG_ 368 C_UWB_FR_Option 0;
BA_REL_ "GenSigTimeoutTime" BU_SG_REL_ UWB_BLE SG_ 368 C_UWB_FR_Option 0;
BA_REL_ "GenSigTimeoutTime" BU_SG_REL_ UWB_BLE SG_ 369 C_UWB_FR_HW_Ver_Major 0;
BA_REL_ "GenSigTimeoutTime" BU_SG_REL_ UWB_BLE SG_ 369 C_UWB_FR_HW_Ver_Minor 0;
BA_REL_ "GenSigTimeoutTime" BU_SG_REL_ UWB_BLE SG_ 369 C_UWB_FR_SW_MCU_Ver_Major 0;
BA_REL_ "GenSigTimeoutTime" BU_SG_REL_ UWB_BLE SG_ 369 C_UWB_FR_SW_MCU_Ver_Minor 0;
BA_REL_ "GenSigTimeoutTime" BU_SG_REL_ UWB_BLE SG_ 369 C_UWB_FR_SW_IC_Ver_Major 0;
BA_REL_ "GenSigTimeoutTime" BU_SG_REL_ UWB_BLE SG_ 369 C_UWB_FR_SW_IC_Ver_Minor 0;
BA_REL_ "GenSigTimeoutTime" BU_SG_REL_ UWB_BLE SG_ 370 C_UWB_FL_To_MaseterEncData1 0;
BA_REL_ "GenSigTimeoutTime" BU_SG_REL_ UWB_BLE SG_ 371 C_UWB_FL_To_MasterEncData2 0;
BA_REL_ "GenSigTimeoutTime" BU_SG_REL_ BDC SG_ 372 C_UWB_FL_To_BDCFOBRSDResult 0;
BA_REL_ "GenSigTimeoutTime" BU_SG_REL_ UWB_BLE SG_ 373 C_UWB_FL_MCU_Bootloader 0;
BA_REL_ "GenSigTimeoutTime" BU_SG_REL_ UWB_BLE SG_ 373 C_UWB_FL_MCU_Flash_Erase 0;
BA_REL_ "GenSigTimeoutTime" BU_SG_REL_ UWB_BLE SG_ 373 C_UWB_FL_MCU_CRC32 0;
BA_REL_ "GenSigTimeoutTime" BU_SG_REL_ UWB_BLE SG_ 374 C_UWB_FL_IC_Bootloader 0;
BA_REL_ "GenSigTimeoutTime" BU_SG_REL_ UWB_BLE SG_ 374 C_UWB_FL_IC_Flash_Erase 0;
BA_REL_ "GenSigTimeoutTime" BU_SG_REL_ UWB_BLE SG_ 374 C_UWB_FL_IC_CRC32 0;
BA_REL_ "GenSigTimeoutTime" BU_SG_REL_ BDC SG_ 375 C_UWB_FL_Decrypt_FB 0;
BA_REL_ "GenSigTimeoutTime" BU_SG_REL_ UWB_BLE SG_ 375 C_UWB_FL_Decrypt_FB 0;
BA_REL_ "GenSigTimeoutTime" BU_SG_REL_ BDC SG_ 376 C_UWB_FL_Status1 0;
BA_REL_ "GenSigTimeoutTime" BU_SG_REL_ UWB_BLE SG_ 376 C_UWB_FL_Status1 0;
BA_REL_ "GenSigTimeoutTime" BU_SG_REL_ BDC SG_ 376 C_UWB_FL_Status2 0;
BA_REL_ "GenSigTimeoutTime" BU_SG_REL_ UWB_BLE SG_ 376 C_UWB_FL_Status2 0;
BA_REL_ "GenSigTimeoutTime" BU_SG_REL_ BDC SG_ 376 C_UWB_FL_Status3 0;
BA_REL_ "GenSigTimeoutTime" BU_SG_REL_ UWB_BLE SG_ 376 C_UWB_FL_Status3 0;
BA_REL_ "GenSigTimeoutTime" BU_SG_REL_ BDC SG_ 376 C_UWB_FL_Status4 0;
BA_REL_ "GenSigTimeoutTime" BU_SG_REL_ UWB_BLE SG_ 376 C_UWB_FL_Status4 0;
BA_REL_ "GenSigTimeoutTime" BU_SG_REL_ BDC SG_ 376 C_UWB_FL_Status5 0;
BA_REL_ "GenSigTimeoutTime" BU_SG_REL_ UWB_BLE SG_ 376 C_UWB_FL_Status5 0;
BA_REL_ "GenSigTimeoutTime" BU_SG_REL_ BDC SG_ 376 C_UWB_FL_Status6 0;
BA_REL_ "GenSigTimeoutTime" BU_SG_REL_ UWB_BLE SG_ 376 C_UWB_FL_Status6 0;
BA_REL_ "GenSigTimeoutTime" BU_SG_REL_ BDC SG_ 376 C_UWB_FL_Status7 0;
BA_REL_ "GenSigTimeoutTime" BU_SG_REL_ UWB_BLE SG_ 376 C_UWB_FL_Status7 0;
BA_REL_ "GenSigTimeoutTime" BU_SG_REL_ BDC SG_ 376 C_UWB_FL_Status8 0;
BA_REL_ "GenSigTimeoutTime" BU_SG_REL_ UWB_BLE SG_ 376 C_UWB_FL_Status8 0;
BA_REL_ "GenSigTimeoutTime" BU_SG_REL_ UWB_BLE SG_ 376 C_UWB_FL_DTC 0;
BA_REL_ "GenSigTimeoutTime" BU_SG_REL_ BDC SG_ 376 C_UWB_FL_Option 0;
BA_REL_ "GenSigTimeoutTime" BU_SG_REL_ UWB_BLE SG_ 376 C_UWB_FL_Option 0;
BA_REL_ "GenSigTimeoutTime" BU_SG_REL_ UWB_BLE SG_ 377 C_UWB_FL_HW_Ver_Major 0;
BA_REL_ "GenSigTimeoutTime" BU_SG_REL_ UWB_BLE SG_ 377 C_UWB_FL_HW_Ver_Minor 0;
BA_REL_ "GenSigTimeoutTime" BU_SG_REL_ UWB_BLE SG_ 377 C_UWB_FL_SW_MCU_Ver_Major 0;
BA_REL_ "GenSigTimeoutTime" BU_SG_REL_ UWB_BLE SG_ 377 C_UWB_FL_SW_MCU_Ver_Minor 0;
BA_REL_ "GenSigTimeoutTime" BU_SG_REL_ UWB_BLE SG_ 377 C_UWB_FL_SW_IC_Ver_Major 0;
BA_REL_ "GenSigTimeoutTime" BU_SG_REL_ UWB_BLE SG_ 377 C_UWB_FL_SW_IC_Ver_Minor 0;
BA_REL_ "GenSigTimeoutTime" BU_SG_REL_ Devtool SG_ 378 C_UWB_BLE_MasterEncData1 0;
BA_REL_ "GenSigTimeoutTime" BU_SG_REL_ Devtool SG_ 379 C_UWB_BLE_MasterEncData2 0;
BA_REL_ "GenSigTimeoutTime" BU_SG_REL_ BDC SG_ 384 C_UWB_INT_Status1 0;
BA_REL_ "GenSigTimeoutTime" BU_SG_REL_ UWB_BLE SG_ 384 C_UWB_INT_Status1 0;
BA_REL_ "GenSigTimeoutTime" BU_SG_REL_ BDC SG_ 384 C_UWB_INT_Status2 0;
BA_REL_ "GenSigTimeoutTime" BU_SG_REL_ UWB_BLE SG_ 384 C_UWB_INT_Status2 0;
BA_REL_ "GenSigTimeoutTime" BU_SG_REL_ BDC SG_ 384 C_UWB_INT_Status3 0;
BA_REL_ "GenSigTimeoutTime" BU_SG_REL_ UWB_BLE SG_ 384 C_UWB_INT_Status3 0;
BA_REL_ "GenSigTimeoutTime" BU_SG_REL_ BDC SG_ 384 C_UWB_INT_Status4 0;
BA_REL_ "GenSigTimeoutTime" BU_SG_REL_ UWB_BLE SG_ 384 C_UWB_INT_Status4 0;
BA_REL_ "GenSigTimeoutTime" BU_SG_REL_ BDC SG_ 384 C_UWB_INT_Status5 0;
BA_REL_ "GenSigTimeoutTime" BU_SG_REL_ UWB_BLE SG_ 384 C_UWB_INT_Status5 0;
BA_REL_ "GenSigTimeoutTime" BU_SG_REL_ BDC SG_ 384 C_UWB_INT_Status6 0;
BA_REL_ "GenSigTimeoutTime" BU_SG_REL_ UWB_BLE SG_ 384 C_UWB_INT_Status6 0;
BA_REL_ "GenSigTimeoutTime" BU_SG_REL_ BDC SG_ 384 C_UWB_INT_Status7 0;
BA_REL_ "GenSigTimeoutTime" BU_SG_REL_ UWB_BLE SG_ 384 C_UWB_INT_Status7 0;
BA_REL_ "GenSigTimeoutTime" BU_SG_REL_ BDC SG_ 384 C_UWB_INT_Status8 0;
BA_REL_ "GenSigTimeoutTime" BU_SG_REL_ UWB_BLE SG_ 384 C_UWB_INT_Status8 0;
BA_REL_ "GenSigTimeoutTime" BU_SG_REL_ UWB_BLE SG_ 384 C_UWB_INT_DTC 0;
BA_REL_ "GenSigTimeoutTime" BU_SG_REL_ BDC SG_ 384 C_UWB_INT_Option 0;
BA_REL_ "GenSigTimeoutTime" BU_SG_REL_ UWB_BLE SG_ 384 C_UWB_INT_Option 0;
BA_REL_ "GenSigTimeoutTime" BU_SG_REL_ UWB_BLE SG_ 385 C_UWB_INT_HW_Ver_Major 0;
BA_REL_ "GenSigTimeoutTime" BU_SG_REL_ UWB_BLE SG_ 385 C_UWB_INT_HW_Ver_Minor 0;
BA_REL_ "GenSigTimeoutTime" BU_SG_REL_ UWB_BLE SG_ 385 C_UWB_INT_SW_MCU_Ver_Major 0;
BA_REL_ "GenSigTimeoutTime" BU_SG_REL_ UWB_BLE SG_ 385 C_UWB_INT_SW_MCU_Ver_Minor 0;
BA_REL_ "GenSigTimeoutTime" BU_SG_REL_ UWB_BLE SG_ 385 C_UWB_INT_SW_IC_Ver_Major 0;
BA_REL_ "GenSigTimeoutTime" BU_SG_REL_ UWB_BLE SG_ 385 C_UWB_INT_SW_IC_Ver_Minor 0;
BA_REL_ "GenSigTimeoutTime" BU_SG_REL_ UWB_BLE SG_ 386 C_UWB_FR_To_MasterEncData1 0;
BA_REL_ "GenSigTimeoutTime" BU_SG_REL_ BDC SG_ 387 C_UWB_FR_Decrypt_FB 0;
BA_REL_ "GenSigTimeoutTime" BU_SG_REL_ UWB_BLE SG_ 387 C_UWB_FR_Decrypt_FB 0;
BA_REL_ "GenSigTimeoutTime" BU_SG_REL_ BDC SG_ 388 C_UWB_FR_To_BDCFOBRSDResult 0;
BA_REL_ "GenSigTimeoutTime" BU_SG_REL_ UWB_BLE SG_ 389 C_UWB_FR_MCU_Bootloader 0;
BA_REL_ "GenSigTimeoutTime" BU_SG_REL_ UWB_BLE SG_ 389 C_UWB_FR_MCU_Flash_Erase 0;
BA_REL_ "GenSigTimeoutTime" BU_SG_REL_ UWB_BLE SG_ 389 C_UWB_FR_MCU_CRC32 0;
BA_REL_ "GenSigTimeoutTime" BU_SG_REL_ UWB_BLE SG_ 390 C_UWB_FR_IC_Bootloader 0;
BA_REL_ "GenSigTimeoutTime" BU_SG_REL_ UWB_BLE SG_ 390 C_UWB_FR_IC_Flash_Erase 0;
BA_REL_ "GenSigTimeoutTime" BU_SG_REL_ UWB_BLE SG_ 390 C_UWB_FR_IC_CRC32 0;
BA_REL_ "GenSigTimeoutTime" BU_SG_REL_ UWB_BLE SG_ 391 C_UWB_FR_To_MasterEncData2 0;
VAL_ 16 C_WPC_NFCDetection 0 "Off" 1 "Detected" 2 "Not Detected" ;
VAL_ 16 C_WPC_NFCReset 0 "Default" 1 "Reset Complete" ;
VAL_ 17 C_WlightOnCmd 0 "None" 1 "Off" 2 "On" 3 "Invalid" ;
VAL_ 17 C_WPCNFCcmd 0 "None" 1 "NFC Searching On(HCE)" 2 "NFC Searching Off" 3 "NFC Searching On(Usim)" 4 "reserved" 5 "reserved" 6 "reserved" 7 "Invalid" ;
VAL_ 17 C_DRNFCcmd 0 "None" 1 "NFC Searching On" 2 "NFC Searching Off" 3 "WPC NFC Select Request" 4 "reserved" 5 "reserved" 6 "reserved" 7 "Invalid" ;
VAL_ 17 C_BDCWPCNFCCmd 0 "Default" 1 "WPC NFC Polling (Search)" 2 "WPC NFC Deselect (Stop)" 3 "Invalid" ;
VAL_ 17 C_BDCDHLNFCCmd 0 "Default" 1 "NFC Polling (Search)" 2 "NFC Deselect (Stop)" 3 "Invalid" ;
VAL_ 17 C_BDCDHRNFCCmd 0 "Default" 1 "NFC Polling (Search)" 2 "NFC Deselect (Stop)" 3 "Invalid" ;
VAL_ 17 C_DRV_DRHdlLedOnSta 0 "Default" 1 "On" 2 "Off" 3 "Error Indicator" ;
VAL_ 17 C_AST_DRHdlLedOnSta 0 "Default" 1 "On" 2 "Off" 3 "Error Indicator" ;
VAL_ 18 C_DK_IDSet 0 "Default" 1 "DK#1" 2 "DK#2" 3 "DK#3" 4 "DK#4" 5 "DK#5" 6 "DK#6" 7 "DK#7" 8 "DK#8" 9 "DK#9" 10 "DK#10" 11 "DK#11" 12 "DK#12" 13 "DK#13" 14 "DK#14" 15 "DK#15" 16 "DK#16" 18 "DK#NEW" 19 "0x13~0xFE:Reserved" 254 "0x13~0xFE:Reserved" 255 "Invalid" ;
VAL_ 18 C_DK_IDDel 0 "Default" 1 "DK#1" 2 "DK#2" 3 "DK#3" 4 "DK#4" 5 "DK#5" 6 "DK#6" 7 "DK#7" 8 "DK#8" 9 "DK#9" 10 "DK#10" 11 "DK#11" 12 "DK#12" 13 "DK#13" 14 "DK#14" 15 "DK#15" 16 "DK#16" 18 "DK#NEW" 19 "0x13~0xFE:Reserved" 254 "0x13~0xFE:Reserved" 255 "Invalid" ;
VAL_ 18 C_OwnerDeviceSearchingReq 0 "Default" 1 "Searching_Start" 2 "Stop" 3 "Invalid" ;
VAL_ 18 C_TimeSync_REQ 0 "Default" 1 "Request" 2 "Reserve" 3 "Invalid" ;
VAL_ 18 C_BDC_DecryptFB1 0 "Default" 1 "Positive" 2 "Negative" 3 "Invalid" ;
VAL_ 18 C_BDC_DecryptFB2 0 "Default" 1 "Positive" 2 "Negative" 3 "Invalid" ;
VAL_ 20 C_UWB_Ranging_CMD_ID 0 "Default" 1 "DK#1" 2 "DK#2" 3 "DK#3" 4 "DK#4" 5 "DK#5" 6 "DK#6" 7 "DK#7" 8 "DK#8" 9 "DK#9" 10 "DK#10" 11 "DK#11" 12 "DK#12" 13 "DK#13" 14 "DK#14" 15 "DK#15" 16 "DK#16" 18 "DK#NEW" 19 "0x13~0xFE:Reserved" 254 "0x13~0xFE:Reserved" 255 "Invalid" ;
VAL_ 21 C_Warn_DrvDrSwSta 0 "Close" 1 "Open" 2 "Not Used" 3 "Error Indicator" ;
VAL_ 21 C_Warn_AsstDrSwSta 0 "Close" 1 "Open" 2 "Not Used" 3 "Error Indicator" ;
VAL_ 21 C_Warn_RrLftDrSwSta 0 "Close" 1 "Open" 2 "Not Used" 3 "Error Indicator" ;
VAL_ 21 C_Warn_RrRtDrSwSta 0 "Close" 1 "Open" 2 "Not Used" 3 "Error Indicator" ;
VAL_ 21 C_Trunk_TrnkTlgtSwSta 0 "Close(Full Lock)" 1 "Open(Not Full Lock)" 2 "Not Used" 3 "Error Indicator" ;
VAL_ 21 C_SMK_TrmnlMngrSta 0 "Off" 1 "OFF_TO_START" 2 "WAIT_ESCL_UNLOCK_ACC" 3 "ACC" 4 "ACC_SEARCH" 5 "ACC_TO_START" 6 "IGN" 7 "IGN_SEARCH" 8 "WAIT_ESCL_UNLOCK_OFF_TO_START" 9 "WAIT_ESCL_UNLOCK_START" 10 "WAIT_IGN1_ACC" 11 "WAIT_IGN1_ACC_SEARCH" 12 "WAIT_IGN1_ACC_TO_START" 13 "WAIT_IGN1_UNLOCK_OFF_TO_START" 14 "WAIT_IGN1_UNLOCK_START" 15 "START" 16 "ENGINE_RUNNING" 17 "Reserved" 18 "Reserved" 19 "Reserved" 20 "Reserved" 21 "Reserved" 22 "Reserved" 23 "Reserved" 24 "Reserved" 25 "Reserved" 26 "Reserved" 27 "Reserved" 28 "Reserved" 29 "Reserved" 30 "Not Used" 31 "Error Indicator" ;
VAL_ 21 C_Window_DrvrSdWdwSta_BCM 0 "Window Close" 1 "Window Open" 2 "Not Used" 3 "Error Indicator" ;
VAL_ 21 C_Window_AsstSdWdwSta_BCM 0 "Window Close" 1 "Window Open" 2 "Not Used" 3 "Error Indicator" ;
VAL_ 21 C_Window_RrLftWdwSta_BCM 0 "Window Close" 1 "Window Open" 2 "Not Used" 3 "Error Indicator" ;
VAL_ 21 C_Window_RrRtWdwSta_BCM 0 "Window Close" 1 "Window Open" 2 "Not Used" 3 "Error Indicator" ;
VAL_ 21 C_BodyTypeSta 0 "Body Type 1" 1 "Body Type 2" 2 "Body Type 3" 3 "Body Type 4" 4 "Body Type 5" 5 "Body Type 6" 6 "Body Type 7" 7 "Body Type 8" ;
VAL_ 21 C_SunRoofOptionSta 0 "NotApplied (노말 루프)" 1 "Type1 (기본 선루프)" 2 "Type2" 3 "Type3" ;
VAL_ 22 C_SSB_StrtStpBtnSw1Sta 0 "Released" 1 "Pressed" 2 "Not Used" 3 "Error Indicator" ;
VAL_ 22 C_SSB_StrtStpBtnSw2Sta 0 "Released" 1 "Pressed" 2 "Not Used" 3 "Error Indicator" ;
VAL_ 22 C_DoorLock_AsstDrUnLkSta 0 "Lock" 1 "Unlock" 2 "Not Used" 3 "Error Indicator" ;
VAL_ 22 C_DoorLock_DrvDrUnLkSta 0 "Lock" 1 "Unlock" 2 "Not Used" 3 "Error Indicator" ;
VAL_ 22 C_DoorLock_RrLftDrUnLkSta 0 "Lock" 1 "Unlock" 2 "Not Used" 3 "Error Indicator" ;
VAL_ 22 C_DoorLock_RrRtDrUnLkSta 0 "Lock" 1 "Unlock" 2 "Not Used" 3 "Error Indicator" ;
VAL_ 22 C_DriveTypeOption 0 "Left Handle Drive Type" 1 "Right Handle Drive Type" 2 "RESERVED" 3 "Error Indicator" ;
VAL_ 22 C_RSPA_Opt 0 "RSPA not applied" 1 "RSPA applied" 2 "Not Used" 3 "Error Indicator" ;
VAL_ 32 C_DHLNFCDetected 0 "Off" 1 "Detected" ;
VAL_ 32 C_DHLWlightStatus 0 "Off" 1 "On" ;
VAL_ 32 C_DHL_NFCReset 0 "Default" 1 "Reset Complete" ;
VAL_ 48 C_DHRNFCDetected 0 "Off" 1 "Detected" ;
VAL_ 48 C_DHRWlightStatus 0 "Off" 1 "On" ;
VAL_ 48 C_DHR_NFCReset 0 "Default" 1 "Reset Complete" ;
VAL_ 96 C_BLENewDevicePairingResult 0 "Default" 1 "BLE_Pairing_Start" 2 "BLE_Pairing_Complete" 3 "BLE_Pairing_Fail" ;
VAL_ 96 C_BLE_Decrypt_FB 0 "Default" 1 "Positive" 2 "Negative" 3 "Reserved" 4 "Reserved" 5 "Reserved" 6 "Reserved" 7 "Reserved" 8 "Reserved" 9 "Reserved" 10 "Reserved" 11 "Reserved" 12 "Reserved" 13 "Reserved" 14 "Reserved" 15 "Reserved" ;
VAL_ 209 C_UWB_MASTER_Decrypt_FB 0 "Default" 1 "Positive" 2 "Negative" 3 "Reserved" 4 "Reserved" 5 "Reserved" 6 "Reserved" 7 "Reserved" 8 "Reserved" 9 "Reserved" 10 "Reserved" 11 "Reserved" 12 "Reserved" 13 "Reserved" 14 "Reserved" 15 "Reserved" ;
VAL_ 211 C_UWB_MCU_OTA_Cmd 0 "Default" 1 "DownLoad_Request" 2 "Erase_Memory" 3 "CRC32_Verify_Rqeust" 4 "Reserved" 5 "Reserved" 6 "Reserved" 7 "Reserved" 8 "Reserved" 9 "Reserved" 10 "Reserved" 11 "Reserved" 12 "Reserved" 13 "Reserved" 14 "Reserved" 15 "Invalid" ;
VAL_ 212 C_UWB_IC_OTA_Cmd 0 "Default" 1 "DownLoad_Request" 2 "Erase_Memory" 3 "CRC32_Verify_Rqeust" 4 "Reserved" 5 "Reserved" 6 "Reserved" 7 "Reserved" 8 "Reserved" 9 "Reserved" 10 "Reserved" 11 "Reserved" 12 "Reserved" 13 "Reserved" 14 "Reserved" 15 "Invalid" ;
VAL_ 224 C_UWB_INT_Decrypt_FB 0 "Default" 1 "Positive" 2 "Negative" 3 "Reserved" 4 "Reserved" 5 "Reserved" 6 "Reserved" 7 "Reserved" 8 "Reserved" 9 "Reserved" 10 "Reserved" 11 "Reserved" 12 "Reserved" 13 "Reserved" 14 "Reserved" 15 "Reserved" ;
VAL_ 226 C_UWB_INT_MCU_Bootloader 0 "Default" 1 "Success" 2 "Fail" 3 "0x3~0xFF:Invalid" 255 "0x3~0xFF:Invalid" ;
VAL_ 226 C_UWB_INT_MCU_Flash_Erase 0 "Default" 1 "Success" 2 "Fail" 3 "0x3~0xFF:Invalid" 255 "0x3~0xFF:Invalid" ;
VAL_ 226 C_UWB_INT_MCU_CRC32 0 "Default" 1 "Success" 2 "Fail" 3 "0x3~0xFF:Invalid" 255 "0x3~0xFF:Invalid" ;
VAL_ 227 C_UWB_INT_IC_Bootloader 0 "Default" 1 "Success" 2 "Fail" 3 "0x3~0xFF:Invalid" 255 "0x3~0xFF:Invalid" ;
VAL_ 227 C_UWB_INT_IC_Flash_Erase 0 "Default" 1 "Success" 2 "Fail" 3 "0x3~0xFF:Invalid" 255 "0x3~0xFF:Invalid" ;
VAL_ 227 C_UWB_INT_IC_CRC32 0 "Default" 1 "Success" 2 "Fail" 3 "0x3~0xFF:Invalid" 255 "0x3~0xFF:Invalid" ;
VAL_ 256 C_BDC_Status 0 "Idle" 1 "Process for WPC" 2 "Process for DHL" 3 "Process for DHR" 4 "Process for BLE_TRX" 5 "Process for DHRL" 6 "Process for DHRR" 7 "Process for UWB" ;
VAL_ 256 C_DigitalKey_Enable 0 "None" 1 "Disable" 2 "Enable" 3 "Invaild" ;
VAL_ 256 C_DeviceOnWPC 0 "Not key device" 1 "Phone key" 2 "Card key" 3 "Invaild" ;
VAL_ 256 C_FobFoundWlcmArea 0 "Default (Off)" 1 "Fob Found" 2 "Reserved" 3 "Invalid" ;
VAL_ 256 C_PuddleLpOnReq 0 "off" 1 "On" 2 "Not Used" 3 "Error Indicator" ;
VAL_ 256 C_OwnerKey_Reg_Status 0 "Default (Unregistered)" 1 "Registered" 2 "Reserve" 3 "Invalid" ;
VAL_ 256 C_SharedKey_Reg_Status 0 "Default (Unregistered)" 1 "Registered" 2 "Reserve" 3 "Invalid" ;
VAL_ 256 C_CardKey_Enable 0 "None" 1 "Disable" 2 "Enable" 3 "Invaild" ;
VAL_ 257 Radar_ROA_SnsrRunReq 0 "Default" 1 "Init" 2 "Start" 3 "Stop" 4 "Start Delay" 5 "Reserved" 6 "Reserved" 7 "Error indicator" ;
VAL_ 257 Radar_ROA_DiaReq 0 "Default" 1 "Diagnosis (system info)" 2 "Request of update (Refresh parameter)" 3 "Parameter download" 4 "Reserved" 5 "Reserved" 6 "Reserved" 7 "Error indicator" ;
VAL_ 257 Radar_ROA_EngSta 0 "Off" 1 "Engine Running" 2 "Reserved" 3 "Error Indicator" ;
VAL_ 272 C_WPC_Status 0 "Off" 1 "WPC Mode" 2 "NFC Scanning" 3 "NFC Communicating" 4 "Reserved" 5 "Reserved" 6 "Reserved" 7 "invalid" ;
VAL_ 272 C_WPCNFC_Option 0 "Default(NotApplied)" 1 "Applied" 2 "Reserved" 3 "invalid" ;
VAL_ 277 C_OP_ADV_State 0 "AdvertisingOff" 1 "AdvertisingOn" ;
VAL_ 277 C_Passive_ADV_State 0 "AdvertisingOff" 1 "AdvertisingOn" ;
VAL_ 277 C_NewDeviceConnetStatus 0 "Default" 1 "Connected" 2 "Disconnected" 3 "Invalid" ;
VAL_ 277 C_BLE_Option 0 "Default(NotApplied)" 1 "Applied" 2 "Reseved" 3 "invalid" ;
VAL_ 288 C_DHL_Status 0 "Idle" 1 "NFC_Comm" 2 "NFC_Comm Complete" 3 "Reserved" 4 "Reserved" 5 "Reserved" 6 "Reserved" 7 "invalid" ;
VAL_ 288 C_DHLToggleDetected 0 "Off" 1 "Touch" ;
VAL_ 288 C_DHLUnlockDetected 0 "Off" 1 "Unlock" ;
VAL_ 288 C_DHLLockDetected 0 "Off" 1 "Lock" ;
VAL_ 288 C_DHLPhnDetected 0 "Default" 1 "On" 2 "Off" 3 "Invalid" ;
VAL_ 288 C_DHLDiagnostics 0 "No Error" 1 "DHS Internal Error" 2 "NFC Antenna Error" 4 "Overheating NFC" 8 "Overheating Lighting" 16 "Undervoltage" 32 "Overvoltage" 33 "0x21~0xFF:Reserved" 255 "0x21~0xFF:Reserved" ;
VAL_ 288 C_DHL_RainState 0 "Off" 1 "Rain" ;
VAL_ 304 C_DHR_Status 0 "Idle" 1 "NFC_Comm" 2 "NFC_Comm Complete" 3 "Reserved" 4 "Reserved" 5 "Reserved" 6 "Reserved" 7 "invalid" ;
VAL_ 304 C_DHRToggleDetected 0 "Off" 1 "Touch" ;
VAL_ 304 C_DHRUnlockDetected 0 "Off" 1 "Unlock" ;
VAL_ 304 C_DHRLockDetected 0 "Off" 1 "Lock" ;
VAL_ 304 C_DHRPhnDetected 0 "Default" 1 "On (Detected)" 2 "Off" 3 "Invalid" ;
VAL_ 304 C_DHRDiagnostics 0 "No Error" 1 "DHS Internal Error" 2 "NFC Antenna Error" 4 "Overheating NFC" 8 "Overheating Lighting" 16 "Undervoltage" 32 "Overvoltage" 33 "0x21~0xFF:Reserved" 255 "0x21~0xFF:Reserved" ;
VAL_ 304 C_DHR_RainState 0 "Off" 1 "Rain" ;
VAL_ 353 C_UWB_FRNK_Decrypt_FB 0 "Default" 1 "Positive" 2 "Negative" 3 "Reserved" 4 "Reserved" 5 "Reserved" 6 "Reserved" 7 "Reserved" 8 "Reserved" 9 "Reserved" 10 "Reserved" 11 "Reserved" 12 "Reserved" 13 "Reserved" 14 "Reserved" 15 "Reserved" ;
VAL_ 357 Radar_ROA_ClassStat 0 "Default" 1 "Detect" 2 "Unknown" 3 "Empty" 4 "Reserved" 5 "Reserved" 6 "Reserved" 7 "Error indicator" ;
VAL_ 357 Radar_ROA_SnSrStat 0 "Default" 1 "Ready" 2 "Run" 3 "Done" 4 "Reserved" 5 "Reserved" 6 "Reserved" 7 "Error indicator" ;
VAL_ 357 Radar_ROA_DetInfo 0 "Default" 1 "Detect" 2 "Unknown" 3 "Empty" 4 "Reserved" 5 "Reserved" 6 "Reserved" 7 "Error indicator" ;
VAL_ 357 Radar_ROA_SnSrBlckgeErrStat 0 "Default" 1 "Blckge_error" 2 "Reserved" 3 "Reserved" ;
VAL_ 357 Radar_ROA_SnSrErrStat 0 "Default" 1 "Snsr_error" 2 "Reserved" 3 "Reserved" ;
VAL_ 357 Radar_ROA_RegionOpt 0 "Non Euro NCAP CPD" 1 "Euro NCAP CPD" 2 "Reserved" 3 "Error Indicator" ;
VAL_ 358 C_UWB_FRNK_IC_Bootloader 0 "Default" 1 "Success" 2 "Fail" 3 "0x3~0xFF:Invalid" 255 "0x3~0xFF:Invalid" ;
VAL_ 358 C_UWB_FRNK_IC_Flash_Erase 0 "Default" 1 "Success" 2 "Fail" 3 "0x3~0xFF:Invalid" 255 "0x3~0xFF:Invalid" ;
VAL_ 358 C_UWB_FRNK_IC_CRC32 0 "Default" 1 "Success" 2 "Fail" 3 "0x3~0xFF:Invalid" 255 "0x3~0xFF:Invalid" ;
VAL_ 362 C_UWB_FRNK_DTC 0 "Default(Virgin)" 1 "Learned" 2 "Neutralized" 3 "invalid" ;
VAL_ 362 C_UWB_FRUNK_Option 0 "Default(NotApplied)" 1 "Applied" 2 "Reseved" 3 "invalid" ;
VAL_ 367 C_UWB_FRNK_MCU_Bootloader 0 "Default" 1 "Success" 2 "Fail" 3 "0x3~0xFF:Invalid" 255 "0x3~0xFF:Invalid" ;
VAL_ 367 C_UWB_FRNK_MCU_Flash_Erase 0 "Default" 1 "Success" 2 "Fail" 3 "0x3~0xFF:Invalid" 255 "0x3~0xFF:Invalid" ;
VAL_ 367 C_UWB_FRNK_MCU_CRC32 0 "Default" 1 "Success" 2 "Fail" 3 "0x3~0xFF:Invalid" 255 "0x3~0xFF:Invalid" ;
VAL_ 368 C_UWB_FR_DTC 0 "Default(Virgin)" 1 "Learned" 2 "Neutralized" 3 "invalid" ;
VAL_ 368 C_UWB_FR_Option 0 "Default(NotApplied)" 1 "Applied" 2 "Reseved" 3 "invalid" ;
VAL_ 373 C_UWB_FL_MCU_Bootloader 0 "Default" 1 "Success" 2 "Fail" 3 "0x3~0xFF:Invalid" 255 "0x3~0xFF:Invalid" ;
VAL_ 373 C_UWB_FL_MCU_Flash_Erase 0 "Default" 1 "Success" 2 "Fail" 3 "0x3~0xFF:Invalid" 255 "0x3~0xFF:Invalid" ;
VAL_ 373 C_UWB_FL_MCU_CRC32 0 "Default" 1 "Success" 2 "Fail" 3 "0x3~0xFF:Invalid" 255 "0x3~0xFF:Invalid" ;
VAL_ 374 C_UWB_FL_IC_Bootloader 0 "Default" 1 "Success" 2 "Fail" 3 "0x3~0xFF:Invalid" 255 "0x3~0xFF:Invalid" ;
VAL_ 374 C_UWB_FL_IC_Flash_Erase 0 "Default" 1 "Success" 2 "Fail" 3 "0x3~0xFF:Invalid" 255 "0x3~0xFF:Invalid" ;
VAL_ 374 C_UWB_FL_IC_CRC32 0 "Default" 1 "Success" 2 "Fail" 3 "0x3~0xFF:Invalid" 255 "0x3~0xFF:Invalid" ;
VAL_ 375 C_UWB_FL_Decrypt_FB 0 "Default" 1 "Positive" 2 "Negative" 3 "Reserved" 4 "Reserved" 5 "Reserved" 6 "Reserved" 7 "Reserved" 8 "Reserved" 9 "Reserved" 10 "Reserved" 11 "Reserved" 12 "Reserved" 13 "Reserved" 14 "Reserved" 15 "Reserved" ;
VAL_ 376 C_UWB_FL_Option 0 "Default(NotApplied)" 1 "Applied" 2 "Reseved" 3 "invalid" ;
VAL_ 384 C_UWB_INT_DTC 0 "Default(Virgin)" 1 "Learned" 2 "Neutralized" 3 "invalid" ;
VAL_ 384 C_UWB_INT_Option 0 "Default(NotApplied)" 1 "Applied" 2 "Reseved" 3 "invalid" ;
VAL_ 387 C_UWB_FR_Decrypt_FB 0 "Default" 1 "Positive" 2 "Negative" 3 "Reserved" 4 "Reserved" 5 "Reserved" 6 "Reserved" 7 "Reserved" 8 "Reserved" 9 "Reserved" 10 "Reserved" 11 "Reserved" 12 "Reserved" 13 "Reserved" 14 "Reserved" 15 "Reserved" ;
VAL_ 389 C_UWB_FR_MCU_Bootloader 0 "Default" 1 "Success" 2 "Fail" 3 "0x3~0xFF:Invalid" 255 "0x3~0xFF:Invalid" ;
VAL_ 389 C_UWB_FR_MCU_Flash_Erase 0 "Default" 1 "Success" 2 "Fail" 3 "0x3~0xFF:Invalid" 255 "0x3~0xFF:Invalid" ;
VAL_ 389 C_UWB_FR_MCU_CRC32 0 "Default" 1 "Success" 2 "Fail" 3 "0x3~0xFF:Invalid" 255 "0x3~0xFF:Invalid" ;
VAL_ 390 C_UWB_FR_IC_Bootloader 0 "Default" 1 "Success" 2 "Fail" 3 "0x3~0xFF:Invalid" 255 "0x3~0xFF:Invalid" ;
VAL_ 390 C_UWB_FR_IC_Flash_Erase 0 "Default" 1 "Success" 2 "Fail" 3 "0x3~0xFF:Invalid" 255 "0x3~0xFF:Invalid" ;
VAL_ 390 C_UWB_FR_IC_CRC32 0 "Default" 1 "Success" 2 "Fail" 3 "0x3~0xFF:Invalid" 255 "0x3~0xFF:Invalid" ;
